VERSION ""

NS_ :

BS_:

BU_: ATCM_FFSM GENERIC_GWMWakeup IPMB Generic_BCM GWM _delete ABS_ESC HUD IPMA CCM PSCM SCCM TBM OCS TCCM TSTR RCM

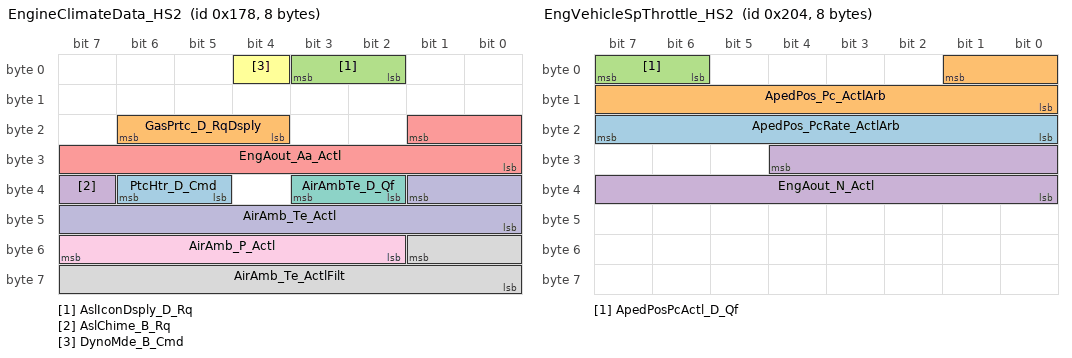
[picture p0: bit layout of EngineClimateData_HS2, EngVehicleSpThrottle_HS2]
BO_ 376 EngineClimateData_HS2: 8 GWM
 SG_ PtcHtr_D_Cmd : 38|2@0+ (1,0) [0|3] "SED" Vector__XXX
 SG_ GasPrtc_D_RqDsply : 22|3@0+ (1,0) [0|7] "SED" Vector__XXX
 SG_ AslIconDsply_D_Rq : 3|2@0+ (1,0) [0|3] "SED" Vector__XXX
 SG_ AslChime_B_Rq : 39|1@0+ (1,0) [0|1] "SED" Vector__XXX
 SG_ EngAout_Aa_Actl : 17|10@0+ (0.05,-25.6) [-25.6|25.55] "rpm/ms" Vector__XXX
 SG_ DynoMde_B_Cmd : 4|1@0+ (1,0) [0|1] "SED"  ABS_ESC
 SG_ AirAmbTe_D_Qf : 35|2@0+ (1,0) [0|3] "SED"  ABS_ESC,IPMA,TCCM,SCCM
 SG_ AirAmb_Te_ActlFilt : 49|10@0+ (0.25,-128) [-128|127.75] "deg C"  IPMA
 SG_ AirAmb_P_Actl : 55|6@0+ (10,500) [500|1110] "mbar" Vector__XXX
 SG_ AirAmb_Te_Actl : 33|10@0+ (0.25,-128) [-128|127.75] "degC"  ABS_ESC,TCCM,SCCM

BO_ 516 EngVehicleSpThrottle_HS2: 8 GWM
 SG_ ApedPos_PcRate_ActlArb : 23|8@0+ (0.04,-5) [-5|5.12] "%/ms" Vector__XXX
 SG_ ApedPos_Pc_ActlArb : 1|10@0+ (0.1,0) [0|102.3] "%"  IPMA,PSCM,TCCM,ABS_ESC,CCM,OCS,RCM
 SG_ ApedPosPcActl_D_Qf : 7|2@0+ (1,0) [0|3] "SED"  IPMA,PSCM,ABS_ESC,OCS,CCM,RCM
 SG_ EngAout_N_Actl : 28|13@0+ (2,0) [0|16382] "rpm"  PSCM,TCCM,ABS_ESC,RCM

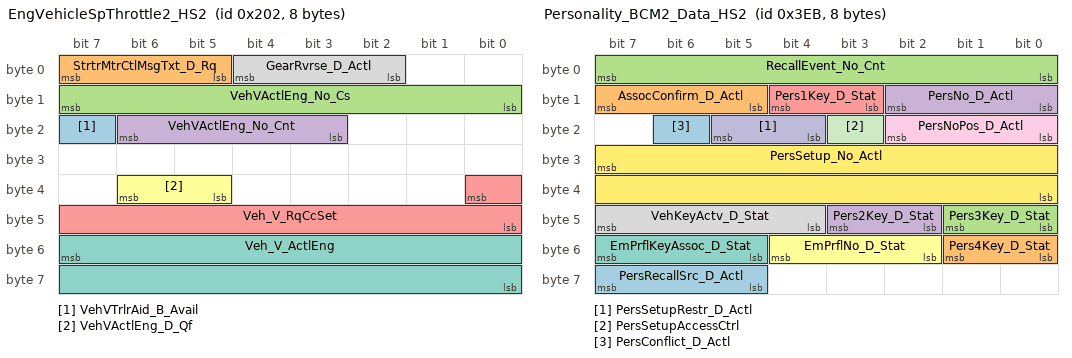
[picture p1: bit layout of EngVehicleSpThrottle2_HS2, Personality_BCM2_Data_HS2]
BO_ 514 EngVehicleSpThrottle2_HS2: 8 GWM
 SG_ VehVTrlrAid_B_Avail : 23|1@0+ (1,0) [0|1] "SED"  PSCM
 SG_ StrtrMtrCtlMsgTxt_D_Rq : 7|3@0+ (1,0) [0|7] "SED" Vector__XXX
 SG_ VehVActlEng_No_Cs : 15|8@0+ (1,0) [0|255] "Unitless"  PSCM
 SG_ VehVActlEng_No_Cnt : 22|4@0+ (1,0) [0|15] "Unitless"  PSCM
 SG_ Veh_V_RqCcSet : 32|9@0+ (0.5,0) [0|255.5] "kph"  IPMA,CCM
 SG_ VehVActlEng_D_Qf : 38|2@0+ (1,0) [0|3] "SED"  IPMB,ABS_ESC,SCCM,RCM,OCS,CCM,IPMA,PSCM,HUD
 SG_ Veh_V_ActlEng : 55|16@0+ (0.01,0) [0|655.35] "kph"  ABS_ESC,IPMB,TBM,RCM,OCS,CCM,SCCM,PSCM,IPMA,HUD
 SG_ GearRvrse_D_Actl : 4|3@0+ (1,0) [0|7] "SED"  ABS_ESC,IPMB,RCM,CCM,IPMA,OCS,SCCM,PSCM

BO_ 1003 Personality_BCM2_Data_HS2: 8 GWM
 SG_ PersRecallSrc_D_Actl : 63|3@0+ (1,0) [0|7] "SED" Vector__XXX
 SG_ Pers4Key_D_Stat : 49|2@0+ (1,0) [0|3] "SED" Vector__XXX
 SG_ Pers3Key_D_Stat : 41|2@0+ (1,0) [0|3] "SED" Vector__XXX
 SG_ Pers2Key_D_Stat : 43|2@0+ (1,0) [0|3] "SED" Vector__XXX
 SG_ Pers1Key_D_Stat : 12|2@0+ (1,0) [0|3] "SED" Vector__XXX
 SG_ EmPrflNo_D_Stat : 52|3@0+ (1,0) [0|7] "SED" Vector__XXX
 SG_ EmPrflKeyAssoc_D_Stat : 55|3@0+ (1,0) [0|7] "SED" Vector__XXX
 SG_ VehKeyActv_D_Stat : 47|4@0+ (1,0) [0|15] "SED" Vector__XXX
 SG_ PersNoPos_D_Actl : 18|3@0+ (1,0) [0|7] "SED" Vector__XXX
 SG_ PersSetupRestr_D_Actl : 21|2@0+ (1,0) [0|3] "SED"  CCM
 SG_ PersSetupAccessCtrl : 19|1@0+ (1,0) [0|1] "SED"  CCM
 SG_ PersSetup_No_Actl : 31|16@0+ (1,0) [0|65535] "Number"  CCM
 SG_ PersConflict_D_Actl : 22|1@0+ (1,0) [0|1] "SED" Vector__XXX
 SG_ AssocConfirm_D_Actl : 15|3@0+ (1,0) [0|7] "SED" Vector__XXX
 SG_ RecallEvent_No_Cnt : 7|8@0+ (1,0) [0|255] "Counts"  IPMA,CCM
 SG_ PersNo_D_Actl : 10|3@0+ (1,0) [0|7] "SED"  IPMA,CCM

BO_ 963 BCM_Lamp_Stat_HS2: 8 GWM
 SG_ WrlssAcsyChrgInhbt_B_Rq : 40|1@0+ (1,0) [0|1] "SED" Vector__XXX
 SG_ PudLampPsngr_D_Rq : 57|2@0+ (1,0) [0|3] "SED" Vector__XXX
 SG_ PudLampDrv_D_Rq : 59|2@0+ (1,0) [0|3] "SED" Vector__XXX
 SG_ Illuminated_Entry_Stat : 63|2@0+ (1,0) [0|3] "SED" Vector__XXX
 SG_ Dr_Courtesy_Light_Stat : 49|2@0+ (1,0) [0|3] "SED" Vector__XXX
 SG_ DrTgateLck_D_Stat : 61|2@0+ (1,0) [0|3] "SED" Vector__XXX
 SG_ Courtesy_Delay_Status : 51|2@0+ (1,0) [0|3] "SED" Vector__XXX
 SG_ ImpactEvntFdbck_D_Stat : 53|2@0+ (1,0) [0|3] "SED"  RCM
 SG_ HeadLampLoOut_B_Stat : 32|1@0+ (1,0) [0|1] "SED" Vector__XXX
 SG_ CrnrLghtRight_Pc_Rq : 47|7@0+ (1,0) [0|100] "percent" Vector__XXX
 SG_ CrnrLghtLeft_Pc_Rq : 39|7@0+ (1,0) [0|100] "percent" Vector__XXX
 SG_ HeadLghtHiFdbck_D_Stat : 55|2@0+ (1,0) [0|3] "SED"  SCCM
 SG_ PrkLightChime_B_Rq : 25|1@0+ (1,0) [0|1] "SED" Vector__XXX
 SG_ TrnNotInPrkChime_B_Rq : 24|1@0+ (1,0) [0|1] "SED" Vector__XXX
 SG_ KeyInIgnWarn_B_Cmd : 27|1@0+ (1,0) [0|1] "SED" Vector__XXX
 SG_ HomeSafeLtChime_B_Rq : 28|1@0+ (1,0) [0|1] "SED" Vector__XXX
 SG_ StopLghtOn_B_Stat : 8|1@0+ (1,0) [0|1] "SED" Vector__XXX
 SG_ RvrseLghtOn_B_Stat : 9|1@0+ (1,0) [0|1] "SED" Vector__XXX
 SG_ PrkLght_D_Stat : 13|2@0+ (1,0) [0|3] "SED" Vector__XXX
 SG_ HeadLghtSwtch_D_Stat : 15|2@0+ (1,0) [0|3] "SED"  IPMA
 SG_ HeadLampLoFrOn_B_Stat : 2|1@0+ (1,0) [0|1] "SED"  SCCM
 SG_ HeadLampLoFlOn_B_Stat : 3|1@0+ (1,0) [0|1] "SED"  SCCM
 SG_ HeadLampLoActv_B_Stat : 4|1@0+ (1,0) [0|1] "SED"  IPMA
 SG_ Headlamp_On_Wrning_Cmd : 29|1@0+ (1,0) [0|1] "SED" Vector__XXX
 SG_ HeadLghtHiOn_B_Stat : 1|1@0+ (1,0) [0|1] "SED"  IPMA
 SG_ Park_Brake_Chime_Rqst : 26|1@0+ (1,0) [0|1] "SED" Vector__XXX
 SG_ BrkWarnInd_B_Rq : 20|1@0+ (1,0) [0|1] "SED" Vector__XXX
 SG_ Brk_Fluid_Lvl_Low : 31|2@0+ (1,0) [0|3] "SED" Vector__XXX
 SG_ ReducedGuard_D_Stat : 19|2@0+ (1,0) [0|3] "SED" Vector__XXX
 SG_ Perimeter_Alarm_Status : 17|2@0+ (1,0) [0|3] "SED" Vector__XXX
 SG_ Courtesy_BSave_Stat : 7|2@0+ (1,0) [0|3] "SED" Vector__XXX
 SG_ DayRnngLampOn_B_Stat : 5|1@0+ (1,0) [0|1] "SED" Vector__XXX
 SG_ WndwGlbl_D_Cmd : 23|3@0+ (1,0) [0|7] "SED" Vector__XXX
 SG_ PudLamp_D_Rq : 11|2@0+ (1,0) [0|3] "SED" Vector__XXX
 SG_ PerimeterAlarmChimeRq : 0|1@0+ (1,0) [0|1] "SED" Vector__XXX

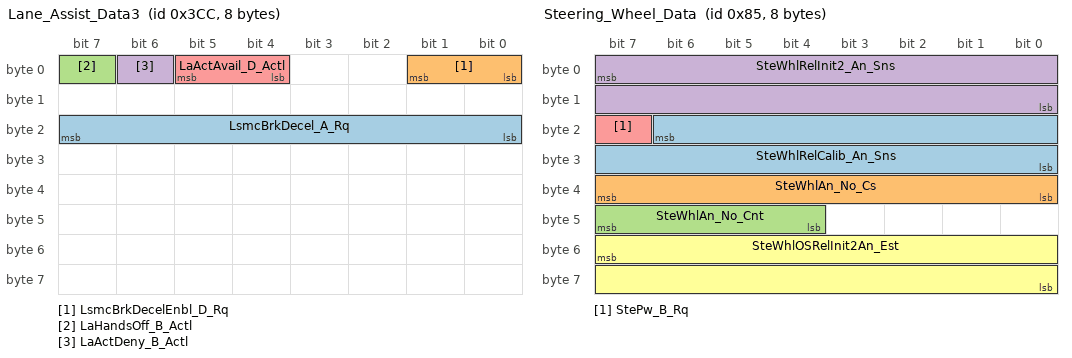
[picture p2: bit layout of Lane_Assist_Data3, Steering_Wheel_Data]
BO_ 972 Lane_Assist_Data3: 8 PSCM
 SG_ LsmcBrkDecel_A_Rq : 23|8@0+ (0.1,0) [0|25.5] "m/s^2"  ABS_ESC
 SG_ LsmcBrkDecelEnbl_D_Rq : 1|2@0+ (1,0) [0|3] "SED"  ABS_ESC
 SG_ LaHandsOff_B_Actl : 7|1@0+ (1,0) [0|1] "SED"  GWM,IPMA
 SG_ LaActDeny_B_Actl : 6|1@0+ (1,0) [0|1] "SED"  IPMA,GWM
 SG_ LaActAvail_D_Actl : 5|2@0+ (1,0) [0|3] "SED"  IPMA,GWM

BO_ 133 Steering_Wheel_Data: 8 PSCM
 SG_ SteWhlRelCalib_An_Sns : 22|15@0+ (0.1,-1600) [-1600|1676.5] "deg"  GWM
 SG_ SteWhlAn_No_Cs : 39|8@0+ (1,0) [0|255] "Unitless"  ABS_ESC,GWM
 SG_ SteWhlAn_No_Cnt : 47|4@0+ (1,0) [0|15] "Counts"  ABS_ESC,GWM
 SG_ SteWhlRelInit2_An_Sns : 7|16@0+ (0.1,-3200) [-3200|3353.3] "deg"  IPMA,SCCM,ABS_ESC,CCM,GWM
 SG_ StePw_B_Rq : 23|1@0+ (1,0) [0|1] "SED"  GWM
 SG_ SteWhlOSRelInit2An_Est : 55|16@0+ (0.1,-3200) [-3200|3353.3] "deg"  ABS_ESC,GWM

BO_ 1459 SCCM_AutoSar_Network_Mgmt: 8 SCCM
 SG_ SCCM_AutoSar_Network_Mgmt : 7|64@0+ (1,0) [0|1.84467E+019] "Unitless"  TCCM,TBM,ABS_ESC,GWM

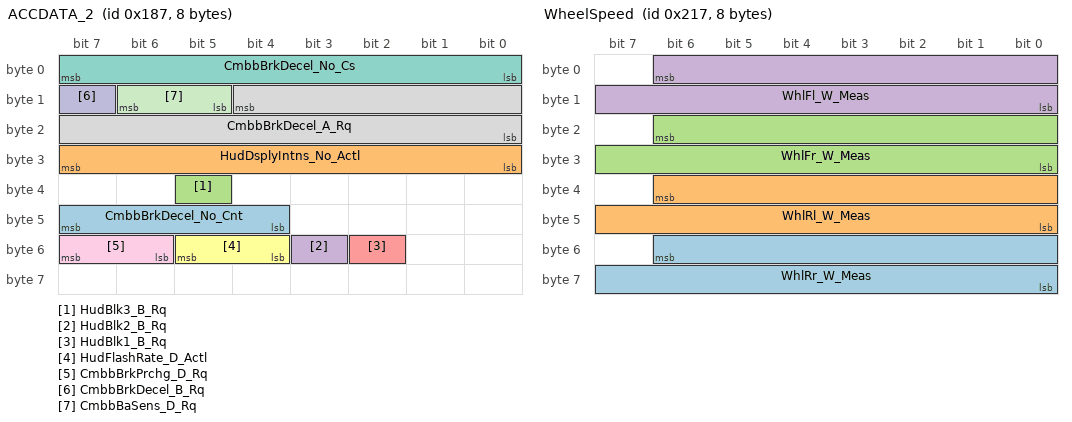
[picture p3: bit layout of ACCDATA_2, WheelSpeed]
BO_ 391 ACCDATA_2: 8 CCM
 SG_ CmbbBrkDecel_No_Cnt : 47|4@0+ (1,0) [0|15] "Unitless"  ABS_ESC
 SG_ HudDsplyIntns_No_Actl : 31|8@0+ (0.5,0) [0|100] "%"  HUD
 SG_ HudBlk3_B_Rq : 37|1@0+ (1,0) [0|1] "SED"  HUD
 SG_ HudBlk2_B_Rq : 51|1@0+ (1,0) [0|1] "SED"  HUD
 SG_ HudBlk1_B_Rq : 50|1@0+ (1,0) [0|1] "SED"  HUD
 SG_ HudFlashRate_D_Actl : 53|2@0+ (1,0) [0|3] "SED"  HUD
 SG_ CmbbBrkDecel_No_Cs : 7|8@0+ (1,0) [0|255] "Unitless"  ABS_ESC
 SG_ CmbbBrkDecel_A_Rq : 12|13@0+ (0.0039,-20) [-20|11.9449] "m/s^2"  GWM,ABS_ESC,RCM
 SG_ CmbbBrkPrchg_D_Rq : 55|2@0+ (1,0) [0|3] "SED"  GWM,ABS_ESC,RCM
 SG_ CmbbBrkDecel_B_Rq : 15|1@0+ (1,0) [0|1] "SED"  GWM,ABS_ESC,RCM
 SG_ CmbbBaSens_D_Rq : 14|2@0+ (1,0) [0|3] "SED"  ABS_ESC,RCM

BO_ 535 WheelSpeed: 8 ABS_ESC
 SG_ WhlRr_W_Meas : 54|15@0+ (0.01,0) [0|327.65] "rad/s"  IPMB,IPMA,TCCM,PSCM,GWM,CCM
 SG_ WhlRl_W_Meas : 38|15@0+ (0.01,0) [0|327.65] "rad/s"  IPMB,IPMA,TCCM,PSCM,GWM,CCM
 SG_ WhlFr_W_Meas : 22|15@0+ (0.01,0) [0|327.65] "rad/s"  IPMB,IPMA,TCCM,PSCM,GWM,CCM
 SG_ WhlFl_W_Meas : 6|15@0+ (0.01,0) [0|327.65] "rad/s"  IPMB,IPMA,TCCM,PSCM,GWM,CCM

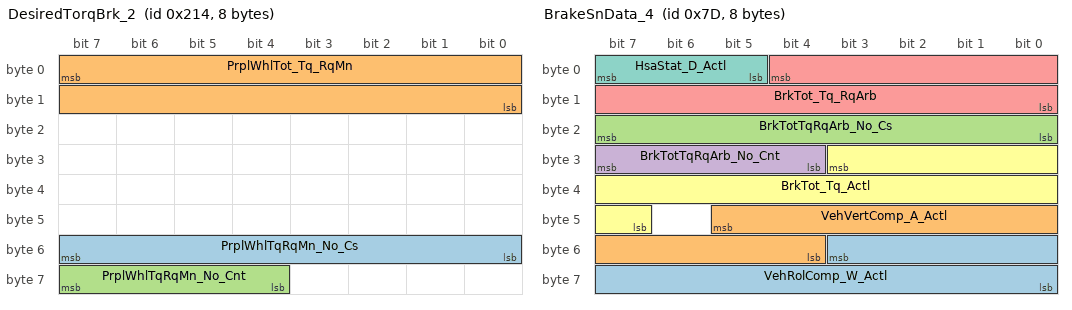
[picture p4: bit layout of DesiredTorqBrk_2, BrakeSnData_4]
BO_ 532 DesiredTorqBrk_2: 8 ABS_ESC
 SG_ PrplWhlTqRqMn_No_Cs : 55|8@0+ (1,0) [0|255] "Unitless"  GWM
 SG_ PrplWhlTot_Tq_RqMn : 7|16@0+ (4,-131072) [-131072|131068] "Nm"  GWM
 SG_ PrplWhlTqRqMn_No_Cnt : 63|4@0+ (1,0) [0|15] "Unitless"  GWM

BO_ 531 DesiredTorqBrk: 8 ABS_ESC
 SG_ VehicleStationary : 39|1@0+ (1,0) [0|1] "SED"  GWM,IPMA
 SG_ VehStop_D_Stat : 28|2@0+ (1,0) [0|3] "SED"  GWM,IPMA
 SG_ AccStopActv_B_ActlBrk : 22|1@0+ (1,0) [0|1] "SED"  GWM,IPMA
 SG_ AccDis_B_ActlEpb : 32|1@0+ (1,0) [0|1] "SED"  GWM,IPMA
 SG_ PrkBrkYwLamp_D_Rq : 38|2@0+ (1,0) [0|3] "SED"  GWM
 SG_ PrkBrkRedLamp_D_Rq : 30|2@0+ (1,0) [0|3] "SED"  GWM
 SG_ PrkBrkMsgTxt_D_Rq : 36|4@0+ (1,0) [0|15] "SED"  GWM
 SG_ TracCtlPtActv_B_Actl : 31|1@0+ (1,0) [0|1] "SED"  IPMA,GWM,TCCM,RCM,CCM
 SG_ AbsActv_B_Actl : 45|1@0+ (1,0) [0|1] "SED"  IPMA,TBM,RCM,CCM,GWM,PSCM
 SG_ StabCtlBrkActv_B_Actl : 23|1@0+ (1,0) [0|1] "SED"  IPMA,TCCM,PSCM,GWM,RCM,CCM
 SG_ CmbbBrkPrchg_B_Actl : 59|1@0+ (1,0) [0|1] "SED"  IPMA,TBM,GWM,CCM
 SG_ CmbbBrkDecel_B_Actl : 58|1@0+ (1,0) [0|1] "SED"  IPMA,TBM,GWM,CCM
 SG_ CmbbBaSensInc_B_Actl : 57|1@0+ (1,0) [0|1] "SED"  IPMA,GWM,CCM
 SG_ AccBrkWarm_B_Actl : 63|1@0+ (1,0) [0|1] "SED"  IPMA,GWM,CCM
 SG_ AccBrkTotTqMn_B_Actl : 62|1@0+ (1,0) [0|1] "SED"  IPMA,TBM,GWM,CCM
 SG_ AccBrkPrchgActv_B_Actl : 61|1@0+ (1,0) [0|1] "SED"  IPMA,GWM,CCM
 SG_ AccBrkDis_B_Actl : 44|1@0+ (1,0) [0|1] "SED"  IPMA,GWM,CCM
 SG_ AccBrkDeny_B_Actl : 42|1@0+ (1,0) [0|1] "SED"  IPMA,GWM,CCM
 SG_ AccBrkActv_B_Actl : 43|1@0+ (1,0) [0|1] "SED"  IPMA,GWM,CCM
 SG_ PrplDrgCtlActv_B_Actl : 46|1@0+ (1,0) [0|1] "SED"  GWM
 SG_ PrplWhlTot_Tq_RqMx : 7|16@0+ (4,-131072) [-131072|131068] "Nm"  TCCM,GWM
 SG_ CmbbBrkDis_B_Actl : 56|1@0+ (1,0) [0|1] "SED"  IPMA,GWM,CCM
 SG_ CmbbDeny_B_ActlBrk : 60|1@0+ (1,0) [0|1] "SED"  IPMA,GWM,CCM
 SG_ CcDis_B_Cmd : 47|1@0+ (1,0) [0|1] "SED"  GWM
 SG_ VehLongOvrGnd_A_Est : 41|10@0+ (0.035,-17.9) [-17.9|17.835] "m/s^2"  IPMA,TCCM,TBM,GWM,CCM
 SG_ PrkBrkStatus : 26|3@0+ (1,0) [0|7] "SED"  IPMB,IPMA,GWM

BO_ 2015 TesterFunctionalReq_H2: 8 TSTR
 SG_ TesterFunctionalReq : 7|64@0+ (1,0) [0|1.84467E+019] ""  ATCM_FFSM,IPMB,RCM,OCS,TCCM,CCM,ABS_ESC,HUD,IPMA,PSCM,SCCM,TBM,GWM

BO_ 125 BrakeSnData_4: 8 ABS_ESC
 SG_ VehRolComp_W_Actl : 51|12@0+ (0.03663,-75) [-75|74.92659] "degrees/sec"  PSCM,GWM
 SG_ VehVertComp_A_Actl : 45|10@0+ (0.035,-17.9) [-17.9|17.835] "m/s^2"  PSCM,GWM
 SG_ BrkTotTqRqArb_No_Cs : 23|8@0+ (1,0) [0|255] "Unitless"  TBM,GWM
 SG_ BrkTotTqRqArb_No_Cnt : 31|4@0+ (1,0) [0|15] "Unitless"  TBM,GWM
 SG_ BrkTot_Tq_RqArb : 4|13@0+ (4,0) [0|32756] "Nm"  IPMA,TBM,GWM,CCM
 SG_ BrkTot_Tq_Actl : 27|13@0+ (4,0) [0|32756] "Nm"  RCM,GWM
 SG_ HsaStat_D_Actl : 7|3@0+ (1,0) [0|7] "SED"  GWM

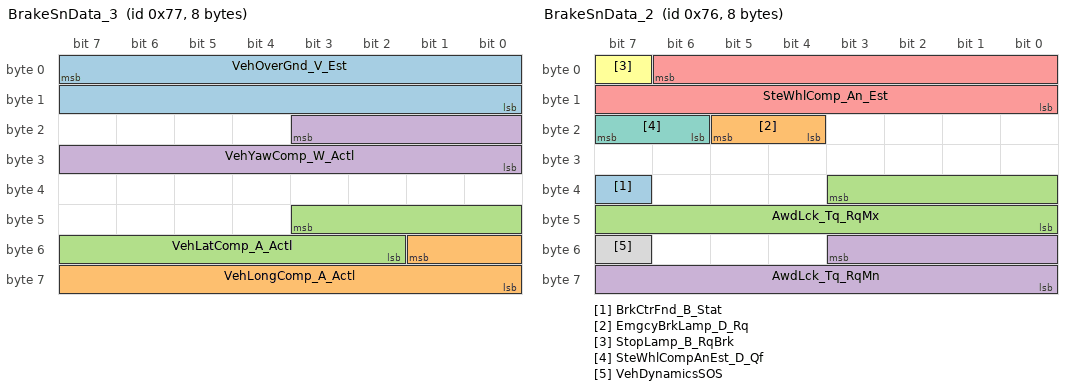
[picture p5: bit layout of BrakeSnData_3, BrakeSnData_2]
BO_ 119 BrakeSnData_3: 8 ABS_ESC
 SG_ VehOverGnd_V_Est : 7|16@0+ (0.01,0) [0|655.33] "kph"  IPMA,TCCM,GWM,CCM
 SG_ VehLongComp_A_Actl : 49|10@0+ (0.035,-17.9) [-17.9|17.835] "m/s^2"  PSCM,GWM
 SG_ VehLatComp_A_Actl : 43|10@0+ (0.035,-17.9) [-17.9|17.835] "m/s^2"  TCCM,PSCM,GWM
 SG_ VehYawComp_W_Actl : 19|12@0+ (0.03663,-75) [-75|74.92659] "deg/s"  IPMA,PSCM,GWM,CCM

BO_ 118 BrakeSnData_2: 8 ABS_ESC
 SG_ BrkCtrFnd_B_Stat : 39|1@0+ (1,0) [0|1] "SED"  PSCM,GWM
 SG_ EmgcyBrkLamp_D_Rq : 21|2@0+ (1,0) [0|3] "SED"  GWM
 SG_ AwdLck_Tq_RqMx : 35|12@0+ (1,0) [0|4095] "Nm"  TCCM,GWM
 SG_ AwdLck_Tq_RqMn : 51|12@0+ (1,0) [0|4095] "Nm"  TCCM,GWM
 SG_ SteWhlComp_An_Est : 6|15@0+ (0.1,-1600) [-1600|1676.7] "deg"  SCCM,IPMB,TCCM,RCM,IPMA,PSCM,GWM,CCM
 SG_ StopLamp_B_RqBrk : 7|1@0+ (1,0) [0|1] "SED"  GWM
 SG_ SteWhlCompAnEst_D_Qf : 23|2@0+ (1,0) [0|3] "SED"  SCCM,IPMB,TCCM,PSCM,GWM,IPMA,CCM
 SG_ VehDynamicsSOS : 55|1@0+ (1,0) [0|1] "SED"  GWM

BO_ 1713 ABS_Rapid_Data_Response_2: 8 ABS_ESC
 SG_ UUDTABSResponse2 : 7|64@0+ (1,0) [0|1.844674407371E+019] "unitless"  TSTR

BO_ 1712 ABS_Rapid_Data_Response_1: 8 ABS_ESC
 SG_ UUDTABSResponse1 : 7|64@0+ (1,0) [0|1.844674407371E+019] "unitless"  TSTR

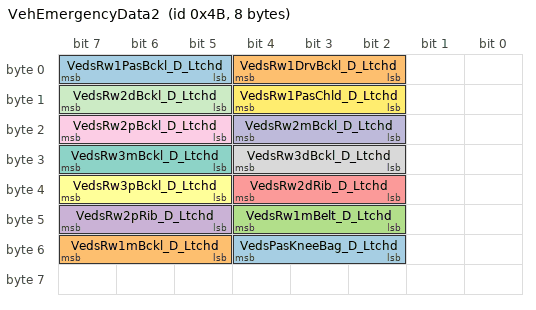
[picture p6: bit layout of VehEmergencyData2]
BO_ 75 VehEmergencyData2: 8 RCM
 SG_ VedsPasKneeBag_D_Ltchd : 52|3@0+ (1,0) [0|7] "SED"  GWM
 SG_ VedsRw1mBckl_D_Ltchd : 55|3@0+ (1,0) [0|7] "SED"  GWM
 SG_ VedsRw1mBelt_D_Ltchd : 44|3@0+ (1,0) [0|7] "SED"  GWM
 SG_ VedsRw2pRib_D_Ltchd : 47|3@0+ (1,0) [0|7] "SED"  GWM
 SG_ VedsRw2dRib_D_Ltchd : 36|3@0+ (1,0) [0|7] "SED"  GWM
 SG_ VedsRw3pBckl_D_Ltchd : 39|3@0+ (1,0) [0|7] "SED"  GWM
 SG_ VedsRw3mBckl_D_Ltchd : 31|3@0+ (1,0) [0|7] "SED"  GWM
 SG_ VedsRw3dBckl_D_Ltchd : 28|3@0+ (1,0) [0|7] "SED"  GWM
 SG_ VedsRw2pBckl_D_Ltchd : 23|3@0+ (1,0) [0|7] "SED"  GWM
 SG_ VedsRw2mBckl_D_Ltchd : 20|3@0+ (1,0) [0|7] "SED"  GWM
 SG_ VedsRw2dBckl_D_Ltchd : 15|3@0+ (1,0) [0|7] "SED"  GWM
 SG_ VedsRw1PasChld_D_Ltchd : 12|3@0+ (1,0) [0|7] "SED"  GWM
 SG_ VedsRw1PasBckl_D_Ltchd : 7|3@0+ (1,0) [0|7] "SED"  GWM
 SG_ VedsRw1DrvBckl_D_Ltchd : 4|3@0+ (1,0) [0|7] "SED"  GWM

BO_TX_BU_ 133 : SCCM,PSCM;
BO_TX_BU_ 391 : IPMA,CCM;
CM_ SG_ 376 EngAout_Aa_Actl "Signal not transmitted on HEV variants.";
CM_ SG_ 516 ApedPos_Pc_ActlArb "ABSGenSigTimeoutTime=1000";
CM_ SG_ 514 GearRvrse_D_Actl "Do not implement GearRvrse_D_Actl  until eTracker 8804151 is approved, 11/24/09";
CM_ SG_ 133 SteWhlRelCalib_An_Sns "Signal is not transmitted on vehicles where PSCM is transmitting the message that contains this signal.
Signal data set to 0x0 for ABS only vehicle option content";
CM_ SG_ 133 SteWhlAn_No_Cs "Signal data set to 0x0 for ABS only vehicle option content";
CM_ SG_ 133 SteWhlAn_No_Cnt "Signal data set to 0x0 for ABS only vehicle option content";
CM_ SG_ 391 CmbbBrkDecel_A_Rq "ABSGenSigTimeoutTime=1000";
CM_ SG_ 391 CmbbBrkPrchg_D_Rq "ABSGenSigTimeoutTime=1000";
CM_ SG_ 391 CmbbBrkDecel_B_Rq "ABSGenSigTimeoutTime=1000";
CM_ SG_ 391 CmbbBaSens_D_Rq "ABSGenSigTimeoutTime=1000";
CM_ BO_ 532 "IC is NOT to use data in this message for displays, Used data from 415 instead.";
CM_ BO_ 531 "IC is NOT to use data in this message for displays, Used data from 415 instead.";
CM_ SG_ 531 VehLongOvrGnd_A_Est "CCMGenSigTimeoutTime=1000";
CM_ BO_ 2015 "OBDII Request ($7DF) messages are for FNOS 1.0.1 only.
Diagnostic Functional Addressing ($7DF) and Dual Rate Periodic messages are for FNOS I3 only.";
BA_DEF_ SG_  "U_UP375_MY19_Gas_Rx" ENUM  "No","Yes";
BA_DEF_ SG_  "U_UP375_MY19_Diesel_Rx" ENUM  "No","Yes";
BA_DEF_ SG_  "U_V36X_MY19_Rx" ENUM  "No","Yes";
BA_DEF_ SG_  "U_UP375_MY19_Gas_Tx" ENUM  "No","Yes";
BA_DEF_ SG_  "U_UP375_MY19_Diesel_Tx" ENUM  "No","Yes";
BA_DEF_ SG_  "U_V36X_MY19_Tx" ENUM  "No","Yes";
BA_DEF_ SG_  "U_UP375_MY18_Gas_Rx" ENUM  "No","Yes";
BA_DEF_ SG_  "U_UP375_MY18_Diesel_Rx" ENUM  "No","Yes";
BA_DEF_ SG_  "U_V36X_MY18_5_Gas_Rx" ENUM  "No","Yes";
BA_DEF_ SG_  "U_V36X_MY18_5_Hev_Rx" ENUM  "No","Yes";
BA_DEF_ SG_  "U_UP375_MY18_Gas_Tx" ENUM  "No","Yes";
BA_DEF_ SG_  "U_UP375_MY18_Diesel_Tx" ENUM  "No","Yes";
BA_DEF_ SG_  "U_V36X_MY18_5_Gas_Tx" ENUM  "No","Yes";
BA_DEF_ SG_  "U_V36X_MY18_5_Hev_Tx" ENUM  "No","Yes";
BA_DEF_ SG_  "GenSigTimeoutTime_HCM_HS2" INT 0 100000;
BA_DEF_ SG_  "U_V36X_MY19_5_Diesel_Rx" ENUM  "No","Yes";
BA_DEF_ SG_  "U_V363E_N_MY19_5_20_Gas_Rx" ENUM  "No","Yes";
BA_DEF_ SG_  "U_V363E_N_MY19_5_20_Diesel_Rx" ENUM  "No","Yes";
BA_DEF_ SG_  "U_CD42_MY19_Diesel_Rx" ENUM  "No","Yes";
BA_DEF_ SG_  "U_CD42_MY19_Gas_Rx" ENUM  "No","Yes";
BA_DEF_ SG_  "U_V36X_MY19_5_Diesel_Tx" ENUM  "No","Yes";
BA_DEF_ SG_  "U_V363E_N_MY19_5_20_Gas_Tx" ENUM  "No","Yes";
BA_DEF_ SG_  "U_V363E_N_MY19_5_20_Diesel_Tx" ENUM  "No","Yes";
BA_DEF_ SG_  "U_CD42_MY19_Diesel_Tx" ENUM  "No","Yes";
BA_DEF_ SG_  "U_CD42_MY19_Gas_Tx" ENUM  "No","Yes";
BA_DEF_ BO_  "FrameGatewayNetworkold" ENUM  "None","HS1_CAN","HS2_CAN","HS3_CAN","MS1_CAN";
BA_DEF_ SG_  "U_B562_MY18_Gas_Rx" ENUM  "No","Yes";
BA_DEF_ SG_  "U_C490_MY18_Diesel_Rx" ENUM  "No","Yes";
BA_DEF_ SG_  "U_C490_MY18_Gas_Rx" ENUM  "No","Yes";
BA_DEF_ SG_  "U_V408_MY18_Gas_Rx" ENUM  "No","Yes";
BA_DEF_ SG_  "U_V408_MY18_Diesel_Rx" ENUM  "No","Yes";
BA_DEF_ SG_  "U_V36X_MY18_5_Diesel_Rx" ENUM  "No","Yes";
BA_DEF_ SG_  "U_V408_MY18_Gas_Tx" ENUM  "No","Yes";
BA_DEF_ SG_  "U_V408_MY18_Diesel_Tx" ENUM  "No","Yes";
BA_DEF_ SG_  "U_V36X_MY18_5_Diesel_Tx" ENUM  "No","Yes";
BA_DEF_ SG_  "U_P552_MY18_5_Gas_Tx" ENUM  "No","Yes";
BA_DEF_ SG_  "U_P552_MY18_5_Diesel_Tx" ENUM  "No","Yes";
BA_DEF_ SG_  "U_U502_MY17_Gas_Rx" ENUM  "No","Yes";
BA_DEF_ SG_  "U_S550_MY18_Gas_Rx" ENUM  "No","Yes";
BA_DEF_ SG_  "U_U502_MY17_Gas_Tx" ENUM  "No","Yes";
BA_DEF_ SG_  "U_S550_MY18_Gas_Tx" ENUM  "No","Yes";
BA_DEF_ SG_  "GenSigTimeoutTime_ATCM_FFSM" INT 0 100000;
BA_DEF_ SG_  "GenSigTimeoutTime_ATCM_DMSM" INT 0 100000;
BA_DEF_ SG_  "U_C489_MY17_Gas_Rx" ENUM  "No","Yes";
BA_DEF_ SG_  "U_P552_MY18_Gas_Rx" ENUM  "No","Yes";
BA_DEF_ SG_  "U_U55x_MY18_Gas_Rx" ENUM  "No","Yes";
BA_DEF_ SG_  "U_C489_MY17_Gas_Tx" ENUM  "No","Yes";
BA_DEF_ SG_  "U_P552_MY18_Gas_Tx" ENUM  "No","Yes";
BA_DEF_ SG_  "U_U55x_MY18_Gas_Tx" ENUM  "No","Yes";
BA_DEF_ BO_  "FrameGatewayNetwork" STRING ;
BA_DEF_ SG_  "U_CD43_MY17_Gas_Rx" ENUM  "No","Yes";
BA_DEF_ SG_  "U_P552_MY17_Gas_Rx" ENUM  "No","Yes";
BA_DEF_ SG_  "U_P552_MY17_Diesel_Rx" ENUM  "No","Yes";
BA_DEF_ SG_  "U_B515_MCA_MY17_Diesel_Rx" ENUM  "No","Yes";
BA_DEF_ SG_  "U_B515_MCA_MY17_Gas_Rx" ENUM  "No","Yes";
BA_DEF_ SG_  "U_CD43_MY17_Gas_Tx" ENUM  "No","Yes";
BA_DEF_ SG_  "U_P552_MY17_Gas_Tx" ENUM  "No","Yes";
BA_DEF_ SG_  "U_P552_MY17_Diesel_Tx" ENUM  "No","Yes";
BA_DEF_ SG_  "U_B515_MCA_MY17_Diesel_Tx" ENUM  "No","Yes";
BA_DEF_ SG_  "U_B515_MCA_MY17_Gas_Tx" ENUM  "No","Yes";
BA_DEF_ SG_  "U_B562LC_MY15_Diesel_Rx" ENUM  "No","Yes";
BA_DEF_ SG_  "U_B562LC_MY15_Gas_Rx" ENUM  "No","Yes";
BA_DEF_ SG_  "U_B479_MY17_Gas_Rx" ENUM  "No","Yes";
BA_DEF_ SG_  "U_B479_MY17_Diesel_Rx" ENUM  "No","Yes";
BA_DEF_ SG_  "U_CD4_MY17_Diesel_Rx" ENUM  "No","Yes";
BA_DEF_ SG_  "U_CD4_MY17_Gas_Rx" ENUM  "No","Yes";
BA_DEF_ SG_  "U_CD4_MY17_Hev_Rx" ENUM  "No","Yes";
BA_DEF_ SG_  "U_CD4_MY17_Phev_Rx" ENUM  "No","Yes";
BA_DEF_ SG_  "U_CD42_MY16_Diesel_Rx" ENUM  "No","Yes";
BA_DEF_ SG_  "U_CD42_MY16_Gas_Rx" ENUM  "No","Yes";
BA_DEF_ SG_  "U_B562LC_MY15_Diesel_Tx" ENUM  "No","Yes";
BA_DEF_ SG_  "U_B562LC_MY15_Gas_Tx" ENUM  "No","Yes";
BA_DEF_ SG_  "U_CD4_MY17_Diesel_Tx" ENUM  "No","Yes";
BA_DEF_ SG_  "U_CD4_MY17_Gas_Tx" ENUM  "No","Yes";
BA_DEF_ SG_  "U_CD4_MY17_Hev_Tx" ENUM  "No","Yes";
BA_DEF_ SG_  "U_CD4_MY17_Phev_Tx" ENUM  "No","Yes";
BA_DEF_ SG_  "U_CD42_MY16_Diesel_Tx" ENUM  "No","Yes";
BA_DEF_ SG_  "U_CD42_MY16_Gas_Tx" ENUM  "No","Yes";
BA_DEF_ SG_  "GenSigTimeoutTime_SECM" INT 0 100000;
BA_DEF_ BO_  "MessageGateway" ENUM  "No","Yes";
BA_DEF_ SG_  "U_CD42_MY15_Diesel_Rx" ENUM  "No","Yes";
BA_DEF_ SG_  "U_CD42_MY15_Gas_Rx" ENUM  "No","Yes";
BA_DEF_ SG_  "U_U502_MY16_Gas_Rx" ENUM  "No","Yes";
BA_DEF_ SG_  "U_P558_MY17_Gas_Rx" ENUM  "No","Yes";
BA_DEF_ SG_  "U_P558_MY17_Diesel_Rx" ENUM  "No","Yes";
BA_DEF_ SG_  "U_V36X_MY16_5_Diesel_Rx" ENUM  "No","Yes";
BA_DEF_ SG_  "U_CD42_MY15_Diesel_Tx" ENUM  "No","Yes";
BA_DEF_ SG_  "U_CD42_MY15_Gas_Tx" ENUM  "No","Yes";
BA_DEF_ SG_  "U_U502_MY16_Gas_Tx" ENUM  "No","Yes";
BA_DEF_ SG_  "U_P558_MY17_Gas_Tx" ENUM  "No","Yes";
BA_DEF_ SG_  "U_P558_MY17_Diesel_Tx" ENUM  "No","Yes";
BA_DEF_ SG_  "U_V36X_MY16_5_Diesel_Tx" ENUM  "No","Yes";
BA_DEF_ SG_  "GenSigTimeoutTime_VDM" INT 0 100000;
BA_DEF_ SG_  "GenSigTimeoutTime_ATCM" INT 0 100000;
BA_DEF_ SG_  "GenSigTimeoutTime_GENERIC" INT 0 100000;
BA_DEF_ SG_  "GenSigTimeoutTime_TRCM" INT 0 100000;
BA_DEF_ SG_  "GenSigTimeoutTime_GSM" INT 0 100000;
BA_DEF_ SG_  "GenSigTimeoutTime_FDSM" INT 0 100000;
BA_DEF_ SG_  "GenSigTimeoutTime_PCU" INT 0 100000;
BA_DEF_ SG_  "GenSigTimeoutTime_SASM" INT 0 100000;
BA_DEF_ SG_  "GenSigTimeoutTime_TCU_TBS" INT 0 100000;
BA_DEF_ SG_  "Gateway_ID" INT 0 0;
BA_DEF_ SG_  "GenSigTimeoutTime_IPMB" INT 0 100000;
BA_DEF_ SG_  "GenSigTimeoutTime__delete" INT 0 100000;
BA_DEF_ SG_  "GenSigTimeoutTime_PBM" INT 0 100000;
BA_DEF_ SG_  "GenSigTimeoutTime_TCCM" INT 0 100000;
BA_DEF_ SG_  "GenSigTimeoutTime_HUD" INT 0 100000;
BA_DEF_ SG_  "GenSigTimeoutTime_PSCM" INT 0 100000;
BA_DEF_ SG_  "GenSigTimeoutTime_SCCM" INT 0 100000;
BA_DEF_ SG_  "GenSigTimeoutTime_TBM" INT 0 100000;
BA_DEF_ SG_  "GenSigTimeoutTime_TSTR" INT 0 100000;
BA_DEF_ SG_  "GenSigTimeoutTime_IPMA" INT 0 100000;
BA_DEF_ SG_  "GenSigTimeoutTime_CCM" INT 0 100000;
BA_DEF_ SG_  "GenSigTimeoutTime_ABS_ESC" INT 0 100000;
BA_DEF_ SG_  "GenSigTimeoutTime_OCS" INT 0 100000;
BA_DEF_ SG_  "GenSigTimeoutTime_GWM" INT 0 100000;
BA_DEF_ SG_  "GenSigTimeoutTime_RCM" INT 0 100000;
BA_DEF_ BO_  "FrameGatewayMS1" HEX 0 1407;
BA_DEF_ BO_  "FrameGatewayHS3" HEX 0 1407;
BA_DEF_ BO_  "FrameGatewayHS1" HEX 0 1407;
BA_DEF_ BO_  "NetworkInitialization" ENUM  "No","Yes";
BA_DEF_ BO_  "FrameGatewayId" HEX 0 1407;
BA_DEF_ BO_  "EventRateOfChange" INT 10 10000;
BA_DEF_ BO_  "GenMsgStartDelayTime" INT 0 10000;
BA_DEF_ BO_  "GenMsgNrOfRepetition" INT 0 100;
BA_DEF_ BO_  "GenMsgDelayTime" INT 0 1000;
BA_DEF_ BO_  "GenMsgCycleTime" INT 0 100000;
BA_DEF_ BO_  "GenMsgSendType" ENUM  "FixedPeriodic","Event","EnabledPeriodic","NotUsed","NotUsed","EventPeriodic","NotUsed","NotUsed","NoMsgSendType";
BA_DEF_ SG_  "U_CD4_MY14_Phev_Tx" ENUM  "No","Yes";
BA_DEF_ SG_  "U_CD4_MY14_Hev_Tx" ENUM  "No","Yes";
BA_DEF_ SG_  "U_CD4_MY14_Gas_Tx" ENUM  "No","Yes";
BA_DEF_ SG_  "U_CD4_MY14_Diesel_Tx" ENUM  "No","Yes";
BA_DEF_ SG_  "U_CD43_MY16_Gas_Tx" ENUM  "No","Yes";
BA_DEF_ SG_  "U_C490LC_MY15_Gas_Tx" ENUM  "No","Yes";
BA_DEF_ SG_  "U_UP375_MY15_Diesel_Tx" ENUM  "No","Yes";
BA_DEF_ SG_  "U_UP375_MY15_Gas_Tx" ENUM  "No","Yes";
BA_DEF_ SG_  "U_U502_MY15_Gas_Tx" ENUM  "No","Yes";
BA_DEF_ SG_  "U_B562LC_MY14_Gas_Tx" ENUM  "No","Yes";
BA_DEF_ SG_  "U_B562LC_MY14_Diesel_Tx" ENUM  "No","Yes";
BA_DEF_ SG_  "U_C489_MY14_Gas_Tx" ENUM  "No","Yes";
BA_DEF_ SG_  "U_S550_MY15_Gas_Tx" ENUM  "No","Yes";
BA_DEF_ SG_  "U_P552_MY15_Gas_Tx" ENUM  "No","Yes";
BA_DEF_ SG_  "U_CD42_MY14_Gas_Tx" ENUM  "No","Yes";
BA_DEF_ SG_  "U_CD42_MY14_Diesel_Tx" ENUM  "No","Yes";
BA_DEF_ SG_  "U_CD4_MY13_Phev_Tx" ENUM  "No","Yes";
BA_DEF_ SG_  "U_CD4_MY13_Hev_Tx" ENUM  "No","Yes";
BA_DEF_ SG_  "U_CD4_MY13_Gas_Tx" ENUM  "No","Yes";
BA_DEF_ SG_  "U_CD4_MY13_Diesel_Tx" ENUM  "No","Yes";
BA_DEF_ SG_  "U_CD4_MY14_Phev_Rx" ENUM  "No","Yes";
BA_DEF_ SG_  "U_CD4_MY14_Hev_Rx" ENUM  "No","Yes";
BA_DEF_ SG_  "U_CD4_MY14_Gas_Rx" ENUM  "No","Yes";
BA_DEF_ SG_  "U_CD4_MY14_Diesel_Rx" ENUM  "No","Yes";
BA_DEF_ SG_  "U_CD43_MY16_Gas_Rx" ENUM  "No","Yes";
BA_DEF_ SG_  "U_UP375_MY15_Diesel_Rx" ENUM  "No","Yes";
BA_DEF_ SG_  "U_UP375_MY15_Gas_Rx" ENUM  "No","Yes";
BA_DEF_ SG_  "U_B479_MY15_Gas_Rx" ENUM  "No","Yes";
BA_DEF_ SG_  "U_U502_MY15_Gas_Rx" ENUM  "No","Yes";
BA_DEF_ SG_  "U_B562LC_MY14_Gas_Rx" ENUM  "No","Yes";
BA_DEF_ SG_  "U_B562LC_MY14_Diesel_Rx" ENUM  "No","Yes";
BA_DEF_ SG_  "U_C489_MY14_Gas_Rx" ENUM  "No","Yes";
BA_DEF_ SG_  "U_S550_MY15_Gas_Rx" ENUM  "No","Yes";
BA_DEF_ SG_  "U_P552_MY15_Gas_Rx" ENUM  "No","Yes";
BA_DEF_ SG_  "U_CD42_MY14_Gas_Rx" ENUM  "No","Yes";
BA_DEF_ SG_  "U_CD42_MY14_Diesel_Rx" ENUM  "No","Yes";
BA_DEF_ SG_  "U_CD4_MY13_Phev_Rx" ENUM  "No","Yes";
BA_DEF_ SG_  "U_CD4_MY13_Hev_Rx" ENUM  "No","Yes";
BA_DEF_ SG_  "U_CD4_MY13_Gas_Rx" ENUM  "No","Yes";
BA_DEF_ SG_  "U_CD4_MY13_Diesel_Rx" ENUM  "No","Yes";
BA_DEF_ SG_  "ContentDependant" ENUM  "No","Yes";
BA_DEF_ SG_  "GenSigStartValue" INT 0 1000000000;
BA_DEF_ SG_  "UsedOnPgmDBC" ENUM  "No","Yes";
BA_DEF_ SG_  "CrossOver_LIN" ENUM  "No","Yes";
BA_DEF_ SG_  "CrossOver_InfoCAN" ENUM  "No","Yes";
BA_DEF_ SG_  "WakeupSignal" ENUM  "No","Yes";
BA_DEF_ SG_  "FMC_SIG_SSPEC" STRING ;
BA_DEF_ SG_  "GenSigMissingSourceValue" INT 0 1000000000;
BA_DEF_ SG_  "GenSigSendType" ENUM  "Cyclic","OnWrite","vector_leerstring","OnChange","vector_leerstring","IfActive","vector_leerstring","NoSigSendType";
BA_DEF_ BO_  "NmAsrMessage" ENUM  "No","Yes";
BA_DEF_ BO_  "TpApplType" STRING ;
BA_DEF_ BO_  "DiagState" ENUM  "No","Yes";
BA_DEF_ BO_  "DiagRequest" ENUM  "No","Yes";
BA_DEF_ BO_  "DiagResponse" ENUM  "No","Yes";
BA_DEF_ BO_  "GenMsgILSupport" ENUM  "No","Yes";
BA_DEF_DEF_  "U_UP375_MY19_Gas_Rx" "No";
BA_DEF_DEF_  "U_UP375_MY19_Diesel_Rx" "No";
BA_DEF_DEF_  "U_V36X_MY19_Rx" "No";
BA_DEF_DEF_  "U_UP375_MY19_Gas_Tx" "No";
BA_DEF_DEF_  "U_UP375_MY19_Diesel_Tx" "No";
BA_DEF_DEF_  "U_V36X_MY19_Tx" "No";
BA_DEF_DEF_  "U_UP375_MY18_Gas_Rx" "No";
BA_DEF_DEF_  "U_UP375_MY18_Diesel_Rx" "No";
BA_DEF_DEF_  "U_V36X_MY18_5_Gas_Rx" "No";
BA_DEF_DEF_  "U_V36X_MY18_5_Hev_Rx" "No";
BA_DEF_DEF_  "U_UP375_MY18_Gas_Tx" "No";
BA_DEF_DEF_  "U_UP375_MY18_Diesel_Tx" "No";
BA_DEF_DEF_  "U_V36X_MY18_5_Gas_Tx" "No";
BA_DEF_DEF_  "U_V36X_MY18_5_Hev_Tx" "No";
BA_DEF_DEF_  "GenSigTimeoutTime_HCM_HS2" 5000;
BA_DEF_DEF_  "U_V36X_MY19_5_Diesel_Rx" "No";
BA_DEF_DEF_  "U_V363E_N_MY19_5_20_Gas_Rx" "No";
BA_DEF_DEF_  "U_V363E_N_MY19_5_20_Diesel_Rx" "No";
BA_DEF_DEF_  "U_CD42_MY19_Diesel_Rx" "No";
BA_DEF_DEF_  "U_CD42_MY19_Gas_Rx" "No";
BA_DEF_DEF_  "U_V36X_MY19_5_Diesel_Tx" "No";
BA_DEF_DEF_  "U_V363E_N_MY19_5_20_Gas_Tx" "No";
BA_DEF_DEF_  "U_V363E_N_MY19_5_20_Diesel_Tx" "No";
BA_DEF_DEF_  "U_CD42_MY19_Diesel_Tx" "No";
BA_DEF_DEF_  "U_CD42_MY19_Gas_Tx" "No";
BA_DEF_DEF_  "FrameGatewayNetworkold" "None";
BA_DEF_DEF_  "U_B562_MY18_Gas_Rx" "No";
BA_DEF_DEF_  "U_C490_MY18_Diesel_Rx" "No";
BA_DEF_DEF_  "U_C490_MY18_Gas_Rx" "No";
BA_DEF_DEF_  "U_V408_MY18_Gas_Rx" "No";
BA_DEF_DEF_  "U_V408_MY18_Diesel_Rx" "No";
BA_DEF_DEF_  "U_V36X_MY18_5_Diesel_Rx" "No";
BA_DEF_DEF_  "U_V408_MY18_Gas_Tx" "No";
BA_DEF_DEF_  "U_V408_MY18_Diesel_Tx" "No";
BA_DEF_DEF_  "U_V36X_MY18_5_Diesel_Tx" "No";
BA_DEF_DEF_  "U_P552_MY18_5_Gas_Tx" "No";
BA_DEF_DEF_  "U_P552_MY18_5_Diesel_Tx" "No";
BA_DEF_DEF_  "U_U502_MY17_Gas_Rx" "No";
BA_DEF_DEF_  "U_S550_MY18_Gas_Rx" "No";
BA_DEF_DEF_  "U_U502_MY17_Gas_Tx" "No";
BA_DEF_DEF_  "U_S550_MY18_Gas_Tx" "No";
BA_DEF_DEF_  "GenSigTimeoutTime_ATCM_FFSM" 5000;
BA_DEF_DEF_  "GenSigTimeoutTime_ATCM_DMSM" 5000;
BA_DEF_DEF_  "U_C489_MY17_Gas_Rx" "No";
BA_DEF_DEF_  "U_P552_MY18_Gas_Rx" "No";
BA_DEF_DEF_  "U_U55x_MY18_Gas_Rx" "No";
BA_DEF_DEF_  "U_C489_MY17_Gas_Tx" "No";
BA_DEF_DEF_  "U_P552_MY18_Gas_Tx" "No";
BA_DEF_DEF_  "U_U55x_MY18_Gas_Tx" "No";
BA_DEF_DEF_  "FrameGatewayNetwork" "NONE";
BA_DEF_DEF_  "U_CD43_MY17_Gas_Rx" "No";
BA_DEF_DEF_  "U_P552_MY17_Gas_Rx" "No";
BA_DEF_DEF_  "U_P552_MY17_Diesel_Rx" "No";
BA_DEF_DEF_  "U_B515_MCA_MY17_Diesel_Rx" "No";
BA_DEF_DEF_  "U_B515_MCA_MY17_Gas_Rx" "No";
BA_DEF_DEF_  "U_CD43_MY17_Gas_Tx" "No";
BA_DEF_DEF_  "U_P552_MY17_Gas_Tx" "No";
BA_DEF_DEF_  "U_P552_MY17_Diesel_Tx" "No";
BA_DEF_DEF_  "U_B515_MCA_MY17_Diesel_Tx" "No";
BA_DEF_DEF_  "U_B515_MCA_MY17_Gas_Tx" "No";
BA_DEF_DEF_  "U_B562LC_MY15_Diesel_Rx" "No";
BA_DEF_DEF_  "U_B562LC_MY15_Gas_Rx" "No";
BA_DEF_DEF_  "U_B479_MY17_Gas_Rx" "No";
BA_DEF_DEF_  "U_B479_MY17_Diesel_Rx" "No";
BA_DEF_DEF_  "U_CD4_MY17_Diesel_Rx" "No";
BA_DEF_DEF_  "U_CD4_MY17_Gas_Rx" "No";
BA_DEF_DEF_  "U_CD4_MY17_Hev_Rx" "No";
BA_DEF_DEF_  "U_CD4_MY17_Phev_Rx" "No";
BA_DEF_DEF_  "U_CD42_MY16_Diesel_Rx" "No";
BA_DEF_DEF_  "U_CD42_MY16_Gas_Rx" "No";
BA_DEF_DEF_  "U_B562LC_MY15_Diesel_Tx" "No";
BA_DEF_DEF_  "U_B562LC_MY15_Gas_Tx" "No";
BA_DEF_DEF_  "U_CD4_MY17_Diesel_Tx" "No";
BA_DEF_DEF_  "U_CD4_MY17_Gas_Tx" "No";
BA_DEF_DEF_  "U_CD4_MY17_Hev_Tx" "No";
BA_DEF_DEF_  "U_CD4_MY17_Phev_Tx" "No";
BA_DEF_DEF_  "U_CD42_MY16_Diesel_Tx" "No";
BA_DEF_DEF_  "U_CD42_MY16_Gas_Tx" "No";
BA_DEF_DEF_  "GenSigTimeoutTime_SECM" 5000;
BA_DEF_DEF_  "MessageGateway" "No";
BA_DEF_DEF_  "U_CD42_MY15_Diesel_Rx" "No";
BA_DEF_DEF_  "U_CD42_MY15_Gas_Rx" "No";
BA_DEF_DEF_  "U_U502_MY16_Gas_Rx" "No";
BA_DEF_DEF_  "U_P558_MY17_Gas_Rx" "No";
BA_DEF_DEF_  "U_P558_MY17_Diesel_Rx" "No";
BA_DEF_DEF_  "U_V36X_MY16_5_Diesel_Rx" "No";
BA_DEF_DEF_  "U_CD42_MY15_Diesel_Tx" "No";
BA_DEF_DEF_  "U_CD42_MY15_Gas_Tx" "No";
BA_DEF_DEF_  "U_U502_MY16_Gas_Tx" "No";
BA_DEF_DEF_  "U_P558_MY17_Gas_Tx" "No";
BA_DEF_DEF_  "U_P558_MY17_Diesel_Tx" "No";
BA_DEF_DEF_  "U_V36X_MY16_5_Diesel_Tx" "No";
BA_DEF_DEF_  "GenSigTimeoutTime_VDM" 5000;
BA_DEF_DEF_  "GenSigTimeoutTime_ATCM" 5000;
BA_DEF_DEF_  "GenSigTimeoutTime_GENERIC" 5000;
BA_DEF_DEF_  "GenSigTimeoutTime_TRCM" 5000;
BA_DEF_DEF_  "GenSigTimeoutTime_GSM" 5000;
BA_DEF_DEF_  "GenSigTimeoutTime_FDSM" 5000;
BA_DEF_DEF_  "GenSigTimeoutTime_PCU" 5000;
BA_DEF_DEF_  "GenSigTimeoutTime_SASM" 5000;
BA_DEF_DEF_  "GenSigTimeoutTime_TCU_TBS" 5000;
BA_DEF_DEF_  "Gateway_ID" 0;
BA_DEF_DEF_  "GenSigTimeoutTime_IPMB" 5000;
BA_DEF_DEF_  "GenSigTimeoutTime__delete" 5000;
BA_DEF_DEF_  "GenSigTimeoutTime_PBM" 5000;
BA_DEF_DEF_  "GenSigTimeoutTime_TCCM" 5000;
BA_DEF_DEF_  "GenSigTimeoutTime_HUD" 5000;
BA_DEF_DEF_  "GenSigTimeoutTime_PSCM" 5000;
BA_DEF_DEF_  "GenSigTimeoutTime_SCCM" 5000;
BA_DEF_DEF_  "GenSigTimeoutTime_TBM" 5000;
BA_DEF_DEF_  "GenSigTimeoutTime_TSTR" 5000;
BA_DEF_DEF_  "GenSigTimeoutTime_IPMA" 5000;
BA_DEF_DEF_  "GenSigTimeoutTime_CCM" 5000;
BA_DEF_DEF_  "GenSigTimeoutTime_ABS_ESC" 5000;
BA_DEF_DEF_  "GenSigTimeoutTime_OCS" 5000;
BA_DEF_DEF_  "GenSigTimeoutTime_GWM" 5000;
BA_DEF_DEF_  "GenSigTimeoutTime_RCM" 5000;
BA_DEF_DEF_  "FrameGatewayMS1" 0;
BA_DEF_DEF_  "FrameGatewayHS3" 0;
BA_DEF_DEF_  "FrameGatewayHS1" 0;
BA_DEF_DEF_  "NetworkInitialization" "No";
BA_DEF_DEF_  "FrameGatewayId" 0;
BA_DEF_DEF_  "EventRateOfChange" 10000;
BA_DEF_DEF_  "GenMsgStartDelayTime" 0;
BA_DEF_DEF_  "GenMsgNrOfRepetition" 1;
BA_DEF_DEF_  "GenMsgDelayTime" 20;
BA_DEF_DEF_  "GenMsgCycleTime" 0;
BA_DEF_DEF_  "GenMsgSendType" "NoMsgSendType";
BA_DEF_DEF_  "U_CD4_MY14_Phev_Tx" "No";
BA_DEF_DEF_  "U_CD4_MY14_Hev_Tx" "No";
BA_DEF_DEF_  "U_CD4_MY14_Gas_Tx" "No";
BA_DEF_DEF_  "U_CD4_MY14_Diesel_Tx" "No";
BA_DEF_DEF_  "U_CD43_MY16_Gas_Tx" "No";
BA_DEF_DEF_  "U_C490LC_MY15_Gas_Tx" "No";
BA_DEF_DEF_  "U_UP375_MY15_Diesel_Tx" "No";
BA_DEF_DEF_  "U_UP375_MY15_Gas_Tx" "No";
BA_DEF_DEF_  "U_U502_MY15_Gas_Tx" "No";
BA_DEF_DEF_  "U_B562LC_MY14_Gas_Tx" "No";
BA_DEF_DEF_  "U_B562LC_MY14_Diesel_Tx" "No";
BA_DEF_DEF_  "U_C489_MY14_Gas_Tx" "No";
BA_DEF_DEF_  "U_S550_MY15_Gas_Tx" "No";
BA_DEF_DEF_  "U_P552_MY15_Gas_Tx" "No";
BA_DEF_DEF_  "U_CD42_MY14_Gas_Tx" "No";
BA_DEF_DEF_  "U_CD42_MY14_Diesel_Tx" "No";
BA_DEF_DEF_  "U_CD4_MY13_Phev_Tx" "No";
BA_DEF_DEF_  "U_CD4_MY13_Hev_Tx" "No";
BA_DEF_DEF_  "U_CD4_MY13_Gas_Tx" "No";
BA_DEF_DEF_  "U_CD4_MY13_Diesel_Tx" "No";
BA_DEF_DEF_  "U_CD4_MY14_Phev_Rx" "No";
BA_DEF_DEF_  "U_CD4_MY14_Hev_Rx" "No";
BA_DEF_DEF_  "U_CD4_MY14_Gas_Rx" "No";
BA_DEF_DEF_  "U_CD4_MY14_Diesel_Rx" "No";
BA_DEF_DEF_  "U_CD43_MY16_Gas_Rx" "No";
BA_DEF_DEF_  "U_UP375_MY15_Diesel_Rx" "No";
BA_DEF_DEF_  "U_UP375_MY15_Gas_Rx" "No";
BA_DEF_DEF_  "U_B479_MY15_Gas_Rx" "No";
BA_DEF_DEF_  "U_U502_MY15_Gas_Rx" "No";
BA_DEF_DEF_  "U_B562LC_MY14_Gas_Rx" "No";
BA_DEF_DEF_  "U_B562LC_MY14_Diesel_Rx" "No";
BA_DEF_DEF_  "U_C489_MY14_Gas_Rx" "No";
BA_DEF_DEF_  "U_S550_MY15_Gas_Rx" "No";
BA_DEF_DEF_  "U_P552_MY15_Gas_Rx" "No";
BA_DEF_DEF_  "U_CD42_MY14_Gas_Rx" "No";
BA_DEF_DEF_  "U_CD42_MY14_Diesel_Rx" "No";
BA_DEF_DEF_  "U_CD4_MY13_Phev_Rx" "No";
BA_DEF_DEF_  "U_CD4_MY13_Hev_Rx" "No";
BA_DEF_DEF_  "U_CD4_MY13_Gas_Rx" "No";
BA_DEF_DEF_  "U_CD4_MY13_Diesel_Rx" "No";
BA_DEF_DEF_  "ContentDependant" "No";
BA_DEF_DEF_  "GenSigStartValue" 0;
BA_DEF_DEF_  "UsedOnPgmDBC" "Yes";
BA_DEF_DEF_  "CrossOver_LIN" "No";
BA_DEF_DEF_  "CrossOver_InfoCAN" "No";
BA_DEF_DEF_  "WakeupSignal" "No";
BA_DEF_DEF_  "FMC_SIG_SSPEC" "Unknown";
BA_DEF_DEF_  "GenSigMissingSourceValue" 0;
BA_DEF_DEF_  "GenSigSendType" "NoSigSendType";
BA_DEF_DEF_  "NmAsrMessage" "No";
BA_DEF_DEF_  "TpApplType" "";
BA_DEF_DEF_  "DiagState" "No";
BA_DEF_DEF_  "DiagRequest" "No";
BA_DEF_DEF_  "DiagResponse" "No";
BA_DEF_DEF_  "GenMsgILSupport" "Yes";
BA_ "NetworkInitialization" BO_ 376 1;
BA_ "GenMsgStartDelayTime" BO_ 376 300;
BA_ "FrameGatewayId" BO_ 376 376;
BA_ "FrameGatewayHS1" BO_ 376 376;
BA_ "FrameGatewayNetwork" BO_ 376 "HS1_CAN";
BA_ "GenMsgDelayTime" BO_ 516 5;
BA_ "FrameGatewayId" BO_ 516 516;
BA_ "FrameGatewayHS1" BO_ 516 516;
BA_ "FrameGatewayNetwork" BO_ 516 "HS1_CAN";
BA_ "GenMsgDelayTime" BO_ 514 5;
BA_ "FrameGatewayId" BO_ 514 514;
BA_ "FrameGatewayHS1" BO_ 514 514;
BA_ "FrameGatewayNetwork" BO_ 514 "HS1_CAN";
BA_ "FrameGatewayId" BO_ 1003 1003;
BA_ "FrameGatewayHS1" BO_ 1003 1003;
BA_ "FrameGatewayNetwork" BO_ 1003 "HS1_CAN";
BA_ "NetworkInitialization" BO_ 1003 1;
BA_ "GenMsgStartDelayTime" BO_ 963 300;
BA_ "FrameGatewayId" BO_ 963 963;
BA_ "FrameGatewayHS1" BO_ 963 963;
BA_ "FrameGatewayNetwork" BO_ 963 "HS1_CAN";
BA_ "NetworkInitialization" BO_ 963 1;
BA_ "GenMsgSendType" BO_ 972 0;
BA_ "GenMsgCycleTime" BO_ 972 30;
BA_ "GenMsgDelayTime" BO_ 972 10;
BA_ "GenMsgSendType" BO_ 133 0;
BA_ "GenMsgCycleTime" BO_ 133 10;
BA_ "GenMsgDelayTime" BO_ 133 0;
BA_ "MessageGateway" BO_ 133 1;
BA_ "NetworkInitialization" BO_ 133 1;
BA_ "GenMsgILSupport" BO_ 1459 0;
BA_ "NmAsrMessage" BO_ 1459 1;
BA_ "GenMsgSendType" BO_ 1459 1;
BA_ "GenMsgSendType" BO_ 391 0;
BA_ "GenMsgCycleTime" BO_ 391 20;
BA_ "GenMsgDelayTime" BO_ 391 10;
BA_ "NetworkInitialization" BO_ 391 1;
BA_ "GenMsgSendType" BO_ 535 0;
BA_ "GenMsgCycleTime" BO_ 535 10;
BA_ "GenMsgDelayTime" BO_ 535 0;
BA_ "GenMsgSendType" BO_ 532 0;
BA_ "GenMsgCycleTime" BO_ 532 20;
BA_ "GenMsgDelayTime" BO_ 532 10;
BA_ "NetworkInitialization" BO_ 531 1;
BA_ "GenMsgSendType" BO_ 531 0;
BA_ "GenMsgCycleTime" BO_ 531 20;
BA_ "GenMsgDelayTime" BO_ 531 10;
BA_ "GenMsgILSupport" BO_ 2015 0;
BA_ "DiagState" BO_ 2015 1;
BA_ "GenMsgSendType" BO_ 2015 1;
BA_ "GenMsgDelayTime" BO_ 2015 0;
BA_ "GenMsgSendType" BO_ 125 0;
BA_ "GenMsgCycleTime" BO_ 125 20;
BA_ "GenMsgDelayTime" BO_ 125 10;
BA_ "GenMsgSendType" BO_ 119 0;
BA_ "GenMsgCycleTime" BO_ 119 20;
BA_ "GenMsgDelayTime" BO_ 119 10;
BA_ "GenMsgSendType" BO_ 118 0;
BA_ "GenMsgCycleTime" BO_ 118 20;
BA_ "GenMsgDelayTime" BO_ 118 10;
BA_ "GenMsgILSupport" BO_ 1713 0;
BA_ "TpApplType" BO_ 1713 "DiagUUDTResponse";
BA_ "GenMsgSendType" BO_ 1713 1;
BA_ "GenMsgDelayTime" BO_ 1713 10;
BA_ "GenMsgILSupport" BO_ 1712 0;
BA_ "TpApplType" BO_ 1712 "DiagUUDTResponse";
BA_ "GenMsgSendType" BO_ 1712 1;
BA_ "GenMsgDelayTime" BO_ 1712 10;
BA_ "GenMsgSendType" BO_ 75 5;
BA_ "GenMsgCycleTime" BO_ 75 100;
BA_ "GenMsgDelayTime" BO_ 75 10;
BA_ "GenMsgStartDelayTime" BO_ 75 70;
BA_ "CrossOver_InfoCAN" SG_ 376 EngAout_Aa_Actl 1;
BA_ "ContentDependant" SG_ 376 EngAout_Aa_Actl 1;
BA_ "U_CD4_MY13_Diesel_Rx" SG_ 376 DynoMde_B_Cmd 1;
BA_ "U_CD4_MY13_Gas_Rx" SG_ 376 DynoMde_B_Cmd 1;
BA_ "U_CD4_MY13_Hev_Rx" SG_ 376 DynoMde_B_Cmd 1;
BA_ "U_CD4_MY13_Phev_Rx" SG_ 376 DynoMde_B_Cmd 1;
BA_ "U_CD42_MY14_Diesel_Rx" SG_ 376 DynoMde_B_Cmd 1;
BA_ "U_CD42_MY14_Gas_Rx" SG_ 376 DynoMde_B_Cmd 1;
BA_ "U_P552_MY15_Gas_Rx" SG_ 376 DynoMde_B_Cmd 1;
BA_ "U_S550_MY15_Gas_Rx" SG_ 376 DynoMde_B_Cmd 1;
BA_ "U_C489_MY14_Gas_Rx" SG_ 376 DynoMde_B_Cmd 1;
BA_ "U_U502_MY15_Gas_Rx" SG_ 376 DynoMde_B_Cmd 1;
BA_ "U_CD43_MY16_Gas_Rx" SG_ 376 DynoMde_B_Cmd 1;
BA_ "CrossOver_InfoCAN" SG_ 376 AirAmbTe_D_Qf 1;
BA_ "U_CD4_MY13_Diesel_Rx" SG_ 376 AirAmbTe_D_Qf 1;
BA_ "U_CD4_MY13_Gas_Rx" SG_ 376 AirAmbTe_D_Qf 1;
BA_ "U_CD4_MY13_Hev_Rx" SG_ 376 AirAmbTe_D_Qf 1;
BA_ "U_CD4_MY13_Phev_Rx" SG_ 376 AirAmbTe_D_Qf 1;
BA_ "U_CD42_MY14_Diesel_Rx" SG_ 376 AirAmbTe_D_Qf 1;
BA_ "U_CD42_MY14_Gas_Rx" SG_ 376 AirAmbTe_D_Qf 1;
BA_ "U_P552_MY15_Gas_Rx" SG_ 376 AirAmbTe_D_Qf 1;
BA_ "U_S550_MY15_Gas_Rx" SG_ 376 AirAmbTe_D_Qf 1;
BA_ "U_C489_MY14_Gas_Rx" SG_ 376 AirAmbTe_D_Qf 1;
BA_ "U_U502_MY15_Gas_Rx" SG_ 376 AirAmbTe_D_Qf 1;
BA_ "U_UP375_MY15_Gas_Rx" SG_ 376 AirAmbTe_D_Qf 1;
BA_ "U_UP375_MY15_Diesel_Rx" SG_ 376 AirAmbTe_D_Qf 1;
BA_ "U_CD43_MY16_Gas_Rx" SG_ 376 AirAmbTe_D_Qf 1;
BA_ "CrossOver_InfoCAN" SG_ 376 AirAmb_Te_ActlFilt 1;
BA_ "GenSigStartValue" SG_ 376 AirAmb_Te_ActlFilt 512;
BA_ "U_CD4_MY13_Diesel_Rx" SG_ 376 AirAmb_Te_ActlFilt 1;
BA_ "U_CD4_MY13_Gas_Rx" SG_ 376 AirAmb_Te_ActlFilt 1;
BA_ "U_CD4_MY13_Hev_Rx" SG_ 376 AirAmb_Te_ActlFilt 1;
BA_ "U_CD4_MY13_Phev_Rx" SG_ 376 AirAmb_Te_ActlFilt 1;
BA_ "U_CD42_MY14_Diesel_Rx" SG_ 376 AirAmb_Te_ActlFilt 1;
BA_ "U_CD42_MY14_Gas_Rx" SG_ 376 AirAmb_Te_ActlFilt 1;
BA_ "U_P552_MY15_Gas_Rx" SG_ 376 AirAmb_Te_ActlFilt 1;
BA_ "U_C489_MY14_Gas_Rx" SG_ 376 AirAmb_Te_ActlFilt 1;
BA_ "U_U502_MY15_Gas_Rx" SG_ 376 AirAmb_Te_ActlFilt 1;
BA_ "U_UP375_MY15_Gas_Rx" SG_ 376 AirAmb_Te_ActlFilt 1;
BA_ "U_UP375_MY15_Diesel_Rx" SG_ 376 AirAmb_Te_ActlFilt 1;
BA_ "U_CD43_MY16_Gas_Rx" SG_ 376 AirAmb_Te_ActlFilt 1;
BA_ "U_CD4_MY14_Diesel_Rx" SG_ 376 AirAmb_Te_ActlFilt 1;
BA_ "U_CD4_MY14_Gas_Rx" SG_ 376 AirAmb_Te_ActlFilt 1;
BA_ "U_CD4_MY14_Hev_Rx" SG_ 376 AirAmb_Te_ActlFilt 1;
BA_ "U_CD4_MY14_Phev_Rx" SG_ 376 AirAmb_Te_ActlFilt 1;
BA_ "CrossOver_InfoCAN" SG_ 376 AirAmb_P_Actl 1;
BA_ "CrossOver_InfoCAN" SG_ 376 AirAmb_Te_Actl 1;
BA_ "GenSigStartValue" SG_ 376 AirAmb_Te_Actl 512;
BA_ "U_CD4_MY13_Diesel_Rx" SG_ 376 AirAmb_Te_Actl 1;
BA_ "U_CD4_MY13_Gas_Rx" SG_ 376 AirAmb_Te_Actl 1;
BA_ "U_CD4_MY13_Hev_Rx" SG_ 376 AirAmb_Te_Actl 1;
BA_ "U_CD4_MY13_Phev_Rx" SG_ 376 AirAmb_Te_Actl 1;
BA_ "U_CD42_MY14_Diesel_Rx" SG_ 376 AirAmb_Te_Actl 1;
BA_ "U_CD42_MY14_Gas_Rx" SG_ 376 AirAmb_Te_Actl 1;
BA_ "U_P552_MY15_Gas_Rx" SG_ 376 AirAmb_Te_Actl 1;
BA_ "U_S550_MY15_Gas_Rx" SG_ 376 AirAmb_Te_Actl 1;
BA_ "U_C489_MY14_Gas_Rx" SG_ 376 AirAmb_Te_Actl 1;
BA_ "U_U502_MY15_Gas_Rx" SG_ 376 AirAmb_Te_Actl 1;
BA_ "U_UP375_MY15_Gas_Rx" SG_ 376 AirAmb_Te_Actl 1;
BA_ "U_UP375_MY15_Diesel_Rx" SG_ 376 AirAmb_Te_Actl 1;
BA_ "U_CD43_MY16_Gas_Rx" SG_ 376 AirAmb_Te_Actl 1;
BA_ "CrossOver_InfoCAN" SG_ 516 ApedPos_PcRate_ActlArb 1;
BA_ "CrossOver_InfoCAN" SG_ 516 ApedPos_Pc_ActlArb 1;
BA_ "U_CD4_MY13_Diesel_Rx" SG_ 516 ApedPos_Pc_ActlArb 1;
BA_ "U_CD4_MY13_Gas_Rx" SG_ 516 ApedPos_Pc_ActlArb 1;
BA_ "U_CD4_MY13_Hev_Rx" SG_ 516 ApedPos_Pc_ActlArb 1;
BA_ "U_CD4_MY13_Phev_Rx" SG_ 516 ApedPos_Pc_ActlArb 1;
BA_ "U_CD42_MY14_Diesel_Rx" SG_ 516 ApedPos_Pc_ActlArb 1;
BA_ "U_CD42_MY14_Gas_Rx" SG_ 516 ApedPos_Pc_ActlArb 1;
BA_ "U_P552_MY15_Gas_Rx" SG_ 516 ApedPos_Pc_ActlArb 1;
BA_ "U_U502_MY15_Gas_Rx" SG_ 516 ApedPos_Pc_ActlArb 1;
BA_ "U_UP375_MY15_Gas_Rx" SG_ 516 ApedPos_Pc_ActlArb 1;
BA_ "U_UP375_MY15_Diesel_Rx" SG_ 516 ApedPos_Pc_ActlArb 1;
BA_ "U_CD43_MY16_Gas_Rx" SG_ 516 ApedPos_Pc_ActlArb 1;
BA_ "U_CD4_MY14_Diesel_Rx" SG_ 516 ApedPos_Pc_ActlArb 1;
BA_ "U_CD4_MY14_Gas_Rx" SG_ 516 ApedPos_Pc_ActlArb 1;
BA_ "U_CD4_MY14_Hev_Rx" SG_ 516 ApedPos_Pc_ActlArb 1;
BA_ "U_CD4_MY14_Phev_Rx" SG_ 516 ApedPos_Pc_ActlArb 1;
BA_ "GenSigTimeoutTime_OCS" SG_ 516 ApedPos_Pc_ActlArb 6000;
BA_ "GenSigTimeoutTime_CCM" SG_ 516 ApedPos_Pc_ActlArb 1000;
BA_ "GenSigTimeoutTime_ABS_ESC" SG_ 516 ApedPos_Pc_ActlArb 1000;
BA_ "CrossOver_InfoCAN" SG_ 516 ApedPosPcActl_D_Qf 1;
BA_ "U_CD4_MY13_Diesel_Rx" SG_ 516 ApedPosPcActl_D_Qf 1;
BA_ "U_CD4_MY13_Gas_Rx" SG_ 516 ApedPosPcActl_D_Qf 1;
BA_ "U_CD4_MY13_Hev_Rx" SG_ 516 ApedPosPcActl_D_Qf 1;
BA_ "U_CD4_MY13_Phev_Rx" SG_ 516 ApedPosPcActl_D_Qf 1;
BA_ "U_CD42_MY14_Diesel_Rx" SG_ 516 ApedPosPcActl_D_Qf 1;
BA_ "U_CD42_MY14_Gas_Rx" SG_ 516 ApedPosPcActl_D_Qf 1;
BA_ "U_P552_MY15_Gas_Rx" SG_ 516 ApedPosPcActl_D_Qf 1;
BA_ "U_S550_MY15_Gas_Rx" SG_ 516 ApedPosPcActl_D_Qf 1;
BA_ "U_C489_MY14_Gas_Rx" SG_ 516 ApedPosPcActl_D_Qf 1;
BA_ "U_U502_MY15_Gas_Rx" SG_ 516 ApedPosPcActl_D_Qf 1;
BA_ "U_UP375_MY15_Gas_Rx" SG_ 516 ApedPosPcActl_D_Qf 1;
BA_ "U_UP375_MY15_Diesel_Rx" SG_ 516 ApedPosPcActl_D_Qf 1;
BA_ "U_CD43_MY16_Gas_Rx" SG_ 516 ApedPosPcActl_D_Qf 1;
BA_ "U_CD4_MY14_Diesel_Rx" SG_ 516 ApedPosPcActl_D_Qf 1;
BA_ "U_CD4_MY14_Gas_Rx" SG_ 516 ApedPosPcActl_D_Qf 1;
BA_ "U_CD4_MY14_Hev_Rx" SG_ 516 ApedPosPcActl_D_Qf 1;
BA_ "U_CD4_MY14_Phev_Rx" SG_ 516 ApedPosPcActl_D_Qf 1;
BA_ "GenSigTimeoutTime_OCS" SG_ 516 ApedPosPcActl_D_Qf 6000;
BA_ "CrossOver_InfoCAN" SG_ 516 EngAout_N_Actl 1;
BA_ "U_CD4_MY13_Diesel_Rx" SG_ 516 EngAout_N_Actl 1;
BA_ "U_CD4_MY13_Gas_Rx" SG_ 516 EngAout_N_Actl 1;
BA_ "U_CD4_MY13_Hev_Rx" SG_ 516 EngAout_N_Actl 1;
BA_ "U_CD4_MY13_Phev_Rx" SG_ 516 EngAout_N_Actl 1;
BA_ "U_CD42_MY14_Diesel_Rx" SG_ 516 EngAout_N_Actl 1;
BA_ "U_CD42_MY14_Gas_Rx" SG_ 516 EngAout_N_Actl 1;
BA_ "U_P552_MY15_Gas_Rx" SG_ 516 EngAout_N_Actl 1;
BA_ "U_S550_MY15_Gas_Rx" SG_ 516 EngAout_N_Actl 1;
BA_ "U_C489_MY14_Gas_Rx" SG_ 516 EngAout_N_Actl 1;
BA_ "U_U502_MY15_Gas_Rx" SG_ 516 EngAout_N_Actl 1;
BA_ "U_UP375_MY15_Gas_Rx" SG_ 516 EngAout_N_Actl 1;
BA_ "U_UP375_MY15_Diesel_Rx" SG_ 516 EngAout_N_Actl 1;
BA_ "U_CD43_MY16_Gas_Rx" SG_ 516 EngAout_N_Actl 1;
BA_ "U_P552_MY15_Gas_Rx" SG_ 514 VehVTrlrAid_B_Avail 1;
BA_ "CrossOver_InfoCAN" SG_ 514 StrtrMtrCtlMsgTxt_D_Rq 1;
BA_ "CrossOver_InfoCAN" SG_ 514 VehVActlEng_No_Cs 1;
BA_ "U_CD4_MY13_Diesel_Rx" SG_ 514 VehVActlEng_No_Cs 1;
BA_ "U_CD4_MY13_Gas_Rx" SG_ 514 VehVActlEng_No_Cs 1;
BA_ "U_CD4_MY13_Hev_Rx" SG_ 514 VehVActlEng_No_Cs 1;
BA_ "U_CD4_MY13_Phev_Rx" SG_ 514 VehVActlEng_No_Cs 1;
BA_ "U_CD42_MY14_Diesel_Rx" SG_ 514 VehVActlEng_No_Cs 1;
BA_ "U_CD42_MY14_Gas_Rx" SG_ 514 VehVActlEng_No_Cs 1;
BA_ "U_P552_MY15_Gas_Rx" SG_ 514 VehVActlEng_No_Cs 1;
BA_ "U_S550_MY15_Gas_Rx" SG_ 514 VehVActlEng_No_Cs 1;
BA_ "U_C489_MY14_Gas_Rx" SG_ 514 VehVActlEng_No_Cs 1;
BA_ "U_U502_MY15_Gas_Rx" SG_ 514 VehVActlEng_No_Cs 1;
BA_ "U_UP375_MY15_Gas_Rx" SG_ 514 VehVActlEng_No_Cs 1;
BA_ "U_UP375_MY15_Diesel_Rx" SG_ 514 VehVActlEng_No_Cs 1;
BA_ "U_CD43_MY16_Gas_Rx" SG_ 514 VehVActlEng_No_Cs 1;
BA_ "CrossOver_InfoCAN" SG_ 514 VehVActlEng_No_Cnt 1;
BA_ "U_CD4_MY13_Diesel_Rx" SG_ 514 VehVActlEng_No_Cnt 1;
BA_ "U_CD4_MY13_Gas_Rx" SG_ 514 VehVActlEng_No_Cnt 1;
BA_ "U_CD4_MY13_Hev_Rx" SG_ 514 VehVActlEng_No_Cnt 1;
BA_ "U_CD4_MY13_Phev_Rx" SG_ 514 VehVActlEng_No_Cnt 1;
BA_ "U_CD42_MY14_Diesel_Rx" SG_ 514 VehVActlEng_No_Cnt 1;
BA_ "U_CD42_MY14_Gas_Rx" SG_ 514 VehVActlEng_No_Cnt 1;
BA_ "U_P552_MY15_Gas_Rx" SG_ 514 VehVActlEng_No_Cnt 1;
BA_ "U_S550_MY15_Gas_Rx" SG_ 514 VehVActlEng_No_Cnt 1;
BA_ "U_C489_MY14_Gas_Rx" SG_ 514 VehVActlEng_No_Cnt 1;
BA_ "U_U502_MY15_Gas_Rx" SG_ 514 VehVActlEng_No_Cnt 1;
BA_ "U_UP375_MY15_Gas_Rx" SG_ 514 VehVActlEng_No_Cnt 1;
BA_ "U_UP375_MY15_Diesel_Rx" SG_ 514 VehVActlEng_No_Cnt 1;
BA_ "U_CD43_MY16_Gas_Rx" SG_ 514 VehVActlEng_No_Cnt 1;
BA_ "CrossOver_InfoCAN" SG_ 514 Veh_V_RqCcSet 1;
BA_ "U_CD4_MY13_Diesel_Rx" SG_ 514 Veh_V_RqCcSet 1;
BA_ "U_CD4_MY13_Gas_Rx" SG_ 514 Veh_V_RqCcSet 1;
BA_ "U_CD4_MY13_Hev_Rx" SG_ 514 Veh_V_RqCcSet 1;
BA_ "U_CD4_MY13_Phev_Rx" SG_ 514 Veh_V_RqCcSet 1;
BA_ "U_CD42_MY14_Diesel_Rx" SG_ 514 Veh_V_RqCcSet 1;
BA_ "U_CD42_MY14_Gas_Rx" SG_ 514 Veh_V_RqCcSet 1;
BA_ "U_P552_MY15_Gas_Rx" SG_ 514 Veh_V_RqCcSet 1;
BA_ "U_S550_MY15_Gas_Rx" SG_ 514 Veh_V_RqCcSet 1;
BA_ "U_C489_MY14_Gas_Rx" SG_ 514 Veh_V_RqCcSet 1;
BA_ "U_U502_MY15_Gas_Rx" SG_ 514 Veh_V_RqCcSet 1;
BA_ "U_UP375_MY15_Gas_Rx" SG_ 514 Veh_V_RqCcSet 1;
BA_ "U_UP375_MY15_Diesel_Rx" SG_ 514 Veh_V_RqCcSet 1;
BA_ "U_CD43_MY16_Gas_Rx" SG_ 514 Veh_V_RqCcSet 1;
BA_ "CrossOver_InfoCAN" SG_ 514 VehVActlEng_D_Qf 1;
BA_ "U_CD4_MY13_Diesel_Rx" SG_ 514 VehVActlEng_D_Qf 1;
BA_ "U_CD4_MY13_Gas_Rx" SG_ 514 VehVActlEng_D_Qf 1;
BA_ "U_CD4_MY13_Hev_Rx" SG_ 514 VehVActlEng_D_Qf 1;
BA_ "U_CD4_MY13_Phev_Rx" SG_ 514 VehVActlEng_D_Qf 1;
BA_ "U_CD42_MY14_Diesel_Rx" SG_ 514 VehVActlEng_D_Qf 1;
BA_ "U_CD42_MY14_Gas_Rx" SG_ 514 VehVActlEng_D_Qf 1;
BA_ "U_P552_MY15_Gas_Rx" SG_ 514 VehVActlEng_D_Qf 1;
BA_ "U_C489_MY14_Gas_Rx" SG_ 514 VehVActlEng_D_Qf 1;
BA_ "U_U502_MY15_Gas_Rx" SG_ 514 VehVActlEng_D_Qf 1;
BA_ "U_UP375_MY15_Gas_Rx" SG_ 514 VehVActlEng_D_Qf 1;
BA_ "U_UP375_MY15_Diesel_Rx" SG_ 514 VehVActlEng_D_Qf 1;
BA_ "U_CD43_MY16_Gas_Rx" SG_ 514 VehVActlEng_D_Qf 1;
BA_ "U_CD4_MY14_Diesel_Rx" SG_ 514 VehVActlEng_D_Qf 1;
BA_ "U_CD4_MY14_Gas_Rx" SG_ 514 VehVActlEng_D_Qf 1;
BA_ "U_CD4_MY14_Hev_Rx" SG_ 514 VehVActlEng_D_Qf 1;
BA_ "U_CD4_MY14_Phev_Rx" SG_ 514 VehVActlEng_D_Qf 1;
BA_ "U_S550_MY15_Gas_Rx" SG_ 514 VehVActlEng_D_Qf 1;
BA_ "GenSigTimeoutTime_OCS" SG_ 514 VehVActlEng_D_Qf 6000;
BA_ "CrossOver_InfoCAN" SG_ 514 Veh_V_ActlEng 1;
BA_ "CrossOver_LIN" SG_ 514 Veh_V_ActlEng 1;
BA_ "U_CD4_MY13_Diesel_Rx" SG_ 514 Veh_V_ActlEng 1;
BA_ "U_CD4_MY13_Gas_Rx" SG_ 514 Veh_V_ActlEng 1;
BA_ "U_CD4_MY13_Hev_Rx" SG_ 514 Veh_V_ActlEng 1;
BA_ "U_CD4_MY13_Phev_Rx" SG_ 514 Veh_V_ActlEng 1;
BA_ "U_CD42_MY14_Diesel_Rx" SG_ 514 Veh_V_ActlEng 1;
BA_ "U_CD42_MY14_Gas_Rx" SG_ 514 Veh_V_ActlEng 1;
BA_ "U_P552_MY15_Gas_Rx" SG_ 514 Veh_V_ActlEng 1;
BA_ "U_C489_MY14_Gas_Rx" SG_ 514 Veh_V_ActlEng 1;
BA_ "U_U502_MY15_Gas_Rx" SG_ 514 Veh_V_ActlEng 1;
BA_ "U_UP375_MY15_Gas_Rx" SG_ 514 Veh_V_ActlEng 1;
BA_ "U_UP375_MY15_Diesel_Rx" SG_ 514 Veh_V_ActlEng 1;
BA_ "U_CD43_MY16_Gas_Rx" SG_ 514 Veh_V_ActlEng 1;
BA_ "U_CD4_MY14_Diesel_Rx" SG_ 514 Veh_V_ActlEng 1;
BA_ "U_CD4_MY14_Gas_Rx" SG_ 514 Veh_V_ActlEng 1;
BA_ "U_CD4_MY14_Hev_Rx" SG_ 514 Veh_V_ActlEng 1;
BA_ "U_CD4_MY14_Phev_Rx" SG_ 514 Veh_V_ActlEng 1;
BA_ "U_S550_MY15_Gas_Rx" SG_ 514 Veh_V_ActlEng 1;
BA_ "GenSigTimeoutTime_OCS" SG_ 514 Veh_V_ActlEng 6000;
BA_ "GenSigTimeoutTime_RCM" SG_ 514 Veh_V_ActlEng 400;
BA_ "GenSigMissingSourceValue" SG_ 514 GearRvrse_D_Actl 3;
BA_ "CrossOver_InfoCAN" SG_ 514 GearRvrse_D_Actl 1;
BA_ "GenSigStartValue" SG_ 514 GearRvrse_D_Actl 7;
BA_ "U_CD4_MY13_Diesel_Rx" SG_ 514 GearRvrse_D_Actl 1;
BA_ "U_CD4_MY13_Gas_Rx" SG_ 514 GearRvrse_D_Actl 1;
BA_ "U_CD4_MY13_Hev_Rx" SG_ 514 GearRvrse_D_Actl 1;
BA_ "U_CD4_MY13_Phev_Rx" SG_ 514 GearRvrse_D_Actl 1;
BA_ "U_CD42_MY14_Diesel_Rx" SG_ 514 GearRvrse_D_Actl 1;
BA_ "U_CD42_MY14_Gas_Rx" SG_ 514 GearRvrse_D_Actl 1;
BA_ "U_P552_MY15_Gas_Rx" SG_ 514 GearRvrse_D_Actl 1;
BA_ "U_S550_MY15_Gas_Rx" SG_ 514 GearRvrse_D_Actl 1;
BA_ "U_C489_MY14_Gas_Rx" SG_ 514 GearRvrse_D_Actl 1;
BA_ "U_U502_MY15_Gas_Rx" SG_ 514 GearRvrse_D_Actl 1;
BA_ "U_UP375_MY15_Gas_Rx" SG_ 514 GearRvrse_D_Actl 1;
BA_ "U_UP375_MY15_Diesel_Rx" SG_ 514 GearRvrse_D_Actl 1;
BA_ "U_CD43_MY16_Gas_Rx" SG_ 514 GearRvrse_D_Actl 1;
BA_ "U_CD4_MY14_Diesel_Rx" SG_ 514 GearRvrse_D_Actl 1;
BA_ "U_CD4_MY14_Gas_Rx" SG_ 514 GearRvrse_D_Actl 1;
BA_ "U_CD4_MY14_Hev_Rx" SG_ 514 GearRvrse_D_Actl 1;
BA_ "U_CD4_MY14_Phev_Rx" SG_ 514 GearRvrse_D_Actl 1;
BA_ "GenSigTimeoutTime_OCS" SG_ 514 GearRvrse_D_Actl 6000;
BA_ "CrossOver_InfoCAN" SG_ 1003 PersNoPos_D_Actl 1;
BA_ "GenSigStartValue" SG_ 1003 PersNoPos_D_Actl 4;
BA_ "CrossOver_InfoCAN" SG_ 1003 PersSetupRestr_D_Actl 1;
BA_ "U_CD4_MY13_Diesel_Rx" SG_ 1003 PersSetupRestr_D_Actl 1;
BA_ "U_CD4_MY13_Gas_Rx" SG_ 1003 PersSetupRestr_D_Actl 1;
BA_ "U_CD4_MY13_Hev_Rx" SG_ 1003 PersSetupRestr_D_Actl 1;
BA_ "U_CD4_MY13_Phev_Rx" SG_ 1003 PersSetupRestr_D_Actl 1;
BA_ "U_CD42_MY14_Diesel_Rx" SG_ 1003 PersSetupRestr_D_Actl 1;
BA_ "U_CD42_MY14_Gas_Rx" SG_ 1003 PersSetupRestr_D_Actl 1;
BA_ "U_P552_MY15_Gas_Rx" SG_ 1003 PersSetupRestr_D_Actl 1;
BA_ "U_S550_MY15_Gas_Rx" SG_ 1003 PersSetupRestr_D_Actl 1;
BA_ "U_C489_MY14_Gas_Rx" SG_ 1003 PersSetupRestr_D_Actl 1;
BA_ "U_U502_MY15_Gas_Rx" SG_ 1003 PersSetupRestr_D_Actl 1;
BA_ "U_UP375_MY15_Gas_Rx" SG_ 1003 PersSetupRestr_D_Actl 1;
BA_ "U_UP375_MY15_Diesel_Rx" SG_ 1003 PersSetupRestr_D_Actl 1;
BA_ "U_CD43_MY16_Gas_Rx" SG_ 1003 PersSetupRestr_D_Actl 1;
BA_ "CrossOver_InfoCAN" SG_ 1003 PersSetupAccessCtrl 1;
BA_ "U_CD4_MY13_Diesel_Rx" SG_ 1003 PersSetupAccessCtrl 1;
BA_ "U_CD4_MY13_Gas_Rx" SG_ 1003 PersSetupAccessCtrl 1;
BA_ "U_CD4_MY13_Hev_Rx" SG_ 1003 PersSetupAccessCtrl 1;
BA_ "U_CD4_MY13_Phev_Rx" SG_ 1003 PersSetupAccessCtrl 1;
BA_ "U_CD42_MY14_Diesel_Rx" SG_ 1003 PersSetupAccessCtrl 1;
BA_ "U_CD42_MY14_Gas_Rx" SG_ 1003 PersSetupAccessCtrl 1;
BA_ "U_P552_MY15_Gas_Rx" SG_ 1003 PersSetupAccessCtrl 1;
BA_ "U_S550_MY15_Gas_Rx" SG_ 1003 PersSetupAccessCtrl 1;
BA_ "U_C489_MY14_Gas_Rx" SG_ 1003 PersSetupAccessCtrl 1;
BA_ "U_U502_MY15_Gas_Rx" SG_ 1003 PersSetupAccessCtrl 1;
BA_ "U_UP375_MY15_Gas_Rx" SG_ 1003 PersSetupAccessCtrl 1;
BA_ "U_UP375_MY15_Diesel_Rx" SG_ 1003 PersSetupAccessCtrl 1;
BA_ "U_CD43_MY16_Gas_Rx" SG_ 1003 PersSetupAccessCtrl 1;
BA_ "CrossOver_InfoCAN" SG_ 1003 PersSetup_No_Actl 1;
BA_ "U_CD4_MY13_Diesel_Rx" SG_ 1003 PersSetup_No_Actl 1;
BA_ "U_CD4_MY13_Gas_Rx" SG_ 1003 PersSetup_No_Actl 1;
BA_ "U_CD4_MY13_Hev_Rx" SG_ 1003 PersSetup_No_Actl 1;
BA_ "U_CD4_MY13_Phev_Rx" SG_ 1003 PersSetup_No_Actl 1;
BA_ "U_CD42_MY14_Diesel_Rx" SG_ 1003 PersSetup_No_Actl 1;
BA_ "U_CD42_MY14_Gas_Rx" SG_ 1003 PersSetup_No_Actl 1;
BA_ "U_P552_MY15_Gas_Rx" SG_ 1003 PersSetup_No_Actl 1;
BA_ "U_S550_MY15_Gas_Rx" SG_ 1003 PersSetup_No_Actl 1;
BA_ "U_C489_MY14_Gas_Rx" SG_ 1003 PersSetup_No_Actl 1;
BA_ "U_U502_MY15_Gas_Rx" SG_ 1003 PersSetup_No_Actl 1;
BA_ "U_UP375_MY15_Gas_Rx" SG_ 1003 PersSetup_No_Actl 1;
BA_ "U_UP375_MY15_Diesel_Rx" SG_ 1003 PersSetup_No_Actl 1;
BA_ "U_CD43_MY16_Gas_Rx" SG_ 1003 PersSetup_No_Actl 1;
BA_ "CrossOver_InfoCAN" SG_ 1003 PersConflict_D_Actl 1;
BA_ "GenSigStartValue" SG_ 1003 PersConflict_D_Actl 1;
BA_ "CrossOver_InfoCAN" SG_ 1003 AssocConfirm_D_Actl 1;
BA_ "CrossOver_InfoCAN" SG_ 1003 RecallEvent_No_Cnt 1;
BA_ "U_CD4_MY13_Diesel_Rx" SG_ 1003 RecallEvent_No_Cnt 1;
BA_ "U_CD4_MY13_Gas_Rx" SG_ 1003 RecallEvent_No_Cnt 1;
BA_ "U_CD4_MY13_Hev_Rx" SG_ 1003 RecallEvent_No_Cnt 1;
BA_ "U_CD4_MY13_Phev_Rx" SG_ 1003 RecallEvent_No_Cnt 1;
BA_ "U_CD42_MY14_Diesel_Rx" SG_ 1003 RecallEvent_No_Cnt 1;
BA_ "U_CD42_MY14_Gas_Rx" SG_ 1003 RecallEvent_No_Cnt 1;
BA_ "U_P552_MY15_Gas_Rx" SG_ 1003 RecallEvent_No_Cnt 1;
BA_ "U_S550_MY15_Gas_Rx" SG_ 1003 RecallEvent_No_Cnt 1;
BA_ "U_C489_MY14_Gas_Rx" SG_ 1003 RecallEvent_No_Cnt 1;
BA_ "U_U502_MY15_Gas_Rx" SG_ 1003 RecallEvent_No_Cnt 1;
BA_ "U_UP375_MY15_Gas_Rx" SG_ 1003 RecallEvent_No_Cnt 1;
BA_ "U_UP375_MY15_Diesel_Rx" SG_ 1003 RecallEvent_No_Cnt 1;
BA_ "U_CD43_MY16_Gas_Rx" SG_ 1003 RecallEvent_No_Cnt 1;
BA_ "CrossOver_InfoCAN" SG_ 1003 PersNo_D_Actl 1;
BA_ "GenSigStartValue" SG_ 1003 PersNo_D_Actl 4;
BA_ "U_CD4_MY13_Diesel_Rx" SG_ 1003 PersNo_D_Actl 1;
BA_ "U_CD4_MY13_Gas_Rx" SG_ 1003 PersNo_D_Actl 1;
BA_ "U_CD4_MY13_Hev_Rx" SG_ 1003 PersNo_D_Actl 1;
BA_ "U_CD4_MY13_Phev_Rx" SG_ 1003 PersNo_D_Actl 1;
BA_ "U_CD42_MY14_Diesel_Rx" SG_ 1003 PersNo_D_Actl 1;
BA_ "U_CD42_MY14_Gas_Rx" SG_ 1003 PersNo_D_Actl 1;
BA_ "U_P552_MY15_Gas_Rx" SG_ 1003 PersNo_D_Actl 1;
BA_ "U_S550_MY15_Gas_Rx" SG_ 1003 PersNo_D_Actl 1;
BA_ "U_C489_MY14_Gas_Rx" SG_ 1003 PersNo_D_Actl 1;
BA_ "U_U502_MY15_Gas_Rx" SG_ 1003 PersNo_D_Actl 1;
BA_ "U_UP375_MY15_Gas_Rx" SG_ 1003 PersNo_D_Actl 1;
BA_ "U_UP375_MY15_Diesel_Rx" SG_ 1003 PersNo_D_Actl 1;
BA_ "U_CD43_MY16_Gas_Rx" SG_ 1003 PersNo_D_Actl 1;
BA_ "WakeupSignal" SG_ 963 ImpactEvntFdbck_D_Stat 1;
BA_ "CrossOver_InfoCAN" SG_ 963 ImpactEvntFdbck_D_Stat 1;
BA_ "U_CD42_MY14_Diesel_Rx" SG_ 963 ImpactEvntFdbck_D_Stat 1;
BA_ "U_CD42_MY14_Gas_Rx" SG_ 963 ImpactEvntFdbck_D_Stat 1;
BA_ "U_P552_MY15_Gas_Rx" SG_ 963 ImpactEvntFdbck_D_Stat 1;
BA_ "U_S550_MY15_Gas_Rx" SG_ 963 ImpactEvntFdbck_D_Stat 1;
BA_ "U_U502_MY15_Gas_Rx" SG_ 963 ImpactEvntFdbck_D_Stat 1;
BA_ "U_UP375_MY15_Gas_Rx" SG_ 963 ImpactEvntFdbck_D_Stat 1;
BA_ "U_UP375_MY15_Diesel_Rx" SG_ 963 ImpactEvntFdbck_D_Stat 1;
BA_ "U_CD43_MY16_Gas_Rx" SG_ 963 ImpactEvntFdbck_D_Stat 1;
BA_ "CrossOver_InfoCAN" SG_ 963 HeadLampLoOut_B_Stat 1;
BA_ "CrossOver_InfoCAN" SG_ 963 CrnrLghtRight_Pc_Rq 1;
BA_ "CrossOver_InfoCAN" SG_ 963 CrnrLghtLeft_Pc_Rq 1;
BA_ "CrossOver_InfoCAN" SG_ 963 HeadLghtHiFdbck_D_Stat 1;
BA_ "U_CD4_MY13_Diesel_Rx" SG_ 963 HeadLghtHiFdbck_D_Stat 1;
BA_ "U_CD4_MY13_Gas_Rx" SG_ 963 HeadLghtHiFdbck_D_Stat 1;
BA_ "U_CD4_MY13_Hev_Rx" SG_ 963 HeadLghtHiFdbck_D_Stat 1;
BA_ "U_CD4_MY13_Phev_Rx" SG_ 963 HeadLghtHiFdbck_D_Stat 1;
BA_ "U_CD42_MY14_Diesel_Rx" SG_ 963 HeadLghtHiFdbck_D_Stat 1;
BA_ "U_CD42_MY14_Gas_Rx" SG_ 963 HeadLghtHiFdbck_D_Stat 1;
BA_ "U_P552_MY15_Gas_Rx" SG_ 963 HeadLghtHiFdbck_D_Stat 1;
BA_ "U_S550_MY15_Gas_Rx" SG_ 963 HeadLghtHiFdbck_D_Stat 1;
BA_ "U_C489_MY14_Gas_Rx" SG_ 963 HeadLghtHiFdbck_D_Stat 1;
BA_ "U_U502_MY15_Gas_Rx" SG_ 963 HeadLghtHiFdbck_D_Stat 1;
BA_ "U_UP375_MY15_Gas_Rx" SG_ 963 HeadLghtHiFdbck_D_Stat 1;
BA_ "U_UP375_MY15_Diesel_Rx" SG_ 963 HeadLghtHiFdbck_D_Stat 1;
BA_ "U_CD43_MY16_Gas_Rx" SG_ 963 HeadLghtHiFdbck_D_Stat 1;
BA_ "CrossOver_InfoCAN" SG_ 963 PrkLightChime_B_Rq 1;
BA_ "CrossOver_InfoCAN" SG_ 963 TrnNotInPrkChime_B_Rq 1;
BA_ "WakeupSignal" SG_ 963 KeyInIgnWarn_B_Cmd 1;
BA_ "CrossOver_InfoCAN" SG_ 963 KeyInIgnWarn_B_Cmd 1;
BA_ "WakeupSignal" SG_ 963 HomeSafeLtChime_B_Rq 1;
BA_ "CrossOver_InfoCAN" SG_ 963 HomeSafeLtChime_B_Rq 1;
BA_ "WakeupSignal" SG_ 963 StopLghtOn_B_Stat 1;
BA_ "CrossOver_InfoCAN" SG_ 963 StopLghtOn_B_Stat 1;
BA_ "CrossOver_LIN" SG_ 963 StopLghtOn_B_Stat 1;
BA_ "CrossOver_InfoCAN" SG_ 963 RvrseLghtOn_B_Stat 1;
BA_ "CrossOver_LIN" SG_ 963 RvrseLghtOn_B_Stat 1;
BA_ "WakeupSignal" SG_ 963 PrkLght_D_Stat 1;
BA_ "CrossOver_InfoCAN" SG_ 963 PrkLght_D_Stat 1;
BA_ "WakeupSignal" SG_ 963 HeadLghtSwtch_D_Stat 1;
BA_ "CrossOver_InfoCAN" SG_ 963 HeadLghtSwtch_D_Stat 1;
BA_ "GenSigStartValue" SG_ 963 HeadLghtSwtch_D_Stat 2;
BA_ "U_CD4_MY13_Diesel_Rx" SG_ 963 HeadLghtSwtch_D_Stat 1;
BA_ "U_CD4_MY13_Gas_Rx" SG_ 963 HeadLghtSwtch_D_Stat 1;
BA_ "U_CD4_MY13_Hev_Rx" SG_ 963 HeadLghtSwtch_D_Stat 1;
BA_ "U_CD4_MY13_Phev_Rx" SG_ 963 HeadLghtSwtch_D_Stat 1;
BA_ "U_CD42_MY14_Diesel_Rx" SG_ 963 HeadLghtSwtch_D_Stat 1;
BA_ "U_CD42_MY14_Gas_Rx" SG_ 963 HeadLghtSwtch_D_Stat 1;
BA_ "U_P552_MY15_Gas_Rx" SG_ 963 HeadLghtSwtch_D_Stat 1;
BA_ "U_C489_MY14_Gas_Rx" SG_ 963 HeadLghtSwtch_D_Stat 1;
BA_ "U_U502_MY15_Gas_Rx" SG_ 963 HeadLghtSwtch_D_Stat 1;
BA_ "U_UP375_MY15_Gas_Rx" SG_ 963 HeadLghtSwtch_D_Stat 1;
BA_ "U_UP375_MY15_Diesel_Rx" SG_ 963 HeadLghtSwtch_D_Stat 1;
BA_ "U_CD43_MY16_Gas_Rx" SG_ 963 HeadLghtSwtch_D_Stat 1;
BA_ "U_CD4_MY14_Diesel_Rx" SG_ 963 HeadLghtSwtch_D_Stat 1;
BA_ "U_CD4_MY14_Gas_Rx" SG_ 963 HeadLghtSwtch_D_Stat 1;
BA_ "U_CD4_MY14_Hev_Rx" SG_ 963 HeadLghtSwtch_D_Stat 1;
BA_ "U_CD4_MY14_Phev_Rx" SG_ 963 HeadLghtSwtch_D_Stat 1;
BA_ "CrossOver_InfoCAN" SG_ 963 HeadLampLoFrOn_B_Stat 1;
BA_ "GenSigStartValue" SG_ 963 HeadLampLoFrOn_B_Stat 1;
BA_ "U_CD4_MY13_Diesel_Rx" SG_ 963 HeadLampLoFrOn_B_Stat 1;
BA_ "U_CD4_MY13_Gas_Rx" SG_ 963 HeadLampLoFrOn_B_Stat 1;
BA_ "U_CD4_MY13_Hev_Rx" SG_ 963 HeadLampLoFrOn_B_Stat 1;
BA_ "U_CD4_MY13_Phev_Rx" SG_ 963 HeadLampLoFrOn_B_Stat 1;
BA_ "U_CD42_MY14_Diesel_Rx" SG_ 963 HeadLampLoFrOn_B_Stat 1;
BA_ "U_CD42_MY14_Gas_Rx" SG_ 963 HeadLampLoFrOn_B_Stat 1;
BA_ "U_P552_MY15_Gas_Rx" SG_ 963 HeadLampLoFrOn_B_Stat 1;
BA_ "U_S550_MY15_Gas_Rx" SG_ 963 HeadLampLoFrOn_B_Stat 1;
BA_ "U_C489_MY14_Gas_Rx" SG_ 963 HeadLampLoFrOn_B_Stat 1;
BA_ "U_U502_MY15_Gas_Rx" SG_ 963 HeadLampLoFrOn_B_Stat 1;
BA_ "U_UP375_MY15_Gas_Rx" SG_ 963 HeadLampLoFrOn_B_Stat 1;
BA_ "U_UP375_MY15_Diesel_Rx" SG_ 963 HeadLampLoFrOn_B_Stat 1;
BA_ "U_CD43_MY16_Gas_Rx" SG_ 963 HeadLampLoFrOn_B_Stat 1;
BA_ "CrossOver_InfoCAN" SG_ 963 HeadLampLoFlOn_B_Stat 1;
BA_ "GenSigStartValue" SG_ 963 HeadLampLoFlOn_B_Stat 1;
BA_ "U_CD4_MY13_Diesel_Rx" SG_ 963 HeadLampLoFlOn_B_Stat 1;
BA_ "U_CD4_MY13_Gas_Rx" SG_ 963 HeadLampLoFlOn_B_Stat 1;
BA_ "U_CD4_MY13_Hev_Rx" SG_ 963 HeadLampLoFlOn_B_Stat 1;
BA_ "U_CD4_MY13_Phev_Rx" SG_ 963 HeadLampLoFlOn_B_Stat 1;
BA_ "U_CD42_MY14_Diesel_Rx" SG_ 963 HeadLampLoFlOn_B_Stat 1;
BA_ "U_CD42_MY14_Gas_Rx" SG_ 963 HeadLampLoFlOn_B_Stat 1;
BA_ "U_P552_MY15_Gas_Rx" SG_ 963 HeadLampLoFlOn_B_Stat 1;
BA_ "U_S550_MY15_Gas_Rx" SG_ 963 HeadLampLoFlOn_B_Stat 1;
BA_ "U_C489_MY14_Gas_Rx" SG_ 963 HeadLampLoFlOn_B_Stat 1;
BA_ "U_U502_MY15_Gas_Rx" SG_ 963 HeadLampLoFlOn_B_Stat 1;
BA_ "U_UP375_MY15_Gas_Rx" SG_ 963 HeadLampLoFlOn_B_Stat 1;
BA_ "U_UP375_MY15_Diesel_Rx" SG_ 963 HeadLampLoFlOn_B_Stat 1;
BA_ "U_CD43_MY16_Gas_Rx" SG_ 963 HeadLampLoFlOn_B_Stat 1;
BA_ "CrossOver_InfoCAN" SG_ 963 HeadLampLoActv_B_Stat 1;
BA_ "GenSigStartValue" SG_ 963 HeadLampLoActv_B_Stat 1;
BA_ "U_CD4_MY13_Diesel_Rx" SG_ 963 HeadLampLoActv_B_Stat 1;
BA_ "U_CD4_MY13_Gas_Rx" SG_ 963 HeadLampLoActv_B_Stat 1;
BA_ "U_CD4_MY13_Hev_Rx" SG_ 963 HeadLampLoActv_B_Stat 1;
BA_ "U_CD4_MY13_Phev_Rx" SG_ 963 HeadLampLoActv_B_Stat 1;
BA_ "U_CD42_MY14_Diesel_Rx" SG_ 963 HeadLampLoActv_B_Stat 1;
BA_ "U_CD42_MY14_Gas_Rx" SG_ 963 HeadLampLoActv_B_Stat 1;
BA_ "U_P552_MY15_Gas_Rx" SG_ 963 HeadLampLoActv_B_Stat 1;
BA_ "U_C489_MY14_Gas_Rx" SG_ 963 HeadLampLoActv_B_Stat 1;
BA_ "U_U502_MY15_Gas_Rx" SG_ 963 HeadLampLoActv_B_Stat 1;
BA_ "U_UP375_MY15_Gas_Rx" SG_ 963 HeadLampLoActv_B_Stat 1;
BA_ "U_UP375_MY15_Diesel_Rx" SG_ 963 HeadLampLoActv_B_Stat 1;
BA_ "U_CD43_MY16_Gas_Rx" SG_ 963 HeadLampLoActv_B_Stat 1;
BA_ "U_CD4_MY14_Diesel_Rx" SG_ 963 HeadLampLoActv_B_Stat 1;
BA_ "U_CD4_MY14_Gas_Rx" SG_ 963 HeadLampLoActv_B_Stat 1;
BA_ "U_CD4_MY14_Hev_Rx" SG_ 963 HeadLampLoActv_B_Stat 1;
BA_ "U_CD4_MY14_Phev_Rx" SG_ 963 HeadLampLoActv_B_Stat 1;
BA_ "WakeupSignal" SG_ 963 Headlamp_On_Wrning_Cmd 1;
BA_ "CrossOver_InfoCAN" SG_ 963 Headlamp_On_Wrning_Cmd 1;
BA_ "WakeupSignal" SG_ 963 HeadLghtHiOn_B_Stat 1;
BA_ "CrossOver_InfoCAN" SG_ 963 HeadLghtHiOn_B_Stat 1;
BA_ "U_CD4_MY13_Diesel_Rx" SG_ 963 HeadLghtHiOn_B_Stat 1;
BA_ "U_CD4_MY13_Gas_Rx" SG_ 963 HeadLghtHiOn_B_Stat 1;
BA_ "U_CD4_MY13_Hev_Rx" SG_ 963 HeadLghtHiOn_B_Stat 1;
BA_ "U_CD4_MY13_Phev_Rx" SG_ 963 HeadLghtHiOn_B_Stat 1;
BA_ "U_CD42_MY14_Diesel_Rx" SG_ 963 HeadLghtHiOn_B_Stat 1;
BA_ "U_CD42_MY14_Gas_Rx" SG_ 963 HeadLghtHiOn_B_Stat 1;
BA_ "U_P552_MY15_Gas_Rx" SG_ 963 HeadLghtHiOn_B_Stat 1;
BA_ "U_C489_MY14_Gas_Rx" SG_ 963 HeadLghtHiOn_B_Stat 1;
BA_ "U_U502_MY15_Gas_Rx" SG_ 963 HeadLghtHiOn_B_Stat 1;
BA_ "U_UP375_MY15_Gas_Rx" SG_ 963 HeadLghtHiOn_B_Stat 1;
BA_ "U_UP375_MY15_Diesel_Rx" SG_ 963 HeadLghtHiOn_B_Stat 1;
BA_ "U_CD43_MY16_Gas_Rx" SG_ 963 HeadLghtHiOn_B_Stat 1;
BA_ "U_CD4_MY14_Diesel_Rx" SG_ 963 HeadLghtHiOn_B_Stat 1;
BA_ "U_CD4_MY14_Gas_Rx" SG_ 963 HeadLghtHiOn_B_Stat 1;
BA_ "U_CD4_MY14_Hev_Rx" SG_ 963 HeadLghtHiOn_B_Stat 1;
BA_ "U_CD4_MY14_Phev_Rx" SG_ 963 HeadLghtHiOn_B_Stat 1;
BA_ "CrossOver_InfoCAN" SG_ 963 Park_Brake_Chime_Rqst 1;
BA_ "WakeupSignal" SG_ 963 BrkWarnInd_B_Rq 1;
BA_ "CrossOver_InfoCAN" SG_ 963 BrkWarnInd_B_Rq 1;
BA_ "CrossOver_InfoCAN" SG_ 963 Brk_Fluid_Lvl_Low 1;
BA_ "CrossOver_InfoCAN" SG_ 963 ReducedGuard_D_Stat 1;
BA_ "WakeupSignal" SG_ 963 Perimeter_Alarm_Status 1;
BA_ "CrossOver_InfoCAN" SG_ 963 Perimeter_Alarm_Status 1;
BA_ "WakeupSignal" SG_ 963 Courtesy_BSave_Stat 1;
BA_ "CrossOver_InfoCAN" SG_ 963 Courtesy_BSave_Stat 1;
BA_ "GenSigStartValue" SG_ 963 Courtesy_BSave_Stat 1;
BA_ "CrossOver_InfoCAN" SG_ 963 DayRnngLampOn_B_Stat 1;
BA_ "WakeupSignal" SG_ 963 WndwGlbl_D_Cmd 1;
BA_ "CrossOver_InfoCAN" SG_ 963 WndwGlbl_D_Cmd 1;
BA_ "WakeupSignal" SG_ 963 PudLamp_D_Rq 1;
BA_ "CrossOver_InfoCAN" SG_ 963 PudLamp_D_Rq 1;
BA_ "WakeupSignal" SG_ 963 PerimeterAlarmChimeRq 1;
BA_ "CrossOver_InfoCAN" SG_ 963 PerimeterAlarmChimeRq 1;
BA_ "U_P552_MY17_Diesel_Rx" SG_ 972 LsmcBrkDecel_A_Rq 1;
BA_ "U_P552_MY17_Gas_Rx" SG_ 972 LsmcBrkDecel_A_Rq 1;
BA_ "U_P552_MY17_Diesel_Rx" SG_ 972 LsmcBrkDecelEnbl_D_Rq 1;
BA_ "U_P552_MY17_Gas_Rx" SG_ 972 LsmcBrkDecelEnbl_D_Rq 1;
BA_ "CrossOver_InfoCAN" SG_ 972 LaHandsOff_B_Actl 1;
BA_ "GenSigStartValue" SG_ 972 LaHandsOff_B_Actl 1;
BA_ "U_CD4_MY13_Diesel_Rx" SG_ 972 LaHandsOff_B_Actl 1;
BA_ "U_CD4_MY13_Gas_Rx" SG_ 972 LaHandsOff_B_Actl 1;
BA_ "U_CD4_MY13_Hev_Rx" SG_ 972 LaHandsOff_B_Actl 1;
BA_ "U_CD4_MY13_Phev_Rx" SG_ 972 LaHandsOff_B_Actl 1;
BA_ "U_CD42_MY14_Diesel_Rx" SG_ 972 LaHandsOff_B_Actl 1;
BA_ "U_CD42_MY14_Gas_Rx" SG_ 972 LaHandsOff_B_Actl 1;
BA_ "U_P552_MY15_Gas_Rx" SG_ 972 LaHandsOff_B_Actl 1;
BA_ "U_C489_MY14_Gas_Rx" SG_ 972 LaHandsOff_B_Actl 1;
BA_ "U_U502_MY15_Gas_Rx" SG_ 972 LaHandsOff_B_Actl 1;
BA_ "U_UP375_MY15_Gas_Rx" SG_ 972 LaHandsOff_B_Actl 1;
BA_ "U_UP375_MY15_Diesel_Rx" SG_ 972 LaHandsOff_B_Actl 1;
BA_ "U_CD43_MY16_Gas_Rx" SG_ 972 LaHandsOff_B_Actl 1;
BA_ "U_CD4_MY14_Diesel_Rx" SG_ 972 LaHandsOff_B_Actl 1;
BA_ "U_CD4_MY14_Gas_Rx" SG_ 972 LaHandsOff_B_Actl 1;
BA_ "U_CD4_MY14_Hev_Rx" SG_ 972 LaHandsOff_B_Actl 1;
BA_ "U_CD4_MY14_Phev_Rx" SG_ 972 LaHandsOff_B_Actl 1;
BA_ "U_CD4_MY13_Diesel_Tx" SG_ 972 LaHandsOff_B_Actl 1;
BA_ "U_CD4_MY13_Gas_Tx" SG_ 972 LaHandsOff_B_Actl 1;
BA_ "U_CD4_MY13_Hev_Tx" SG_ 972 LaHandsOff_B_Actl 1;
BA_ "U_CD4_MY13_Phev_Tx" SG_ 972 LaHandsOff_B_Actl 1;
BA_ "U_CD42_MY14_Diesel_Tx" SG_ 972 LaHandsOff_B_Actl 1;
BA_ "U_CD42_MY14_Gas_Tx" SG_ 972 LaHandsOff_B_Actl 1;
BA_ "U_P552_MY15_Gas_Tx" SG_ 972 LaHandsOff_B_Actl 1;
BA_ "U_C489_MY14_Gas_Tx" SG_ 972 LaHandsOff_B_Actl 1;
BA_ "U_U502_MY15_Gas_Tx" SG_ 972 LaHandsOff_B_Actl 1;
BA_ "U_UP375_MY15_Gas_Tx" SG_ 972 LaHandsOff_B_Actl 1;
BA_ "U_UP375_MY15_Diesel_Tx" SG_ 972 LaHandsOff_B_Actl 1;
BA_ "U_CD43_MY16_Gas_Tx" SG_ 972 LaHandsOff_B_Actl 1;
BA_ "CrossOver_InfoCAN" SG_ 972 LaActDeny_B_Actl 1;
BA_ "U_U502_MY15_Gas_Rx" SG_ 972 LaActDeny_B_Actl 1;
BA_ "U_UP375_MY15_Gas_Rx" SG_ 972 LaActDeny_B_Actl 1;
BA_ "U_UP375_MY15_Diesel_Rx" SG_ 972 LaActDeny_B_Actl 1;
BA_ "U_CD43_MY16_Gas_Rx" SG_ 972 LaActDeny_B_Actl 1;
BA_ "U_CD4_MY14_Diesel_Rx" SG_ 972 LaActDeny_B_Actl 1;
BA_ "U_CD4_MY14_Gas_Rx" SG_ 972 LaActDeny_B_Actl 1;
BA_ "U_CD4_MY14_Hev_Rx" SG_ 972 LaActDeny_B_Actl 1;
BA_ "U_CD4_MY14_Phev_Rx" SG_ 972 LaActDeny_B_Actl 1;
BA_ "U_CD4_MY13_Diesel_Tx" SG_ 972 LaActDeny_B_Actl 1;
BA_ "U_CD4_MY13_Gas_Tx" SG_ 972 LaActDeny_B_Actl 1;
BA_ "U_CD4_MY13_Hev_Tx" SG_ 972 LaActDeny_B_Actl 1;
BA_ "U_CD4_MY13_Phev_Tx" SG_ 972 LaActDeny_B_Actl 1;
BA_ "U_CD42_MY14_Diesel_Tx" SG_ 972 LaActDeny_B_Actl 1;
BA_ "U_CD42_MY14_Gas_Tx" SG_ 972 LaActDeny_B_Actl 1;
BA_ "U_P552_MY15_Gas_Tx" SG_ 972 LaActDeny_B_Actl 1;
BA_ "U_C489_MY14_Gas_Tx" SG_ 972 LaActDeny_B_Actl 1;
BA_ "U_U502_MY15_Gas_Tx" SG_ 972 LaActDeny_B_Actl 1;
BA_ "U_UP375_MY15_Gas_Tx" SG_ 972 LaActDeny_B_Actl 1;
BA_ "U_UP375_MY15_Diesel_Tx" SG_ 972 LaActDeny_B_Actl 1;
BA_ "U_CD43_MY16_Gas_Tx" SG_ 972 LaActDeny_B_Actl 1;
BA_ "CrossOver_InfoCAN" SG_ 972 LaActAvail_D_Actl 1;
BA_ "U_U502_MY15_Gas_Rx" SG_ 972 LaActAvail_D_Actl 1;
BA_ "U_UP375_MY15_Gas_Rx" SG_ 972 LaActAvail_D_Actl 1;
BA_ "U_UP375_MY15_Diesel_Rx" SG_ 972 LaActAvail_D_Actl 1;
BA_ "U_CD43_MY16_Gas_Rx" SG_ 972 LaActAvail_D_Actl 1;
BA_ "U_CD4_MY14_Diesel_Rx" SG_ 972 LaActAvail_D_Actl 1;
BA_ "U_CD4_MY14_Gas_Rx" SG_ 972 LaActAvail_D_Actl 1;
BA_ "U_CD4_MY14_Hev_Rx" SG_ 972 LaActAvail_D_Actl 1;
BA_ "U_CD4_MY14_Phev_Rx" SG_ 972 LaActAvail_D_Actl 1;
BA_ "U_CD4_MY13_Diesel_Tx" SG_ 972 LaActAvail_D_Actl 1;
BA_ "U_CD4_MY13_Gas_Tx" SG_ 972 LaActAvail_D_Actl 1;
BA_ "U_CD4_MY13_Hev_Tx" SG_ 972 LaActAvail_D_Actl 1;
BA_ "U_CD4_MY13_Phev_Tx" SG_ 972 LaActAvail_D_Actl 1;
BA_ "U_CD42_MY14_Diesel_Tx" SG_ 972 LaActAvail_D_Actl 1;
BA_ "U_CD42_MY14_Gas_Tx" SG_ 972 LaActAvail_D_Actl 1;
BA_ "U_P552_MY15_Gas_Tx" SG_ 972 LaActAvail_D_Actl 1;
BA_ "U_C489_MY14_Gas_Tx" SG_ 972 LaActAvail_D_Actl 1;
BA_ "U_U502_MY15_Gas_Tx" SG_ 972 LaActAvail_D_Actl 1;
BA_ "U_UP375_MY15_Gas_Tx" SG_ 972 LaActAvail_D_Actl 1;
BA_ "U_UP375_MY15_Diesel_Tx" SG_ 972 LaActAvail_D_Actl 1;
BA_ "U_CD43_MY16_Gas_Tx" SG_ 972 LaActAvail_D_Actl 1;
BA_ "GenSigTimeoutTime_GWM" SG_ 133 SteWhlRelCalib_An_Sns 30;
BA_ "U_V36X_MY18_5_Hev_Tx" SG_ 133 SteWhlRelCalib_An_Sns 1;
BA_ "U_V36X_MY18_5_Gas_Tx" SG_ 133 SteWhlRelCalib_An_Sns 1;
BA_ "U_CD42_MY19_Gas_Tx" SG_ 133 SteWhlRelCalib_An_Sns 1;
BA_ "U_CD42_MY19_Diesel_Tx" SG_ 133 SteWhlRelCalib_An_Sns 1;
BA_ "U_V363E_N_MY19_5_20_Diesel_Tx" SG_ 133 SteWhlRelCalib_An_Sns 1;
BA_ "U_V363E_N_MY19_5_20_Gas_Tx" SG_ 133 SteWhlRelCalib_An_Sns 1;
BA_ "U_V36X_MY19_5_Diesel_Tx" SG_ 133 SteWhlRelCalib_An_Sns 1;
BA_ "U_V36X_MY18_5_Diesel_Tx" SG_ 133 SteWhlRelCalib_An_Sns 1;
BA_ "U_V408_MY18_Diesel_Tx" SG_ 133 SteWhlRelCalib_An_Sns 1;
BA_ "U_V408_MY18_Gas_Tx" SG_ 133 SteWhlRelCalib_An_Sns 1;
BA_ "U_U55x_MY18_Gas_Tx" SG_ 133 SteWhlRelCalib_An_Sns 1;
BA_ "U_CD42_MY16_Gas_Tx" SG_ 133 SteWhlRelCalib_An_Sns 1;
BA_ "U_CD42_MY16_Diesel_Tx" SG_ 133 SteWhlRelCalib_An_Sns 1;
BA_ "U_V36X_MY16_5_Diesel_Tx" SG_ 133 SteWhlRelCalib_An_Sns 1;
BA_ "U_P558_MY17_Diesel_Tx" SG_ 133 SteWhlRelCalib_An_Sns 1;
BA_ "U_P558_MY17_Gas_Tx" SG_ 133 SteWhlRelCalib_An_Sns 1;
BA_ "U_CD43_MY16_Gas_Tx" SG_ 133 SteWhlRelCalib_An_Sns 1;
BA_ "U_UP375_MY18_Diesel_Tx" SG_ 133 SteWhlRelCalib_An_Sns 1;
BA_ "U_UP375_MY18_Gas_Tx" SG_ 133 SteWhlRelCalib_An_Sns 1;
BA_ "U_U502_MY16_Gas_Tx" SG_ 133 SteWhlRelCalib_An_Sns 1;
BA_ "U_S550_MY15_Gas_Tx" SG_ 133 SteWhlRelCalib_An_Sns 1;
BA_ "U_P552_MY15_Gas_Tx" SG_ 133 SteWhlRelCalib_An_Sns 1;
BA_ "U_CD42_MY15_Gas_Tx" SG_ 133 SteWhlRelCalib_An_Sns 1;
BA_ "U_CD42_MY15_Diesel_Tx" SG_ 133 SteWhlRelCalib_An_Sns 1;
BA_ "U_V36X_MY18_5_Hev_Rx" SG_ 133 SteWhlRelCalib_An_Sns 1;
BA_ "U_V36X_MY18_5_Gas_Rx" SG_ 133 SteWhlRelCalib_An_Sns 1;
BA_ "U_CD42_MY19_Gas_Rx" SG_ 133 SteWhlRelCalib_An_Sns 1;
BA_ "U_CD42_MY19_Diesel_Rx" SG_ 133 SteWhlRelCalib_An_Sns 1;
BA_ "U_V363E_N_MY19_5_20_Gas_Rx" SG_ 133 SteWhlRelCalib_An_Sns 1;
BA_ "U_V36X_MY19_5_Diesel_Rx" SG_ 133 SteWhlRelCalib_An_Sns 1;
BA_ "U_V36X_MY18_5_Diesel_Rx" SG_ 133 SteWhlRelCalib_An_Sns 1;
BA_ "U_V408_MY18_Diesel_Rx" SG_ 133 SteWhlRelCalib_An_Sns 1;
BA_ "U_V408_MY18_Gas_Rx" SG_ 133 SteWhlRelCalib_An_Sns 1;
BA_ "U_CD43_MY17_Gas_Rx" SG_ 133 SteWhlRelCalib_An_Sns 1;
BA_ "U_CD42_MY16_Gas_Rx" SG_ 133 SteWhlRelCalib_An_Sns 1;
BA_ "U_CD42_MY16_Diesel_Rx" SG_ 133 SteWhlRelCalib_An_Sns 1;
BA_ "U_V36X_MY16_5_Diesel_Rx" SG_ 133 SteWhlRelCalib_An_Sns 1;
BA_ "U_P558_MY17_Diesel_Rx" SG_ 133 SteWhlRelCalib_An_Sns 1;
BA_ "U_P558_MY17_Gas_Rx" SG_ 133 SteWhlRelCalib_An_Sns 1;
BA_ "U_CD43_MY16_Gas_Rx" SG_ 133 SteWhlRelCalib_An_Sns 1;
BA_ "U_S550_MY15_Gas_Rx" SG_ 133 SteWhlRelCalib_An_Sns 1;
BA_ "U_CD42_MY15_Gas_Rx" SG_ 133 SteWhlRelCalib_An_Sns 1;
BA_ "U_CD42_MY15_Diesel_Rx" SG_ 133 SteWhlRelCalib_An_Sns 1;
BA_ "ContentDependant" SG_ 133 SteWhlRelCalib_An_Sns 1;
BA_ "ContentDependant" SG_ 133 SteWhlAn_No_Cs 1;
BA_ "U_CD4_MY13_Diesel_Rx" SG_ 133 SteWhlAn_No_Cs 1;
BA_ "U_CD4_MY13_Gas_Rx" SG_ 133 SteWhlAn_No_Cs 1;
BA_ "U_CD4_MY13_Hev_Rx" SG_ 133 SteWhlAn_No_Cs 1;
BA_ "U_CD4_MY13_Phev_Rx" SG_ 133 SteWhlAn_No_Cs 1;
BA_ "U_CD42_MY14_Diesel_Rx" SG_ 133 SteWhlAn_No_Cs 1;
BA_ "U_CD42_MY14_Gas_Rx" SG_ 133 SteWhlAn_No_Cs 1;
BA_ "U_P552_MY15_Gas_Rx" SG_ 133 SteWhlAn_No_Cs 1;
BA_ "U_S550_MY15_Gas_Rx" SG_ 133 SteWhlAn_No_Cs 1;
BA_ "U_C489_MY14_Gas_Rx" SG_ 133 SteWhlAn_No_Cs 1;
BA_ "U_U502_MY15_Gas_Rx" SG_ 133 SteWhlAn_No_Cs 1;
BA_ "U_UP375_MY15_Gas_Rx" SG_ 133 SteWhlAn_No_Cs 1;
BA_ "U_UP375_MY15_Diesel_Rx" SG_ 133 SteWhlAn_No_Cs 1;
BA_ "U_CD43_MY16_Gas_Rx" SG_ 133 SteWhlAn_No_Cs 1;
BA_ "U_CD4_MY13_Diesel_Tx" SG_ 133 SteWhlAn_No_Cs 1;
BA_ "U_CD4_MY13_Gas_Tx" SG_ 133 SteWhlAn_No_Cs 1;
BA_ "U_CD4_MY13_Hev_Tx" SG_ 133 SteWhlAn_No_Cs 1;
BA_ "U_CD4_MY13_Phev_Tx" SG_ 133 SteWhlAn_No_Cs 1;
BA_ "U_C489_MY14_Gas_Tx" SG_ 133 SteWhlAn_No_Cs 1;
BA_ "U_UP375_MY15_Gas_Tx" SG_ 133 SteWhlAn_No_Cs 1;
BA_ "U_UP375_MY15_Diesel_Tx" SG_ 133 SteWhlAn_No_Cs 1;
BA_ "U_CD42_MY14_Diesel_Tx" SG_ 133 SteWhlAn_No_Cs 1;
BA_ "U_CD42_MY14_Gas_Tx" SG_ 133 SteWhlAn_No_Cs 1;
BA_ "U_P552_MY15_Gas_Tx" SG_ 133 SteWhlAn_No_Cs 1;
BA_ "U_S550_MY15_Gas_Tx" SG_ 133 SteWhlAn_No_Cs 1;
BA_ "U_U502_MY15_Gas_Tx" SG_ 133 SteWhlAn_No_Cs 1;
BA_ "U_CD43_MY16_Gas_Tx" SG_ 133 SteWhlAn_No_Cs 1;
BA_ "ContentDependant" SG_ 133 SteWhlAn_No_Cnt 1;
BA_ "U_CD4_MY13_Diesel_Rx" SG_ 133 SteWhlAn_No_Cnt 1;
BA_ "U_CD4_MY13_Gas_Rx" SG_ 133 SteWhlAn_No_Cnt 1;
BA_ "U_CD4_MY13_Hev_Rx" SG_ 133 SteWhlAn_No_Cnt 1;
BA_ "U_CD4_MY13_Phev_Rx" SG_ 133 SteWhlAn_No_Cnt 1;
BA_ "U_CD42_MY14_Diesel_Rx" SG_ 133 SteWhlAn_No_Cnt 1;
BA_ "U_CD42_MY14_Gas_Rx" SG_ 133 SteWhlAn_No_Cnt 1;
BA_ "U_P552_MY15_Gas_Rx" SG_ 133 SteWhlAn_No_Cnt 1;
BA_ "U_S550_MY15_Gas_Rx" SG_ 133 SteWhlAn_No_Cnt 1;
BA_ "U_C489_MY14_Gas_Rx" SG_ 133 SteWhlAn_No_Cnt 1;
BA_ "U_U502_MY15_Gas_Rx" SG_ 133 SteWhlAn_No_Cnt 1;
BA_ "U_UP375_MY15_Gas_Rx" SG_ 133 SteWhlAn_No_Cnt 1;
BA_ "U_UP375_MY15_Diesel_Rx" SG_ 133 SteWhlAn_No_Cnt 1;
BA_ "U_CD43_MY16_Gas_Rx" SG_ 133 SteWhlAn_No_Cnt 1;
BA_ "U_CD4_MY13_Diesel_Tx" SG_ 133 SteWhlAn_No_Cnt 1;
BA_ "U_CD4_MY13_Gas_Tx" SG_ 133 SteWhlAn_No_Cnt 1;
BA_ "U_CD4_MY13_Hev_Tx" SG_ 133 SteWhlAn_No_Cnt 1;
BA_ "U_CD4_MY13_Phev_Tx" SG_ 133 SteWhlAn_No_Cnt 1;
BA_ "U_C489_MY14_Gas_Tx" SG_ 133 SteWhlAn_No_Cnt 1;
BA_ "U_UP375_MY15_Gas_Tx" SG_ 133 SteWhlAn_No_Cnt 1;
BA_ "U_UP375_MY15_Diesel_Tx" SG_ 133 SteWhlAn_No_Cnt 1;
BA_ "U_CD42_MY14_Diesel_Tx" SG_ 133 SteWhlAn_No_Cnt 1;
BA_ "U_CD42_MY14_Gas_Tx" SG_ 133 SteWhlAn_No_Cnt 1;
BA_ "U_P552_MY15_Gas_Tx" SG_ 133 SteWhlAn_No_Cnt 1;
BA_ "U_S550_MY15_Gas_Tx" SG_ 133 SteWhlAn_No_Cnt 1;
BA_ "U_U502_MY15_Gas_Tx" SG_ 133 SteWhlAn_No_Cnt 1;
BA_ "U_CD43_MY16_Gas_Tx" SG_ 133 SteWhlAn_No_Cnt 1;
BA_ "CrossOver_LIN" SG_ 133 SteWhlRelInit2_An_Sns 1;
BA_ "GenSigStartValue" SG_ 133 SteWhlRelInit2_An_Sns 65535;
BA_ "U_CD4_MY13_Diesel_Rx" SG_ 133 SteWhlRelInit2_An_Sns 1;
BA_ "U_CD4_MY13_Gas_Rx" SG_ 133 SteWhlRelInit2_An_Sns 1;
BA_ "U_CD4_MY13_Hev_Rx" SG_ 133 SteWhlRelInit2_An_Sns 1;
BA_ "U_CD4_MY13_Phev_Rx" SG_ 133 SteWhlRelInit2_An_Sns 1;
BA_ "U_CD42_MY14_Diesel_Rx" SG_ 133 SteWhlRelInit2_An_Sns 1;
BA_ "U_CD42_MY14_Gas_Rx" SG_ 133 SteWhlRelInit2_An_Sns 1;
BA_ "U_P552_MY15_Gas_Rx" SG_ 133 SteWhlRelInit2_An_Sns 1;
BA_ "U_S550_MY15_Gas_Rx" SG_ 133 SteWhlRelInit2_An_Sns 1;
BA_ "U_C489_MY14_Gas_Rx" SG_ 133 SteWhlRelInit2_An_Sns 1;
BA_ "U_U502_MY15_Gas_Rx" SG_ 133 SteWhlRelInit2_An_Sns 1;
BA_ "U_UP375_MY15_Gas_Rx" SG_ 133 SteWhlRelInit2_An_Sns 1;
BA_ "U_UP375_MY15_Diesel_Rx" SG_ 133 SteWhlRelInit2_An_Sns 1;
BA_ "U_CD43_MY16_Gas_Rx" SG_ 133 SteWhlRelInit2_An_Sns 1;
BA_ "U_CD4_MY13_Diesel_Tx" SG_ 133 SteWhlRelInit2_An_Sns 1;
BA_ "U_CD4_MY13_Gas_Tx" SG_ 133 SteWhlRelInit2_An_Sns 1;
BA_ "U_CD4_MY13_Hev_Tx" SG_ 133 SteWhlRelInit2_An_Sns 1;
BA_ "U_CD4_MY13_Phev_Tx" SG_ 133 SteWhlRelInit2_An_Sns 1;
BA_ "U_C489_MY14_Gas_Tx" SG_ 133 SteWhlRelInit2_An_Sns 1;
BA_ "U_UP375_MY15_Gas_Tx" SG_ 133 SteWhlRelInit2_An_Sns 1;
BA_ "U_UP375_MY15_Diesel_Tx" SG_ 133 SteWhlRelInit2_An_Sns 1;
BA_ "U_CD42_MY14_Diesel_Tx" SG_ 133 SteWhlRelInit2_An_Sns 1;
BA_ "U_CD42_MY14_Gas_Tx" SG_ 133 SteWhlRelInit2_An_Sns 1;
BA_ "U_P552_MY15_Gas_Tx" SG_ 133 SteWhlRelInit2_An_Sns 1;
BA_ "U_S550_MY15_Gas_Tx" SG_ 133 SteWhlRelInit2_An_Sns 1;
BA_ "U_U502_MY15_Gas_Tx" SG_ 133 SteWhlRelInit2_An_Sns 1;
BA_ "U_CD43_MY16_Gas_Tx" SG_ 133 SteWhlRelInit2_An_Sns 1;
BA_ "U_CD42_MY14_Diesel_Tx" SG_ 133 StePw_B_Rq 1;
BA_ "U_CD42_MY14_Gas_Tx" SG_ 133 StePw_B_Rq 1;
BA_ "U_P552_MY15_Gas_Tx" SG_ 133 StePw_B_Rq 1;
BA_ "U_C489_MY14_Gas_Tx" SG_ 133 StePw_B_Rq 1;
BA_ "U_U502_MY15_Gas_Tx" SG_ 133 StePw_B_Rq 1;
BA_ "U_UP375_MY15_Gas_Tx" SG_ 133 StePw_B_Rq 1;
BA_ "U_UP375_MY15_Diesel_Tx" SG_ 133 StePw_B_Rq 1;
BA_ "U_CD43_MY16_Gas_Tx" SG_ 133 StePw_B_Rq 1;
BA_ "CrossOver_LIN" SG_ 133 SteWhlOSRelInit2An_Est 1;
BA_ "GenSigStartValue" SG_ 133 SteWhlOSRelInit2An_Est 65534;
BA_ "U_CD4_MY13_Diesel_Rx" SG_ 133 SteWhlOSRelInit2An_Est 1;
BA_ "U_CD4_MY13_Gas_Rx" SG_ 133 SteWhlOSRelInit2An_Est 1;
BA_ "U_CD4_MY13_Hev_Rx" SG_ 133 SteWhlOSRelInit2An_Est 1;
BA_ "U_CD4_MY13_Phev_Rx" SG_ 133 SteWhlOSRelInit2An_Est 1;
BA_ "U_CD42_MY14_Diesel_Rx" SG_ 133 SteWhlOSRelInit2An_Est 1;
BA_ "U_CD42_MY14_Gas_Rx" SG_ 133 SteWhlOSRelInit2An_Est 1;
BA_ "U_P552_MY15_Gas_Rx" SG_ 133 SteWhlOSRelInit2An_Est 1;
BA_ "U_S550_MY15_Gas_Rx" SG_ 133 SteWhlOSRelInit2An_Est 1;
BA_ "U_C489_MY14_Gas_Rx" SG_ 133 SteWhlOSRelInit2An_Est 1;
BA_ "U_U502_MY15_Gas_Rx" SG_ 133 SteWhlOSRelInit2An_Est 1;
BA_ "U_CD43_MY16_Gas_Rx" SG_ 133 SteWhlOSRelInit2An_Est 1;
BA_ "U_CD42_MY14_Diesel_Tx" SG_ 133 SteWhlOSRelInit2An_Est 1;
BA_ "U_CD42_MY14_Gas_Tx" SG_ 133 SteWhlOSRelInit2An_Est 1;
BA_ "U_P552_MY15_Gas_Tx" SG_ 133 SteWhlOSRelInit2An_Est 1;
BA_ "U_S550_MY15_Gas_Tx" SG_ 133 SteWhlOSRelInit2An_Est 1;
BA_ "U_C489_MY14_Gas_Tx" SG_ 133 SteWhlOSRelInit2An_Est 1;
BA_ "U_U502_MY15_Gas_Tx" SG_ 133 SteWhlOSRelInit2An_Est 1;
BA_ "U_UP375_MY15_Gas_Tx" SG_ 133 SteWhlOSRelInit2An_Est 1;
BA_ "U_UP375_MY15_Diesel_Tx" SG_ 133 SteWhlOSRelInit2An_Est 1;
BA_ "U_CD43_MY16_Gas_Tx" SG_ 133 SteWhlOSRelInit2An_Est 1;
BA_ "GenSigSendType" SG_ 1459 SCCM_AutoSar_Network_Mgmt 3;
BA_ "U_CD4_MY13_Diesel_Rx" SG_ 1459 SCCM_AutoSar_Network_Mgmt 1;
BA_ "U_CD4_MY13_Gas_Rx" SG_ 1459 SCCM_AutoSar_Network_Mgmt 1;
BA_ "U_CD4_MY13_Hev_Rx" SG_ 1459 SCCM_AutoSar_Network_Mgmt 1;
BA_ "U_CD4_MY13_Phev_Rx" SG_ 1459 SCCM_AutoSar_Network_Mgmt 1;
BA_ "U_CD42_MY14_Diesel_Rx" SG_ 1459 SCCM_AutoSar_Network_Mgmt 1;
BA_ "U_CD42_MY14_Gas_Rx" SG_ 1459 SCCM_AutoSar_Network_Mgmt 1;
BA_ "U_P552_MY15_Gas_Rx" SG_ 1459 SCCM_AutoSar_Network_Mgmt 1;
BA_ "U_S550_MY15_Gas_Rx" SG_ 1459 SCCM_AutoSar_Network_Mgmt 1;
BA_ "U_C489_MY14_Gas_Rx" SG_ 1459 SCCM_AutoSar_Network_Mgmt 1;
BA_ "U_U502_MY15_Gas_Rx" SG_ 1459 SCCM_AutoSar_Network_Mgmt 1;
BA_ "U_UP375_MY15_Gas_Rx" SG_ 1459 SCCM_AutoSar_Network_Mgmt 1;
BA_ "U_UP375_MY15_Diesel_Rx" SG_ 1459 SCCM_AutoSar_Network_Mgmt 1;
BA_ "U_CD43_MY16_Gas_Rx" SG_ 1459 SCCM_AutoSar_Network_Mgmt 1;
BA_ "U_CD4_MY13_Diesel_Tx" SG_ 1459 SCCM_AutoSar_Network_Mgmt 1;
BA_ "U_CD4_MY13_Gas_Tx" SG_ 1459 SCCM_AutoSar_Network_Mgmt 1;
BA_ "U_CD4_MY13_Hev_Tx" SG_ 1459 SCCM_AutoSar_Network_Mgmt 1;
BA_ "U_CD4_MY13_Phev_Tx" SG_ 1459 SCCM_AutoSar_Network_Mgmt 1;
BA_ "U_CD42_MY14_Diesel_Tx" SG_ 1459 SCCM_AutoSar_Network_Mgmt 1;
BA_ "U_CD42_MY14_Gas_Tx" SG_ 1459 SCCM_AutoSar_Network_Mgmt 1;
BA_ "U_P552_MY15_Gas_Tx" SG_ 1459 SCCM_AutoSar_Network_Mgmt 1;
BA_ "U_S550_MY15_Gas_Tx" SG_ 1459 SCCM_AutoSar_Network_Mgmt 1;
BA_ "U_C489_MY14_Gas_Tx" SG_ 1459 SCCM_AutoSar_Network_Mgmt 1;
BA_ "U_U502_MY15_Gas_Tx" SG_ 1459 SCCM_AutoSar_Network_Mgmt 1;
BA_ "U_UP375_MY15_Gas_Tx" SG_ 1459 SCCM_AutoSar_Network_Mgmt 1;
BA_ "U_UP375_MY15_Diesel_Tx" SG_ 1459 SCCM_AutoSar_Network_Mgmt 1;
BA_ "U_CD43_MY16_Gas_Tx" SG_ 1459 SCCM_AutoSar_Network_Mgmt 1;
BA_ "U_CD4_MY13_Diesel_Rx" SG_ 391 CmbbBrkDecel_No_Cnt 1;
BA_ "U_CD4_MY13_Gas_Rx" SG_ 391 CmbbBrkDecel_No_Cnt 1;
BA_ "U_CD4_MY13_Hev_Rx" SG_ 391 CmbbBrkDecel_No_Cnt 1;
BA_ "U_CD4_MY13_Phev_Rx" SG_ 391 CmbbBrkDecel_No_Cnt 1;
BA_ "U_CD42_MY14_Diesel_Rx" SG_ 391 CmbbBrkDecel_No_Cnt 1;
BA_ "U_CD42_MY14_Gas_Rx" SG_ 391 CmbbBrkDecel_No_Cnt 1;
BA_ "U_P552_MY15_Gas_Rx" SG_ 391 CmbbBrkDecel_No_Cnt 1;
BA_ "U_S550_MY15_Gas_Rx" SG_ 391 CmbbBrkDecel_No_Cnt 1;
BA_ "U_C489_MY14_Gas_Rx" SG_ 391 CmbbBrkDecel_No_Cnt 1;
BA_ "U_U502_MY15_Gas_Rx" SG_ 391 CmbbBrkDecel_No_Cnt 1;
BA_ "U_UP375_MY15_Gas_Rx" SG_ 391 CmbbBrkDecel_No_Cnt 1;
BA_ "U_UP375_MY15_Diesel_Rx" SG_ 391 CmbbBrkDecel_No_Cnt 1;
BA_ "U_CD43_MY16_Gas_Rx" SG_ 391 CmbbBrkDecel_No_Cnt 1;
BA_ "U_CD4_MY13_Diesel_Tx" SG_ 391 CmbbBrkDecel_No_Cnt 1;
BA_ "U_CD4_MY13_Gas_Tx" SG_ 391 CmbbBrkDecel_No_Cnt 1;
BA_ "U_CD4_MY13_Hev_Tx" SG_ 391 CmbbBrkDecel_No_Cnt 1;
BA_ "U_CD4_MY13_Phev_Tx" SG_ 391 CmbbBrkDecel_No_Cnt 1;
BA_ "U_CD42_MY14_Diesel_Tx" SG_ 391 CmbbBrkDecel_No_Cnt 1;
BA_ "U_CD42_MY14_Gas_Tx" SG_ 391 CmbbBrkDecel_No_Cnt 1;
BA_ "U_P552_MY15_Gas_Tx" SG_ 391 CmbbBrkDecel_No_Cnt 1;
BA_ "U_S550_MY15_Gas_Tx" SG_ 391 CmbbBrkDecel_No_Cnt 1;
BA_ "U_C489_MY14_Gas_Tx" SG_ 391 CmbbBrkDecel_No_Cnt 1;
BA_ "U_U502_MY15_Gas_Tx" SG_ 391 CmbbBrkDecel_No_Cnt 1;
BA_ "U_UP375_MY15_Gas_Tx" SG_ 391 CmbbBrkDecel_No_Cnt 1;
BA_ "U_UP375_MY15_Diesel_Tx" SG_ 391 CmbbBrkDecel_No_Cnt 1;
BA_ "U_CD43_MY16_Gas_Tx" SG_ 391 CmbbBrkDecel_No_Cnt 1;
BA_ "U_CD4_MY13_Diesel_Rx" SG_ 391 HudDsplyIntns_No_Actl 1;
BA_ "U_CD4_MY13_Gas_Rx" SG_ 391 HudDsplyIntns_No_Actl 1;
BA_ "U_CD4_MY13_Hev_Rx" SG_ 391 HudDsplyIntns_No_Actl 1;
BA_ "U_CD4_MY13_Phev_Rx" SG_ 391 HudDsplyIntns_No_Actl 1;
BA_ "U_CD42_MY14_Diesel_Rx" SG_ 391 HudDsplyIntns_No_Actl 1;
BA_ "U_CD42_MY14_Gas_Rx" SG_ 391 HudDsplyIntns_No_Actl 1;
BA_ "U_P552_MY15_Gas_Rx" SG_ 391 HudDsplyIntns_No_Actl 1;
BA_ "U_S550_MY15_Gas_Rx" SG_ 391 HudDsplyIntns_No_Actl 1;
BA_ "U_C489_MY14_Gas_Rx" SG_ 391 HudDsplyIntns_No_Actl 1;
BA_ "U_U502_MY15_Gas_Rx" SG_ 391 HudDsplyIntns_No_Actl 1;
BA_ "U_UP375_MY15_Gas_Rx" SG_ 391 HudDsplyIntns_No_Actl 1;
BA_ "U_UP375_MY15_Diesel_Rx" SG_ 391 HudDsplyIntns_No_Actl 1;
BA_ "U_CD43_MY16_Gas_Rx" SG_ 391 HudDsplyIntns_No_Actl 1;
BA_ "U_CD4_MY13_Diesel_Tx" SG_ 391 HudDsplyIntns_No_Actl 1;
BA_ "U_CD4_MY13_Gas_Tx" SG_ 391 HudDsplyIntns_No_Actl 1;
BA_ "U_CD4_MY13_Hev_Tx" SG_ 391 HudDsplyIntns_No_Actl 1;
BA_ "U_CD4_MY13_Phev_Tx" SG_ 391 HudDsplyIntns_No_Actl 1;
BA_ "U_CD42_MY14_Diesel_Tx" SG_ 391 HudDsplyIntns_No_Actl 1;
BA_ "U_CD42_MY14_Gas_Tx" SG_ 391 HudDsplyIntns_No_Actl 1;
BA_ "U_P552_MY15_Gas_Tx" SG_ 391 HudDsplyIntns_No_Actl 1;
BA_ "U_S550_MY15_Gas_Tx" SG_ 391 HudDsplyIntns_No_Actl 1;
BA_ "U_C489_MY14_Gas_Tx" SG_ 391 HudDsplyIntns_No_Actl 1;
BA_ "U_U502_MY15_Gas_Tx" SG_ 391 HudDsplyIntns_No_Actl 1;
BA_ "U_UP375_MY15_Gas_Tx" SG_ 391 HudDsplyIntns_No_Actl 1;
BA_ "U_UP375_MY15_Diesel_Tx" SG_ 391 HudDsplyIntns_No_Actl 1;
BA_ "U_CD43_MY16_Gas_Tx" SG_ 391 HudDsplyIntns_No_Actl 1;
BA_ "U_CD4_MY13_Diesel_Rx" SG_ 391 HudBlk3_B_Rq 1;
BA_ "U_CD4_MY13_Gas_Rx" SG_ 391 HudBlk3_B_Rq 1;
BA_ "U_CD4_MY13_Hev_Rx" SG_ 391 HudBlk3_B_Rq 1;
BA_ "U_CD4_MY13_Phev_Rx" SG_ 391 HudBlk3_B_Rq 1;
BA_ "U_CD42_MY14_Diesel_Rx" SG_ 391 HudBlk3_B_Rq 1;
BA_ "U_CD42_MY14_Gas_Rx" SG_ 391 HudBlk3_B_Rq 1;
BA_ "U_P552_MY15_Gas_Rx" SG_ 391 HudBlk3_B_Rq 1;
BA_ "U_S550_MY15_Gas_Rx" SG_ 391 HudBlk3_B_Rq 1;
BA_ "U_C489_MY14_Gas_Rx" SG_ 391 HudBlk3_B_Rq 1;
BA_ "U_U502_MY15_Gas_Rx" SG_ 391 HudBlk3_B_Rq 1;
BA_ "U_UP375_MY15_Gas_Rx" SG_ 391 HudBlk3_B_Rq 1;
BA_ "U_UP375_MY15_Diesel_Rx" SG_ 391 HudBlk3_B_Rq 1;
BA_ "U_CD43_MY16_Gas_Rx" SG_ 391 HudBlk3_B_Rq 1;
BA_ "U_CD4_MY13_Diesel_Tx" SG_ 391 HudBlk3_B_Rq 1;
BA_ "U_CD4_MY13_Gas_Tx" SG_ 391 HudBlk3_B_Rq 1;
BA_ "U_CD4_MY13_Hev_Tx" SG_ 391 HudBlk3_B_Rq 1;
BA_ "U_CD4_MY13_Phev_Tx" SG_ 391 HudBlk3_B_Rq 1;
BA_ "U_CD42_MY14_Diesel_Tx" SG_ 391 HudBlk3_B_Rq 1;
BA_ "U_CD42_MY14_Gas_Tx" SG_ 391 HudBlk3_B_Rq 1;
BA_ "U_P552_MY15_Gas_Tx" SG_ 391 HudBlk3_B_Rq 1;
BA_ "U_S550_MY15_Gas_Tx" SG_ 391 HudBlk3_B_Rq 1;
BA_ "U_C489_MY14_Gas_Tx" SG_ 391 HudBlk3_B_Rq 1;
BA_ "U_U502_MY15_Gas_Tx" SG_ 391 HudBlk3_B_Rq 1;
BA_ "U_UP375_MY15_Gas_Tx" SG_ 391 HudBlk3_B_Rq 1;
BA_ "U_UP375_MY15_Diesel_Tx" SG_ 391 HudBlk3_B_Rq 1;
BA_ "U_CD43_MY16_Gas_Tx" SG_ 391 HudBlk3_B_Rq 1;
BA_ "U_CD4_MY13_Diesel_Rx" SG_ 391 HudBlk2_B_Rq 1;
BA_ "U_CD4_MY13_Gas_Rx" SG_ 391 HudBlk2_B_Rq 1;
BA_ "U_CD4_MY13_Hev_Rx" SG_ 391 HudBlk2_B_Rq 1;
BA_ "U_CD4_MY13_Phev_Rx" SG_ 391 HudBlk2_B_Rq 1;
BA_ "U_CD42_MY14_Diesel_Rx" SG_ 391 HudBlk2_B_Rq 1;
BA_ "U_CD42_MY14_Gas_Rx" SG_ 391 HudBlk2_B_Rq 1;
BA_ "U_P552_MY15_Gas_Rx" SG_ 391 HudBlk2_B_Rq 1;
BA_ "U_S550_MY15_Gas_Rx" SG_ 391 HudBlk2_B_Rq 1;
BA_ "U_C489_MY14_Gas_Rx" SG_ 391 HudBlk2_B_Rq 1;
BA_ "U_U502_MY15_Gas_Rx" SG_ 391 HudBlk2_B_Rq 1;
BA_ "U_UP375_MY15_Gas_Rx" SG_ 391 HudBlk2_B_Rq 1;
BA_ "U_UP375_MY15_Diesel_Rx" SG_ 391 HudBlk2_B_Rq 1;
BA_ "U_CD43_MY16_Gas_Rx" SG_ 391 HudBlk2_B_Rq 1;
BA_ "U_CD4_MY13_Diesel_Tx" SG_ 391 HudBlk2_B_Rq 1;
BA_ "U_CD4_MY13_Gas_Tx" SG_ 391 HudBlk2_B_Rq 1;
BA_ "U_CD4_MY13_Hev_Tx" SG_ 391 HudBlk2_B_Rq 1;
BA_ "U_CD4_MY13_Phev_Tx" SG_ 391 HudBlk2_B_Rq 1;
BA_ "U_CD42_MY14_Diesel_Tx" SG_ 391 HudBlk2_B_Rq 1;
BA_ "U_CD42_MY14_Gas_Tx" SG_ 391 HudBlk2_B_Rq 1;
BA_ "U_P552_MY15_Gas_Tx" SG_ 391 HudBlk2_B_Rq 1;
BA_ "U_S550_MY15_Gas_Tx" SG_ 391 HudBlk2_B_Rq 1;
BA_ "U_C489_MY14_Gas_Tx" SG_ 391 HudBlk2_B_Rq 1;
BA_ "U_U502_MY15_Gas_Tx" SG_ 391 HudBlk2_B_Rq 1;
BA_ "U_UP375_MY15_Gas_Tx" SG_ 391 HudBlk2_B_Rq 1;
BA_ "U_UP375_MY15_Diesel_Tx" SG_ 391 HudBlk2_B_Rq 1;
BA_ "U_CD43_MY16_Gas_Tx" SG_ 391 HudBlk2_B_Rq 1;
BA_ "U_CD4_MY13_Diesel_Rx" SG_ 391 HudBlk1_B_Rq 1;
BA_ "U_CD4_MY13_Gas_Rx" SG_ 391 HudBlk1_B_Rq 1;
BA_ "U_CD4_MY13_Hev_Rx" SG_ 391 HudBlk1_B_Rq 1;
BA_ "U_CD4_MY13_Phev_Rx" SG_ 391 HudBlk1_B_Rq 1;
BA_ "U_CD42_MY14_Diesel_Rx" SG_ 391 HudBlk1_B_Rq 1;
BA_ "U_CD42_MY14_Gas_Rx" SG_ 391 HudBlk1_B_Rq 1;
BA_ "U_P552_MY15_Gas_Rx" SG_ 391 HudBlk1_B_Rq 1;
BA_ "U_S550_MY15_Gas_Rx" SG_ 391 HudBlk1_B_Rq 1;
BA_ "U_C489_MY14_Gas_Rx" SG_ 391 HudBlk1_B_Rq 1;
BA_ "U_U502_MY15_Gas_Rx" SG_ 391 HudBlk1_B_Rq 1;
BA_ "U_UP375_MY15_Gas_Rx" SG_ 391 HudBlk1_B_Rq 1;
BA_ "U_UP375_MY15_Diesel_Rx" SG_ 391 HudBlk1_B_Rq 1;
BA_ "U_CD43_MY16_Gas_Rx" SG_ 391 HudBlk1_B_Rq 1;
BA_ "U_CD4_MY13_Diesel_Tx" SG_ 391 HudBlk1_B_Rq 1;
BA_ "U_CD4_MY13_Gas_Tx" SG_ 391 HudBlk1_B_Rq 1;
BA_ "U_CD4_MY13_Hev_Tx" SG_ 391 HudBlk1_B_Rq 1;
BA_ "U_CD4_MY13_Phev_Tx" SG_ 391 HudBlk1_B_Rq 1;
BA_ "U_CD42_MY14_Diesel_Tx" SG_ 391 HudBlk1_B_Rq 1;
BA_ "U_CD42_MY14_Gas_Tx" SG_ 391 HudBlk1_B_Rq 1;
BA_ "U_P552_MY15_Gas_Tx" SG_ 391 HudBlk1_B_Rq 1;
BA_ "U_S550_MY15_Gas_Tx" SG_ 391 HudBlk1_B_Rq 1;
BA_ "U_C489_MY14_Gas_Tx" SG_ 391 HudBlk1_B_Rq 1;
BA_ "U_U502_MY15_Gas_Tx" SG_ 391 HudBlk1_B_Rq 1;
BA_ "U_UP375_MY15_Gas_Tx" SG_ 391 HudBlk1_B_Rq 1;
BA_ "U_UP375_MY15_Diesel_Tx" SG_ 391 HudBlk1_B_Rq 1;
BA_ "U_CD43_MY16_Gas_Tx" SG_ 391 HudBlk1_B_Rq 1;
BA_ "U_CD4_MY13_Diesel_Rx" SG_ 391 HudFlashRate_D_Actl 1;
BA_ "U_CD4_MY13_Gas_Rx" SG_ 391 HudFlashRate_D_Actl 1;
BA_ "U_CD4_MY13_Hev_Rx" SG_ 391 HudFlashRate_D_Actl 1;
BA_ "U_CD4_MY13_Phev_Rx" SG_ 391 HudFlashRate_D_Actl 1;
BA_ "U_CD42_MY14_Diesel_Rx" SG_ 391 HudFlashRate_D_Actl 1;
BA_ "U_CD42_MY14_Gas_Rx" SG_ 391 HudFlashRate_D_Actl 1;
BA_ "U_P552_MY15_Gas_Rx" SG_ 391 HudFlashRate_D_Actl 1;
BA_ "U_C489_MY14_Gas_Rx" SG_ 391 HudFlashRate_D_Actl 1;
BA_ "U_U502_MY15_Gas_Rx" SG_ 391 HudFlashRate_D_Actl 1;
BA_ "U_UP375_MY15_Gas_Rx" SG_ 391 HudFlashRate_D_Actl 1;
BA_ "U_UP375_MY15_Diesel_Rx" SG_ 391 HudFlashRate_D_Actl 1;
BA_ "U_CD43_MY16_Gas_Rx" SG_ 391 HudFlashRate_D_Actl 1;
BA_ "U_CD4_MY14_Diesel_Rx" SG_ 391 HudFlashRate_D_Actl 1;
BA_ "U_CD4_MY14_Gas_Rx" SG_ 391 HudFlashRate_D_Actl 1;
BA_ "U_CD4_MY14_Hev_Rx" SG_ 391 HudFlashRate_D_Actl 1;
BA_ "U_CD4_MY14_Phev_Rx" SG_ 391 HudFlashRate_D_Actl 1;
BA_ "U_S550_MY15_Gas_Rx" SG_ 391 HudFlashRate_D_Actl 1;
BA_ "U_CD4_MY13_Diesel_Tx" SG_ 391 HudFlashRate_D_Actl 1;
BA_ "U_CD4_MY13_Gas_Tx" SG_ 391 HudFlashRate_D_Actl 1;
BA_ "U_CD4_MY13_Hev_Tx" SG_ 391 HudFlashRate_D_Actl 1;
BA_ "U_CD4_MY13_Phev_Tx" SG_ 391 HudFlashRate_D_Actl 1;
BA_ "U_CD42_MY14_Diesel_Tx" SG_ 391 HudFlashRate_D_Actl 1;
BA_ "U_CD42_MY14_Gas_Tx" SG_ 391 HudFlashRate_D_Actl 1;
BA_ "U_P552_MY15_Gas_Tx" SG_ 391 HudFlashRate_D_Actl 1;
BA_ "U_S550_MY15_Gas_Tx" SG_ 391 HudFlashRate_D_Actl 1;
BA_ "U_C489_MY14_Gas_Tx" SG_ 391 HudFlashRate_D_Actl 1;
BA_ "U_U502_MY15_Gas_Tx" SG_ 391 HudFlashRate_D_Actl 1;
BA_ "U_UP375_MY15_Gas_Tx" SG_ 391 HudFlashRate_D_Actl 1;
BA_ "U_UP375_MY15_Diesel_Tx" SG_ 391 HudFlashRate_D_Actl 1;
BA_ "U_CD43_MY16_Gas_Tx" SG_ 391 HudFlashRate_D_Actl 1;
BA_ "U_CD4_MY13_Diesel_Rx" SG_ 391 CmbbBrkDecel_No_Cs 1;
BA_ "U_CD4_MY13_Gas_Rx" SG_ 391 CmbbBrkDecel_No_Cs 1;
BA_ "U_CD4_MY13_Hev_Rx" SG_ 391 CmbbBrkDecel_No_Cs 1;
BA_ "U_CD4_MY13_Phev_Rx" SG_ 391 CmbbBrkDecel_No_Cs 1;
BA_ "U_CD42_MY14_Diesel_Rx" SG_ 391 CmbbBrkDecel_No_Cs 1;
BA_ "U_CD42_MY14_Gas_Rx" SG_ 391 CmbbBrkDecel_No_Cs 1;
BA_ "U_P552_MY15_Gas_Rx" SG_ 391 CmbbBrkDecel_No_Cs 1;
BA_ "U_S550_MY15_Gas_Rx" SG_ 391 CmbbBrkDecel_No_Cs 1;
BA_ "U_C489_MY14_Gas_Rx" SG_ 391 CmbbBrkDecel_No_Cs 1;
BA_ "U_U502_MY15_Gas_Rx" SG_ 391 CmbbBrkDecel_No_Cs 1;
BA_ "U_UP375_MY15_Gas_Rx" SG_ 391 CmbbBrkDecel_No_Cs 1;
BA_ "U_UP375_MY15_Diesel_Rx" SG_ 391 CmbbBrkDecel_No_Cs 1;
BA_ "U_CD43_MY16_Gas_Rx" SG_ 391 CmbbBrkDecel_No_Cs 1;
BA_ "U_CD4_MY13_Diesel_Tx" SG_ 391 CmbbBrkDecel_No_Cs 1;
BA_ "U_CD4_MY13_Gas_Tx" SG_ 391 CmbbBrkDecel_No_Cs 1;
BA_ "U_CD4_MY13_Hev_Tx" SG_ 391 CmbbBrkDecel_No_Cs 1;
BA_ "U_CD4_MY13_Phev_Tx" SG_ 391 CmbbBrkDecel_No_Cs 1;
BA_ "U_CD42_MY14_Diesel_Tx" SG_ 391 CmbbBrkDecel_No_Cs 1;
BA_ "U_CD42_MY14_Gas_Tx" SG_ 391 CmbbBrkDecel_No_Cs 1;
BA_ "U_P552_MY15_Gas_Tx" SG_ 391 CmbbBrkDecel_No_Cs 1;
BA_ "U_S550_MY15_Gas_Tx" SG_ 391 CmbbBrkDecel_No_Cs 1;
BA_ "U_C489_MY14_Gas_Tx" SG_ 391 CmbbBrkDecel_No_Cs 1;
BA_ "U_U502_MY15_Gas_Tx" SG_ 391 CmbbBrkDecel_No_Cs 1;
BA_ "U_UP375_MY15_Gas_Tx" SG_ 391 CmbbBrkDecel_No_Cs 1;
BA_ "U_UP375_MY15_Diesel_Tx" SG_ 391 CmbbBrkDecel_No_Cs 1;
BA_ "U_CD43_MY16_Gas_Tx" SG_ 391 CmbbBrkDecel_No_Cs 1;
BA_ "GenSigStartValue" SG_ 391 CmbbBrkDecel_A_Rq 5129;
BA_ "U_CD4_MY13_Diesel_Rx" SG_ 391 CmbbBrkDecel_A_Rq 1;
BA_ "U_CD4_MY13_Gas_Rx" SG_ 391 CmbbBrkDecel_A_Rq 1;
BA_ "U_CD4_MY13_Hev_Rx" SG_ 391 CmbbBrkDecel_A_Rq 1;
BA_ "U_CD4_MY13_Phev_Rx" SG_ 391 CmbbBrkDecel_A_Rq 1;
BA_ "U_CD42_MY14_Diesel_Rx" SG_ 391 CmbbBrkDecel_A_Rq 1;
BA_ "U_CD42_MY14_Gas_Rx" SG_ 391 CmbbBrkDecel_A_Rq 1;
BA_ "U_P552_MY15_Gas_Rx" SG_ 391 CmbbBrkDecel_A_Rq 1;
BA_ "U_S550_MY15_Gas_Rx" SG_ 391 CmbbBrkDecel_A_Rq 1;
BA_ "U_C489_MY14_Gas_Rx" SG_ 391 CmbbBrkDecel_A_Rq 1;
BA_ "U_U502_MY15_Gas_Rx" SG_ 391 CmbbBrkDecel_A_Rq 1;
BA_ "U_UP375_MY15_Gas_Rx" SG_ 391 CmbbBrkDecel_A_Rq 1;
BA_ "U_UP375_MY15_Diesel_Rx" SG_ 391 CmbbBrkDecel_A_Rq 1;
BA_ "U_CD43_MY16_Gas_Rx" SG_ 391 CmbbBrkDecel_A_Rq 1;
BA_ "U_CD4_MY13_Diesel_Tx" SG_ 391 CmbbBrkDecel_A_Rq 1;
BA_ "U_CD4_MY13_Gas_Tx" SG_ 391 CmbbBrkDecel_A_Rq 1;
BA_ "U_CD4_MY13_Hev_Tx" SG_ 391 CmbbBrkDecel_A_Rq 1;
BA_ "U_CD4_MY13_Phev_Tx" SG_ 391 CmbbBrkDecel_A_Rq 1;
BA_ "U_CD42_MY14_Diesel_Tx" SG_ 391 CmbbBrkDecel_A_Rq 1;
BA_ "U_CD42_MY14_Gas_Tx" SG_ 391 CmbbBrkDecel_A_Rq 1;
BA_ "U_P552_MY15_Gas_Tx" SG_ 391 CmbbBrkDecel_A_Rq 1;
BA_ "U_S550_MY15_Gas_Tx" SG_ 391 CmbbBrkDecel_A_Rq 1;
BA_ "U_C489_MY14_Gas_Tx" SG_ 391 CmbbBrkDecel_A_Rq 1;
BA_ "U_U502_MY15_Gas_Tx" SG_ 391 CmbbBrkDecel_A_Rq 1;
BA_ "U_UP375_MY15_Gas_Tx" SG_ 391 CmbbBrkDecel_A_Rq 1;
BA_ "U_UP375_MY15_Diesel_Tx" SG_ 391 CmbbBrkDecel_A_Rq 1;
BA_ "U_CD43_MY16_Gas_Tx" SG_ 391 CmbbBrkDecel_A_Rq 1;
BA_ "GenSigTimeoutTime_ABS_ESC" SG_ 391 CmbbBrkDecel_A_Rq 1000;
BA_ "U_CD4_MY13_Diesel_Rx" SG_ 391 CmbbBrkPrchg_D_Rq 1;
BA_ "U_CD4_MY13_Gas_Rx" SG_ 391 CmbbBrkPrchg_D_Rq 1;
BA_ "U_CD4_MY13_Hev_Rx" SG_ 391 CmbbBrkPrchg_D_Rq 1;
BA_ "U_CD4_MY13_Phev_Rx" SG_ 391 CmbbBrkPrchg_D_Rq 1;
BA_ "U_CD42_MY14_Diesel_Rx" SG_ 391 CmbbBrkPrchg_D_Rq 1;
BA_ "U_CD42_MY14_Gas_Rx" SG_ 391 CmbbBrkPrchg_D_Rq 1;
BA_ "U_P552_MY15_Gas_Rx" SG_ 391 CmbbBrkPrchg_D_Rq 1;
BA_ "U_S550_MY15_Gas_Rx" SG_ 391 CmbbBrkPrchg_D_Rq 1;
BA_ "U_C489_MY14_Gas_Rx" SG_ 391 CmbbBrkPrchg_D_Rq 1;
BA_ "U_U502_MY15_Gas_Rx" SG_ 391 CmbbBrkPrchg_D_Rq 1;
BA_ "U_UP375_MY15_Gas_Rx" SG_ 391 CmbbBrkPrchg_D_Rq 1;
BA_ "U_UP375_MY15_Diesel_Rx" SG_ 391 CmbbBrkPrchg_D_Rq 1;
BA_ "U_CD43_MY16_Gas_Rx" SG_ 391 CmbbBrkPrchg_D_Rq 1;
BA_ "U_CD4_MY13_Diesel_Tx" SG_ 391 CmbbBrkPrchg_D_Rq 1;
BA_ "U_CD4_MY13_Gas_Tx" SG_ 391 CmbbBrkPrchg_D_Rq 1;
BA_ "U_CD4_MY13_Hev_Tx" SG_ 391 CmbbBrkPrchg_D_Rq 1;
BA_ "U_CD4_MY13_Phev_Tx" SG_ 391 CmbbBrkPrchg_D_Rq 1;
BA_ "U_CD42_MY14_Diesel_Tx" SG_ 391 CmbbBrkPrchg_D_Rq 1;
BA_ "U_CD42_MY14_Gas_Tx" SG_ 391 CmbbBrkPrchg_D_Rq 1;
BA_ "U_P552_MY15_Gas_Tx" SG_ 391 CmbbBrkPrchg_D_Rq 1;
BA_ "U_S550_MY15_Gas_Tx" SG_ 391 CmbbBrkPrchg_D_Rq 1;
BA_ "U_C489_MY14_Gas_Tx" SG_ 391 CmbbBrkPrchg_D_Rq 1;
BA_ "U_U502_MY15_Gas_Tx" SG_ 391 CmbbBrkPrchg_D_Rq 1;
BA_ "U_UP375_MY15_Gas_Tx" SG_ 391 CmbbBrkPrchg_D_Rq 1;
BA_ "U_UP375_MY15_Diesel_Tx" SG_ 391 CmbbBrkPrchg_D_Rq 1;
BA_ "U_CD43_MY16_Gas_Tx" SG_ 391 CmbbBrkPrchg_D_Rq 1;
BA_ "GenSigTimeoutTime_ABS_ESC" SG_ 391 CmbbBrkPrchg_D_Rq 1000;
BA_ "U_CD4_MY13_Diesel_Rx" SG_ 391 CmbbBrkDecel_B_Rq 1;
BA_ "U_CD4_MY13_Gas_Rx" SG_ 391 CmbbBrkDecel_B_Rq 1;
BA_ "U_CD4_MY13_Hev_Rx" SG_ 391 CmbbBrkDecel_B_Rq 1;
BA_ "U_CD4_MY13_Phev_Rx" SG_ 391 CmbbBrkDecel_B_Rq 1;
BA_ "U_CD42_MY14_Diesel_Rx" SG_ 391 CmbbBrkDecel_B_Rq 1;
BA_ "U_CD42_MY14_Gas_Rx" SG_ 391 CmbbBrkDecel_B_Rq 1;
BA_ "U_P552_MY15_Gas_Rx" SG_ 391 CmbbBrkDecel_B_Rq 1;
BA_ "U_S550_MY15_Gas_Rx" SG_ 391 CmbbBrkDecel_B_Rq 1;
BA_ "U_C489_MY14_Gas_Rx" SG_ 391 CmbbBrkDecel_B_Rq 1;
BA_ "U_U502_MY15_Gas_Rx" SG_ 391 CmbbBrkDecel_B_Rq 1;
BA_ "U_UP375_MY15_Gas_Rx" SG_ 391 CmbbBrkDecel_B_Rq 1;
BA_ "U_UP375_MY15_Diesel_Rx" SG_ 391 CmbbBrkDecel_B_Rq 1;
BA_ "U_CD43_MY16_Gas_Rx" SG_ 391 CmbbBrkDecel_B_Rq 1;
BA_ "U_CD4_MY13_Diesel_Tx" SG_ 391 CmbbBrkDecel_B_Rq 1;
BA_ "U_CD4_MY13_Gas_Tx" SG_ 391 CmbbBrkDecel_B_Rq 1;
BA_ "U_CD4_MY13_Hev_Tx" SG_ 391 CmbbBrkDecel_B_Rq 1;
BA_ "U_CD4_MY13_Phev_Tx" SG_ 391 CmbbBrkDecel_B_Rq 1;
BA_ "U_CD42_MY14_Diesel_Tx" SG_ 391 CmbbBrkDecel_B_Rq 1;
BA_ "U_CD42_MY14_Gas_Tx" SG_ 391 CmbbBrkDecel_B_Rq 1;
BA_ "U_P552_MY15_Gas_Tx" SG_ 391 CmbbBrkDecel_B_Rq 1;
BA_ "U_S550_MY15_Gas_Tx" SG_ 391 CmbbBrkDecel_B_Rq 1;
BA_ "U_C489_MY14_Gas_Tx" SG_ 391 CmbbBrkDecel_B_Rq 1;
BA_ "U_U502_MY15_Gas_Tx" SG_ 391 CmbbBrkDecel_B_Rq 1;
BA_ "U_UP375_MY15_Gas_Tx" SG_ 391 CmbbBrkDecel_B_Rq 1;
BA_ "U_UP375_MY15_Diesel_Tx" SG_ 391 CmbbBrkDecel_B_Rq 1;
BA_ "U_CD43_MY16_Gas_Tx" SG_ 391 CmbbBrkDecel_B_Rq 1;
BA_ "GenSigTimeoutTime_ABS_ESC" SG_ 391 CmbbBrkDecel_B_Rq 1000;
BA_ "U_CD4_MY13_Diesel_Rx" SG_ 391 CmbbBaSens_D_Rq 1;
BA_ "U_CD4_MY13_Gas_Rx" SG_ 391 CmbbBaSens_D_Rq 1;
BA_ "U_CD4_MY13_Hev_Rx" SG_ 391 CmbbBaSens_D_Rq 1;
BA_ "U_CD4_MY13_Phev_Rx" SG_ 391 CmbbBaSens_D_Rq 1;
BA_ "U_CD42_MY14_Diesel_Rx" SG_ 391 CmbbBaSens_D_Rq 1;
BA_ "U_CD42_MY14_Gas_Rx" SG_ 391 CmbbBaSens_D_Rq 1;
BA_ "U_P552_MY15_Gas_Rx" SG_ 391 CmbbBaSens_D_Rq 1;
BA_ "U_S550_MY15_Gas_Rx" SG_ 391 CmbbBaSens_D_Rq 1;
BA_ "U_C489_MY14_Gas_Rx" SG_ 391 CmbbBaSens_D_Rq 1;
BA_ "U_U502_MY15_Gas_Rx" SG_ 391 CmbbBaSens_D_Rq 1;
BA_ "U_UP375_MY15_Gas_Rx" SG_ 391 CmbbBaSens_D_Rq 1;
BA_ "U_UP375_MY15_Diesel_Rx" SG_ 391 CmbbBaSens_D_Rq 1;
BA_ "U_CD43_MY16_Gas_Rx" SG_ 391 CmbbBaSens_D_Rq 1;
BA_ "U_CD4_MY13_Diesel_Tx" SG_ 391 CmbbBaSens_D_Rq 1;
BA_ "U_CD4_MY13_Gas_Tx" SG_ 391 CmbbBaSens_D_Rq 1;
BA_ "U_CD4_MY13_Hev_Tx" SG_ 391 CmbbBaSens_D_Rq 1;
BA_ "U_CD4_MY13_Phev_Tx" SG_ 391 CmbbBaSens_D_Rq 1;
BA_ "U_CD42_MY14_Diesel_Tx" SG_ 391 CmbbBaSens_D_Rq 1;
BA_ "U_CD42_MY14_Gas_Tx" SG_ 391 CmbbBaSens_D_Rq 1;
BA_ "U_P552_MY15_Gas_Tx" SG_ 391 CmbbBaSens_D_Rq 1;
BA_ "U_S550_MY15_Gas_Tx" SG_ 391 CmbbBaSens_D_Rq 1;
BA_ "U_C489_MY14_Gas_Tx" SG_ 391 CmbbBaSens_D_Rq 1;
BA_ "U_U502_MY15_Gas_Tx" SG_ 391 CmbbBaSens_D_Rq 1;
BA_ "U_UP375_MY15_Gas_Tx" SG_ 391 CmbbBaSens_D_Rq 1;
BA_ "U_UP375_MY15_Diesel_Tx" SG_ 391 CmbbBaSens_D_Rq 1;
BA_ "U_CD43_MY16_Gas_Tx" SG_ 391 CmbbBaSens_D_Rq 1;
BA_ "GenSigTimeoutTime_ABS_ESC" SG_ 391 CmbbBaSens_D_Rq 1000;
BA_ "U_CD4_MY13_Diesel_Rx" SG_ 535 WhlRr_W_Meas 1;
BA_ "U_CD4_MY13_Gas_Rx" SG_ 535 WhlRr_W_Meas 1;
BA_ "U_CD4_MY13_Hev_Rx" SG_ 535 WhlRr_W_Meas 1;
BA_ "U_CD4_MY13_Phev_Rx" SG_ 535 WhlRr_W_Meas 1;
BA_ "U_CD42_MY14_Diesel_Rx" SG_ 535 WhlRr_W_Meas 1;
BA_ "U_CD42_MY14_Gas_Rx" SG_ 535 WhlRr_W_Meas 1;
BA_ "U_P552_MY15_Gas_Rx" SG_ 535 WhlRr_W_Meas 1;
BA_ "U_C489_MY14_Gas_Rx" SG_ 535 WhlRr_W_Meas 1;
BA_ "U_U502_MY15_Gas_Rx" SG_ 535 WhlRr_W_Meas 1;
BA_ "U_UP375_MY15_Gas_Rx" SG_ 535 WhlRr_W_Meas 1;
BA_ "U_UP375_MY15_Diesel_Rx" SG_ 535 WhlRr_W_Meas 1;
BA_ "U_CD43_MY16_Gas_Rx" SG_ 535 WhlRr_W_Meas 1;
BA_ "U_CD4_MY13_Diesel_Tx" SG_ 535 WhlRr_W_Meas 1;
BA_ "U_CD4_MY13_Gas_Tx" SG_ 535 WhlRr_W_Meas 1;
BA_ "U_CD4_MY13_Hev_Tx" SG_ 535 WhlRr_W_Meas 1;
BA_ "U_CD4_MY13_Phev_Tx" SG_ 535 WhlRr_W_Meas 1;
BA_ "U_CD42_MY14_Diesel_Tx" SG_ 535 WhlRr_W_Meas 1;
BA_ "U_CD42_MY14_Gas_Tx" SG_ 535 WhlRr_W_Meas 1;
BA_ "U_P552_MY15_Gas_Tx" SG_ 535 WhlRr_W_Meas 1;
BA_ "U_S550_MY15_Gas_Tx" SG_ 535 WhlRr_W_Meas 1;
BA_ "U_C489_MY14_Gas_Tx" SG_ 535 WhlRr_W_Meas 1;
BA_ "U_B562LC_MY14_Diesel_Tx" SG_ 535 WhlRr_W_Meas 1;
BA_ "U_B562LC_MY14_Gas_Tx" SG_ 535 WhlRr_W_Meas 1;
BA_ "U_U502_MY15_Gas_Tx" SG_ 535 WhlRr_W_Meas 1;
BA_ "U_CD43_MY16_Gas_Tx" SG_ 535 WhlRr_W_Meas 1;
BA_ "U_CD4_MY13_Diesel_Rx" SG_ 535 WhlRl_W_Meas 1;
BA_ "U_CD4_MY13_Gas_Rx" SG_ 535 WhlRl_W_Meas 1;
BA_ "U_CD4_MY13_Hev_Rx" SG_ 535 WhlRl_W_Meas 1;
BA_ "U_CD4_MY13_Phev_Rx" SG_ 535 WhlRl_W_Meas 1;
BA_ "U_CD42_MY14_Diesel_Rx" SG_ 535 WhlRl_W_Meas 1;
BA_ "U_CD42_MY14_Gas_Rx" SG_ 535 WhlRl_W_Meas 1;
BA_ "U_P552_MY15_Gas_Rx" SG_ 535 WhlRl_W_Meas 1;
BA_ "U_C489_MY14_Gas_Rx" SG_ 535 WhlRl_W_Meas 1;
BA_ "U_U502_MY15_Gas_Rx" SG_ 535 WhlRl_W_Meas 1;
BA_ "U_UP375_MY15_Gas_Rx" SG_ 535 WhlRl_W_Meas 1;
BA_ "U_UP375_MY15_Diesel_Rx" SG_ 535 WhlRl_W_Meas 1;
BA_ "U_CD43_MY16_Gas_Rx" SG_ 535 WhlRl_W_Meas 1;
BA_ "U_CD4_MY13_Diesel_Tx" SG_ 535 WhlRl_W_Meas 1;
BA_ "U_CD4_MY13_Gas_Tx" SG_ 535 WhlRl_W_Meas 1;
BA_ "U_CD4_MY13_Hev_Tx" SG_ 535 WhlRl_W_Meas 1;
BA_ "U_CD4_MY13_Phev_Tx" SG_ 535 WhlRl_W_Meas 1;
BA_ "U_CD42_MY14_Diesel_Tx" SG_ 535 WhlRl_W_Meas 1;
BA_ "U_CD42_MY14_Gas_Tx" SG_ 535 WhlRl_W_Meas 1;
BA_ "U_P552_MY15_Gas_Tx" SG_ 535 WhlRl_W_Meas 1;
BA_ "U_S550_MY15_Gas_Tx" SG_ 535 WhlRl_W_Meas 1;
BA_ "U_C489_MY14_Gas_Tx" SG_ 535 WhlRl_W_Meas 1;
BA_ "U_B562LC_MY14_Diesel_Tx" SG_ 535 WhlRl_W_Meas 1;
BA_ "U_B562LC_MY14_Gas_Tx" SG_ 535 WhlRl_W_Meas 1;
BA_ "U_U502_MY15_Gas_Tx" SG_ 535 WhlRl_W_Meas 1;
BA_ "U_CD43_MY16_Gas_Tx" SG_ 535 WhlRl_W_Meas 1;
BA_ "U_CD4_MY13_Diesel_Rx" SG_ 535 WhlFr_W_Meas 1;
BA_ "U_CD4_MY13_Gas_Rx" SG_ 535 WhlFr_W_Meas 1;
BA_ "U_CD4_MY13_Hev_Rx" SG_ 535 WhlFr_W_Meas 1;
BA_ "U_CD4_MY13_Phev_Rx" SG_ 535 WhlFr_W_Meas 1;
BA_ "U_CD42_MY14_Diesel_Rx" SG_ 535 WhlFr_W_Meas 1;
BA_ "U_CD42_MY14_Gas_Rx" SG_ 535 WhlFr_W_Meas 1;
BA_ "U_P552_MY15_Gas_Rx" SG_ 535 WhlFr_W_Meas 1;
BA_ "U_S550_MY15_Gas_Rx" SG_ 535 WhlFr_W_Meas 1;
BA_ "U_C489_MY14_Gas_Rx" SG_ 535 WhlFr_W_Meas 1;
BA_ "U_U502_MY15_Gas_Rx" SG_ 535 WhlFr_W_Meas 1;
BA_ "U_UP375_MY15_Gas_Rx" SG_ 535 WhlFr_W_Meas 1;
BA_ "U_UP375_MY15_Diesel_Rx" SG_ 535 WhlFr_W_Meas 1;
BA_ "U_CD43_MY16_Gas_Rx" SG_ 535 WhlFr_W_Meas 1;
BA_ "U_CD4_MY13_Diesel_Tx" SG_ 535 WhlFr_W_Meas 1;
BA_ "U_CD4_MY13_Gas_Tx" SG_ 535 WhlFr_W_Meas 1;
BA_ "U_CD4_MY13_Hev_Tx" SG_ 535 WhlFr_W_Meas 1;
BA_ "U_CD4_MY13_Phev_Tx" SG_ 535 WhlFr_W_Meas 1;
BA_ "U_CD42_MY14_Diesel_Tx" SG_ 535 WhlFr_W_Meas 1;
BA_ "U_CD42_MY14_Gas_Tx" SG_ 535 WhlFr_W_Meas 1;
BA_ "U_P552_MY15_Gas_Tx" SG_ 535 WhlFr_W_Meas 1;
BA_ "U_S550_MY15_Gas_Tx" SG_ 535 WhlFr_W_Meas 1;
BA_ "U_C489_MY14_Gas_Tx" SG_ 535 WhlFr_W_Meas 1;
BA_ "U_B562LC_MY14_Diesel_Tx" SG_ 535 WhlFr_W_Meas 1;
BA_ "U_B562LC_MY14_Gas_Tx" SG_ 535 WhlFr_W_Meas 1;
BA_ "U_U502_MY15_Gas_Tx" SG_ 535 WhlFr_W_Meas 1;
BA_ "U_CD43_MY16_Gas_Tx" SG_ 535 WhlFr_W_Meas 1;
BA_ "U_CD4_MY13_Diesel_Rx" SG_ 535 WhlFl_W_Meas 1;
BA_ "U_CD4_MY13_Gas_Rx" SG_ 535 WhlFl_W_Meas 1;
BA_ "U_CD4_MY13_Hev_Rx" SG_ 535 WhlFl_W_Meas 1;
BA_ "U_CD4_MY13_Phev_Rx" SG_ 535 WhlFl_W_Meas 1;
BA_ "U_CD42_MY14_Diesel_Rx" SG_ 535 WhlFl_W_Meas 1;
BA_ "U_CD42_MY14_Gas_Rx" SG_ 535 WhlFl_W_Meas 1;
BA_ "U_P552_MY15_Gas_Rx" SG_ 535 WhlFl_W_Meas 1;
BA_ "U_S550_MY15_Gas_Rx" SG_ 535 WhlFl_W_Meas 1;
BA_ "U_C489_MY14_Gas_Rx" SG_ 535 WhlFl_W_Meas 1;
BA_ "U_U502_MY15_Gas_Rx" SG_ 535 WhlFl_W_Meas 1;
BA_ "U_UP375_MY15_Gas_Rx" SG_ 535 WhlFl_W_Meas 1;
BA_ "U_UP375_MY15_Diesel_Rx" SG_ 535 WhlFl_W_Meas 1;
BA_ "U_CD43_MY16_Gas_Rx" SG_ 535 WhlFl_W_Meas 1;
BA_ "U_CD4_MY13_Diesel_Tx" SG_ 535 WhlFl_W_Meas 1;
BA_ "U_CD4_MY13_Gas_Tx" SG_ 535 WhlFl_W_Meas 1;
BA_ "U_CD4_MY13_Hev_Tx" SG_ 535 WhlFl_W_Meas 1;
BA_ "U_CD4_MY13_Phev_Tx" SG_ 535 WhlFl_W_Meas 1;
BA_ "U_CD42_MY14_Diesel_Tx" SG_ 535 WhlFl_W_Meas 1;
BA_ "U_CD42_MY14_Gas_Tx" SG_ 535 WhlFl_W_Meas 1;
BA_ "U_P552_MY15_Gas_Tx" SG_ 535 WhlFl_W_Meas 1;
BA_ "U_S550_MY15_Gas_Tx" SG_ 535 WhlFl_W_Meas 1;
BA_ "U_C489_MY14_Gas_Tx" SG_ 535 WhlFl_W_Meas 1;
BA_ "U_B562LC_MY14_Diesel_Tx" SG_ 535 WhlFl_W_Meas 1;
BA_ "U_B562LC_MY14_Gas_Tx" SG_ 535 WhlFl_W_Meas 1;
BA_ "U_U502_MY15_Gas_Tx" SG_ 535 WhlFl_W_Meas 1;
BA_ "U_CD43_MY16_Gas_Tx" SG_ 535 WhlFl_W_Meas 1;
BA_ "U_CD4_MY13_Diesel_Tx" SG_ 532 PrplWhlTqRqMn_No_Cs 1;
BA_ "U_CD4_MY13_Gas_Tx" SG_ 532 PrplWhlTqRqMn_No_Cs 1;
BA_ "U_CD4_MY13_Hev_Tx" SG_ 532 PrplWhlTqRqMn_No_Cs 1;
BA_ "U_CD4_MY13_Phev_Tx" SG_ 532 PrplWhlTqRqMn_No_Cs 1;
BA_ "U_CD42_MY14_Diesel_Tx" SG_ 532 PrplWhlTqRqMn_No_Cs 1;
BA_ "U_CD42_MY14_Gas_Tx" SG_ 532 PrplWhlTqRqMn_No_Cs 1;
BA_ "U_P552_MY15_Gas_Tx" SG_ 532 PrplWhlTqRqMn_No_Cs 1;
BA_ "U_S550_MY15_Gas_Tx" SG_ 532 PrplWhlTqRqMn_No_Cs 1;
BA_ "U_C489_MY14_Gas_Tx" SG_ 532 PrplWhlTqRqMn_No_Cs 1;
BA_ "U_B562LC_MY14_Diesel_Tx" SG_ 532 PrplWhlTqRqMn_No_Cs 1;
BA_ "U_B562LC_MY14_Gas_Tx" SG_ 532 PrplWhlTqRqMn_No_Cs 1;
BA_ "U_U502_MY15_Gas_Tx" SG_ 532 PrplWhlTqRqMn_No_Cs 1;
BA_ "U_CD43_MY16_Gas_Tx" SG_ 532 PrplWhlTqRqMn_No_Cs 1;
BA_ "U_CD4_MY13_Diesel_Tx" SG_ 532 PrplWhlTot_Tq_RqMn 1;
BA_ "U_CD4_MY13_Gas_Tx" SG_ 532 PrplWhlTot_Tq_RqMn 1;
BA_ "U_CD4_MY13_Hev_Tx" SG_ 532 PrplWhlTot_Tq_RqMn 1;
BA_ "U_CD4_MY13_Phev_Tx" SG_ 532 PrplWhlTot_Tq_RqMn 1;
BA_ "U_CD42_MY14_Diesel_Tx" SG_ 532 PrplWhlTot_Tq_RqMn 1;
BA_ "U_CD42_MY14_Gas_Tx" SG_ 532 PrplWhlTot_Tq_RqMn 1;
BA_ "U_P552_MY15_Gas_Tx" SG_ 532 PrplWhlTot_Tq_RqMn 1;
BA_ "U_S550_MY15_Gas_Tx" SG_ 532 PrplWhlTot_Tq_RqMn 1;
BA_ "U_C489_MY14_Gas_Tx" SG_ 532 PrplWhlTot_Tq_RqMn 1;
BA_ "U_B562LC_MY14_Diesel_Tx" SG_ 532 PrplWhlTot_Tq_RqMn 1;
BA_ "U_B562LC_MY14_Gas_Tx" SG_ 532 PrplWhlTot_Tq_RqMn 1;
BA_ "U_U502_MY15_Gas_Tx" SG_ 532 PrplWhlTot_Tq_RqMn 1;
BA_ "U_UP375_MY15_Gas_Tx" SG_ 532 PrplWhlTot_Tq_RqMn 1;
BA_ "U_UP375_MY15_Diesel_Tx" SG_ 532 PrplWhlTot_Tq_RqMn 1;
BA_ "U_CD43_MY16_Gas_Tx" SG_ 532 PrplWhlTot_Tq_RqMn 1;
BA_ "U_CD4_MY13_Diesel_Tx" SG_ 532 PrplWhlTqRqMn_No_Cnt 1;
BA_ "U_CD4_MY13_Gas_Tx" SG_ 532 PrplWhlTqRqMn_No_Cnt 1;
BA_ "U_CD4_MY13_Hev_Tx" SG_ 532 PrplWhlTqRqMn_No_Cnt 1;
BA_ "U_CD4_MY13_Phev_Tx" SG_ 532 PrplWhlTqRqMn_No_Cnt 1;
BA_ "U_CD42_MY14_Diesel_Tx" SG_ 532 PrplWhlTqRqMn_No_Cnt 1;
BA_ "U_CD42_MY14_Gas_Tx" SG_ 532 PrplWhlTqRqMn_No_Cnt 1;
BA_ "U_P552_MY15_Gas_Tx" SG_ 532 PrplWhlTqRqMn_No_Cnt 1;
BA_ "U_S550_MY15_Gas_Tx" SG_ 532 PrplWhlTqRqMn_No_Cnt 1;
BA_ "U_C489_MY14_Gas_Tx" SG_ 532 PrplWhlTqRqMn_No_Cnt 1;
BA_ "U_B562LC_MY14_Diesel_Tx" SG_ 532 PrplWhlTqRqMn_No_Cnt 1;
BA_ "U_B562LC_MY14_Gas_Tx" SG_ 532 PrplWhlTqRqMn_No_Cnt 1;
BA_ "U_U502_MY15_Gas_Tx" SG_ 532 PrplWhlTqRqMn_No_Cnt 1;
BA_ "U_CD43_MY16_Gas_Tx" SG_ 532 PrplWhlTqRqMn_No_Cnt 1;
BA_ "CrossOver_InfoCAN" SG_ 531 VehicleStationary 1;
BA_ "U_CD4_MY13_Phev_Rx" SG_ 531 VehicleStationary 1;
BA_ "U_CD42_MY15_Diesel_Rx" SG_ 531 VehicleStationary 1;
BA_ "U_CD42_MY15_Gas_Rx" SG_ 531 VehicleStationary 1;
BA_ "U_UP375_MY15_Gas_Rx" SG_ 531 VehicleStationary 1;
BA_ "U_UP375_MY15_Diesel_Rx" SG_ 531 VehicleStationary 1;
BA_ "U_CD43_MY16_Gas_Rx" SG_ 531 VehicleStationary 1;
BA_ "U_CD4_MY14_Diesel_Rx" SG_ 531 VehicleStationary 1;
BA_ "U_CD4_MY14_Gas_Rx" SG_ 531 VehicleStationary 1;
BA_ "U_CD4_MY14_Hev_Rx" SG_ 531 VehicleStationary 1;
BA_ "U_CD4_MY14_Phev_Rx" SG_ 531 VehicleStationary 1;
BA_ "U_CD4_MY17_Diesel_Rx" SG_ 531 VehicleStationary 1;
BA_ "U_CD4_MY17_Gas_Rx" SG_ 531 VehicleStationary 1;
BA_ "U_CD4_MY17_Hev_Rx" SG_ 531 VehicleStationary 1;
BA_ "U_CD4_MY17_Phev_Rx" SG_ 531 VehicleStationary 1;
BA_ "U_CD42_MY16_Diesel_Rx" SG_ 531 VehicleStationary 1;
BA_ "U_CD42_MY16_Gas_Rx" SG_ 531 VehicleStationary 1;
BA_ "U_CD43_MY17_Gas_Rx" SG_ 531 VehicleStationary 1;
BA_ "U_U55x_MY18_Gas_Rx" SG_ 531 VehicleStationary 1;
BA_ "U_CD4_MY13_Diesel_Tx" SG_ 531 VehicleStationary 1;
BA_ "U_CD4_MY13_Gas_Tx" SG_ 531 VehicleStationary 1;
BA_ "U_CD4_MY13_Hev_Tx" SG_ 531 VehicleStationary 1;
BA_ "U_CD4_MY13_Phev_Tx" SG_ 531 VehicleStationary 1;
BA_ "U_CD42_MY15_Diesel_Tx" SG_ 531 VehicleStationary 1;
BA_ "U_CD42_MY15_Gas_Tx" SG_ 531 VehicleStationary 1;
BA_ "U_S550_MY15_Gas_Tx" SG_ 531 VehicleStationary 1;
BA_ "U_C489_MY14_Gas_Tx" SG_ 531 VehicleStationary 1;
BA_ "U_B562LC_MY15_Diesel_Tx" SG_ 531 VehicleStationary 1;
BA_ "U_B562LC_MY15_Gas_Tx" SG_ 531 VehicleStationary 1;
BA_ "U_U502_MY16_Gas_Tx" SG_ 531 VehicleStationary 1;
BA_ "U_CD43_MY16_Gas_Tx" SG_ 531 VehicleStationary 1;
BA_ "U_CD4_MY17_Diesel_Tx" SG_ 531 VehicleStationary 1;
BA_ "U_CD4_MY17_Gas_Tx" SG_ 531 VehicleStationary 1;
BA_ "U_CD4_MY17_Hev_Tx" SG_ 531 VehicleStationary 1;
BA_ "U_CD4_MY17_Phev_Tx" SG_ 531 VehicleStationary 1;
BA_ "U_C489_MY17_Gas_Tx" SG_ 531 VehicleStationary 1;
BA_ "U_CD42_MY16_Diesel_Tx" SG_ 531 VehicleStationary 1;
BA_ "U_CD42_MY16_Gas_Tx" SG_ 531 VehicleStationary 1;
BA_ "U_CD43_MY17_Gas_Tx" SG_ 531 VehicleStationary 1;
BA_ "U_U55x_MY18_Gas_Tx" SG_ 531 VehicleStationary 1;
BA_ "GenSigTimeoutTime_FDSM" SG_ 531 VehicleStationary 1000;
BA_ "GenSigStartValue" SG_ 531 VehStop_D_Stat 2;
BA_ "U_CD42_MY15_Diesel_Rx" SG_ 531 VehStop_D_Stat 1;
BA_ "U_CD42_MY15_Gas_Rx" SG_ 531 VehStop_D_Stat 1;
BA_ "U_CD43_MY16_Gas_Rx" SG_ 531 VehStop_D_Stat 1;
BA_ "U_CD4_MY17_Diesel_Rx" SG_ 531 VehStop_D_Stat 1;
BA_ "U_CD4_MY17_Gas_Rx" SG_ 531 VehStop_D_Stat 1;
BA_ "U_CD4_MY17_Hev_Rx" SG_ 531 VehStop_D_Stat 1;
BA_ "U_CD4_MY17_Phev_Rx" SG_ 531 VehStop_D_Stat 1;
BA_ "U_CD42_MY16_Diesel_Rx" SG_ 531 VehStop_D_Stat 1;
BA_ "U_CD42_MY16_Gas_Rx" SG_ 531 VehStop_D_Stat 1;
BA_ "U_CD43_MY17_Gas_Rx" SG_ 531 VehStop_D_Stat 1;
BA_ "U_U55x_MY18_Gas_Rx" SG_ 531 VehStop_D_Stat 1;
BA_ "U_CD42_MY15_Diesel_Tx" SG_ 531 VehStop_D_Stat 1;
BA_ "U_CD42_MY15_Gas_Tx" SG_ 531 VehStop_D_Stat 1;
BA_ "U_CD43_MY16_Gas_Tx" SG_ 531 VehStop_D_Stat 1;
BA_ "U_CD42_MY16_Diesel_Tx" SG_ 531 VehStop_D_Stat 1;
BA_ "U_CD42_MY16_Gas_Tx" SG_ 531 VehStop_D_Stat 1;
BA_ "U_CD43_MY17_Gas_Tx" SG_ 531 VehStop_D_Stat 1;
BA_ "CrossOver_InfoCAN" SG_ 531 AccStopActv_B_ActlBrk 1;
BA_ "U_CD4_MY13_Diesel_Rx" SG_ 531 AccStopActv_B_ActlBrk 1;
BA_ "U_CD4_MY13_Gas_Rx" SG_ 531 AccStopActv_B_ActlBrk 1;
BA_ "U_CD4_MY13_Hev_Rx" SG_ 531 AccStopActv_B_ActlBrk 1;
BA_ "U_CD4_MY13_Phev_Rx" SG_ 531 AccStopActv_B_ActlBrk 1;
BA_ "U_CD42_MY15_Diesel_Rx" SG_ 531 AccStopActv_B_ActlBrk 1;
BA_ "U_CD42_MY15_Gas_Rx" SG_ 531 AccStopActv_B_ActlBrk 1;
BA_ "U_UP375_MY15_Gas_Rx" SG_ 531 AccStopActv_B_ActlBrk 1;
BA_ "U_UP375_MY15_Diesel_Rx" SG_ 531 AccStopActv_B_ActlBrk 1;
BA_ "U_CD43_MY16_Gas_Rx" SG_ 531 AccStopActv_B_ActlBrk 1;
BA_ "U_CD4_MY14_Diesel_Rx" SG_ 531 AccStopActv_B_ActlBrk 1;
BA_ "U_CD4_MY14_Gas_Rx" SG_ 531 AccStopActv_B_ActlBrk 1;
BA_ "U_CD4_MY14_Hev_Rx" SG_ 531 AccStopActv_B_ActlBrk 1;
BA_ "U_CD4_MY14_Phev_Rx" SG_ 531 AccStopActv_B_ActlBrk 1;
BA_ "U_CD4_MY17_Diesel_Rx" SG_ 531 AccStopActv_B_ActlBrk 1;
BA_ "U_CD4_MY17_Gas_Rx" SG_ 531 AccStopActv_B_ActlBrk 1;
BA_ "U_CD4_MY17_Hev_Rx" SG_ 531 AccStopActv_B_ActlBrk 1;
BA_ "U_CD4_MY17_Phev_Rx" SG_ 531 AccStopActv_B_ActlBrk 1;
BA_ "U_CD42_MY16_Diesel_Rx" SG_ 531 AccStopActv_B_ActlBrk 1;
BA_ "U_CD42_MY16_Gas_Rx" SG_ 531 AccStopActv_B_ActlBrk 1;
BA_ "U_CD43_MY17_Gas_Rx" SG_ 531 AccStopActv_B_ActlBrk 1;
BA_ "U_U55x_MY18_Gas_Rx" SG_ 531 AccStopActv_B_ActlBrk 1;
BA_ "U_CD4_MY13_Diesel_Tx" SG_ 531 AccStopActv_B_ActlBrk 1;
BA_ "U_CD4_MY13_Gas_Tx" SG_ 531 AccStopActv_B_ActlBrk 1;
BA_ "U_CD4_MY13_Hev_Tx" SG_ 531 AccStopActv_B_ActlBrk 1;
BA_ "U_CD4_MY13_Phev_Tx" SG_ 531 AccStopActv_B_ActlBrk 1;
BA_ "U_CD42_MY15_Diesel_Tx" SG_ 531 AccStopActv_B_ActlBrk 1;
BA_ "U_CD42_MY15_Gas_Tx" SG_ 531 AccStopActv_B_ActlBrk 1;
BA_ "U_S550_MY15_Gas_Tx" SG_ 531 AccStopActv_B_ActlBrk 1;
BA_ "U_C489_MY14_Gas_Tx" SG_ 531 AccStopActv_B_ActlBrk 1;
BA_ "U_B562LC_MY15_Diesel_Tx" SG_ 531 AccStopActv_B_ActlBrk 1;
BA_ "U_B562LC_MY15_Gas_Tx" SG_ 531 AccStopActv_B_ActlBrk 1;
BA_ "U_U502_MY16_Gas_Tx" SG_ 531 AccStopActv_B_ActlBrk 1;
BA_ "U_CD43_MY16_Gas_Tx" SG_ 531 AccStopActv_B_ActlBrk 1;
BA_ "U_CD4_MY17_Diesel_Tx" SG_ 531 AccStopActv_B_ActlBrk 1;
BA_ "U_CD4_MY17_Gas_Tx" SG_ 531 AccStopActv_B_ActlBrk 1;
BA_ "U_CD4_MY17_Hev_Tx" SG_ 531 AccStopActv_B_ActlBrk 1;
BA_ "U_CD4_MY17_Phev_Tx" SG_ 531 AccStopActv_B_ActlBrk 1;
BA_ "U_C489_MY17_Gas_Tx" SG_ 531 AccStopActv_B_ActlBrk 1;
BA_ "U_CD42_MY16_Diesel_Tx" SG_ 531 AccStopActv_B_ActlBrk 1;
BA_ "U_CD42_MY16_Gas_Tx" SG_ 531 AccStopActv_B_ActlBrk 1;
BA_ "U_CD43_MY17_Gas_Tx" SG_ 531 AccStopActv_B_ActlBrk 1;
BA_ "U_U55x_MY18_Gas_Tx" SG_ 531 AccStopActv_B_ActlBrk 1;
BA_ "GenSigTimeoutTime_CCM" SG_ 531 AccStopActv_B_ActlBrk 1000;
BA_ "CrossOver_InfoCAN" SG_ 531 AccDis_B_ActlEpb 1;
BA_ "U_UP375_MY15_Gas_Rx" SG_ 531 AccDis_B_ActlEpb 1;
BA_ "U_UP375_MY15_Diesel_Rx" SG_ 531 AccDis_B_ActlEpb 1;
BA_ "U_CD43_MY16_Gas_Rx" SG_ 531 AccDis_B_ActlEpb 1;
BA_ "U_CD4_MY14_Diesel_Rx" SG_ 531 AccDis_B_ActlEpb 1;
BA_ "U_CD4_MY14_Gas_Rx" SG_ 531 AccDis_B_ActlEpb 1;
BA_ "U_CD4_MY14_Hev_Rx" SG_ 531 AccDis_B_ActlEpb 1;
BA_ "U_CD4_MY14_Phev_Rx" SG_ 531 AccDis_B_ActlEpb 1;
BA_ "U_CD4_MY17_Diesel_Rx" SG_ 531 AccDis_B_ActlEpb 1;
BA_ "U_CD4_MY17_Gas_Rx" SG_ 531 AccDis_B_ActlEpb 1;
BA_ "U_CD4_MY17_Hev_Rx" SG_ 531 AccDis_B_ActlEpb 1;
BA_ "U_CD4_MY17_Phev_Rx" SG_ 531 AccDis_B_ActlEpb 1;
BA_ "U_CD42_MY16_Diesel_Rx" SG_ 531 AccDis_B_ActlEpb 1;
BA_ "U_CD42_MY16_Gas_Rx" SG_ 531 AccDis_B_ActlEpb 1;
BA_ "U_CD43_MY17_Gas_Rx" SG_ 531 AccDis_B_ActlEpb 1;
BA_ "U_U55x_MY18_Gas_Rx" SG_ 531 AccDis_B_ActlEpb 1;
BA_ "U_CD4_MY13_Diesel_Tx" SG_ 531 AccDis_B_ActlEpb 1;
BA_ "U_CD4_MY13_Gas_Tx" SG_ 531 AccDis_B_ActlEpb 1;
BA_ "U_CD4_MY13_Hev_Tx" SG_ 531 AccDis_B_ActlEpb 1;
BA_ "U_CD4_MY13_Phev_Tx" SG_ 531 AccDis_B_ActlEpb 1;
BA_ "U_CD42_MY15_Diesel_Tx" SG_ 531 AccDis_B_ActlEpb 1;
BA_ "U_CD42_MY15_Gas_Tx" SG_ 531 AccDis_B_ActlEpb 1;
BA_ "U_C489_MY14_Gas_Tx" SG_ 531 AccDis_B_ActlEpb 1;
BA_ "U_B562LC_MY15_Diesel_Tx" SG_ 531 AccDis_B_ActlEpb 1;
BA_ "U_B562LC_MY15_Gas_Tx" SG_ 531 AccDis_B_ActlEpb 1;
BA_ "U_U502_MY16_Gas_Tx" SG_ 531 AccDis_B_ActlEpb 1;
BA_ "U_CD43_MY16_Gas_Tx" SG_ 531 AccDis_B_ActlEpb 1;
BA_ "U_CD4_MY17_Diesel_Tx" SG_ 531 AccDis_B_ActlEpb 1;
BA_ "U_CD4_MY17_Gas_Tx" SG_ 531 AccDis_B_ActlEpb 1;
BA_ "U_CD4_MY17_Hev_Tx" SG_ 531 AccDis_B_ActlEpb 1;
BA_ "U_CD4_MY17_Phev_Tx" SG_ 531 AccDis_B_ActlEpb 1;
BA_ "U_C489_MY17_Gas_Tx" SG_ 531 AccDis_B_ActlEpb 1;
BA_ "U_CD42_MY16_Diesel_Tx" SG_ 531 AccDis_B_ActlEpb 1;
BA_ "U_CD42_MY16_Gas_Tx" SG_ 531 AccDis_B_ActlEpb 1;
BA_ "U_CD43_MY17_Gas_Tx" SG_ 531 AccDis_B_ActlEpb 1;
BA_ "U_B515_MCA_MY17_Diesel_Tx" SG_ 531 AccDis_B_ActlEpb 1;
BA_ "U_B515_MCA_MY17_Gas_Tx" SG_ 531 AccDis_B_ActlEpb 1;
BA_ "U_U55x_MY18_Gas_Tx" SG_ 531 AccDis_B_ActlEpb 1;
BA_ "GenSigTimeoutTime_CCM" SG_ 531 AccDis_B_ActlEpb 1000;
BA_ "WakeupSignal" SG_ 531 PrkBrkYwLamp_D_Rq 1;
BA_ "CrossOver_InfoCAN" SG_ 531 PrkBrkYwLamp_D_Rq 1;
BA_ "U_CD4_MY13_Diesel_Rx" SG_ 531 PrkBrkYwLamp_D_Rq 1;
BA_ "U_CD4_MY13_Gas_Rx" SG_ 531 PrkBrkYwLamp_D_Rq 1;
BA_ "U_CD4_MY13_Hev_Rx" SG_ 531 PrkBrkYwLamp_D_Rq 1;
BA_ "U_CD4_MY13_Phev_Rx" SG_ 531 PrkBrkYwLamp_D_Rq 1;
BA_ "U_CD42_MY15_Diesel_Rx" SG_ 531 PrkBrkYwLamp_D_Rq 1;
BA_ "U_CD42_MY15_Gas_Rx" SG_ 531 PrkBrkYwLamp_D_Rq 1;
BA_ "U_P552_MY15_Gas_Rx" SG_ 531 PrkBrkYwLamp_D_Rq 1;
BA_ "U_S550_MY15_Gas_Rx" SG_ 531 PrkBrkYwLamp_D_Rq 1;
BA_ "U_C489_MY14_Gas_Rx" SG_ 531 PrkBrkYwLamp_D_Rq 1;
BA_ "U_U502_MY16_Gas_Rx" SG_ 531 PrkBrkYwLamp_D_Rq 1;
BA_ "U_B479_MY17_Gas_Rx" SG_ 531 PrkBrkYwLamp_D_Rq 1;
BA_ "U_UP375_MY15_Gas_Rx" SG_ 531 PrkBrkYwLamp_D_Rq 1;
BA_ "U_UP375_MY15_Diesel_Rx" SG_ 531 PrkBrkYwLamp_D_Rq 1;
BA_ "U_CD4_MY13_Diesel_Tx" SG_ 531 PrkBrkYwLamp_D_Rq 1;
BA_ "U_CD4_MY13_Gas_Tx" SG_ 531 PrkBrkYwLamp_D_Rq 1;
BA_ "U_CD4_MY13_Hev_Tx" SG_ 531 PrkBrkYwLamp_D_Rq 1;
BA_ "U_CD4_MY13_Phev_Tx" SG_ 531 PrkBrkYwLamp_D_Rq 1;
BA_ "U_CD42_MY15_Diesel_Tx" SG_ 531 PrkBrkYwLamp_D_Rq 1;
BA_ "U_CD42_MY15_Gas_Tx" SG_ 531 PrkBrkYwLamp_D_Rq 1;
BA_ "U_P552_MY15_Gas_Tx" SG_ 531 PrkBrkYwLamp_D_Rq 1;
BA_ "U_C489_MY14_Gas_Tx" SG_ 531 PrkBrkYwLamp_D_Rq 1;
BA_ "U_B562LC_MY15_Diesel_Tx" SG_ 531 PrkBrkYwLamp_D_Rq 1;
BA_ "U_B562LC_MY15_Gas_Tx" SG_ 531 PrkBrkYwLamp_D_Rq 1;
BA_ "U_U502_MY16_Gas_Tx" SG_ 531 PrkBrkYwLamp_D_Rq 1;
BA_ "U_CD43_MY16_Gas_Tx" SG_ 531 PrkBrkYwLamp_D_Rq 1;
BA_ "U_CD4_MY17_Diesel_Tx" SG_ 531 PrkBrkYwLamp_D_Rq 1;
BA_ "U_CD4_MY17_Gas_Tx" SG_ 531 PrkBrkYwLamp_D_Rq 1;
BA_ "U_CD4_MY17_Hev_Tx" SG_ 531 PrkBrkYwLamp_D_Rq 1;
BA_ "U_CD4_MY17_Phev_Tx" SG_ 531 PrkBrkYwLamp_D_Rq 1;
BA_ "U_P558_MY17_Gas_Tx" SG_ 531 PrkBrkYwLamp_D_Rq 1;
BA_ "U_P558_MY17_Diesel_Tx" SG_ 531 PrkBrkYwLamp_D_Rq 1;
BA_ "U_V36X_MY16_5_Diesel_Tx" SG_ 531 PrkBrkYwLamp_D_Rq 1;
BA_ "U_C489_MY17_Gas_Tx" SG_ 531 PrkBrkYwLamp_D_Rq 1;
BA_ "U_CD42_MY16_Diesel_Tx" SG_ 531 PrkBrkYwLamp_D_Rq 1;
BA_ "U_CD42_MY16_Gas_Tx" SG_ 531 PrkBrkYwLamp_D_Rq 1;
BA_ "U_CD43_MY17_Gas_Tx" SG_ 531 PrkBrkYwLamp_D_Rq 1;
BA_ "U_B515_MCA_MY17_Diesel_Tx" SG_ 531 PrkBrkYwLamp_D_Rq 1;
BA_ "U_B515_MCA_MY17_Gas_Tx" SG_ 531 PrkBrkYwLamp_D_Rq 1;
BA_ "U_U55x_MY18_Gas_Tx" SG_ 531 PrkBrkYwLamp_D_Rq 1;
BA_ "WakeupSignal" SG_ 531 PrkBrkRedLamp_D_Rq 1;
BA_ "CrossOver_InfoCAN" SG_ 531 PrkBrkRedLamp_D_Rq 1;
BA_ "U_CD4_MY13_Diesel_Rx" SG_ 531 PrkBrkRedLamp_D_Rq 1;
BA_ "U_CD4_MY13_Gas_Rx" SG_ 531 PrkBrkRedLamp_D_Rq 1;
BA_ "U_CD4_MY13_Hev_Rx" SG_ 531 PrkBrkRedLamp_D_Rq 1;
BA_ "U_CD4_MY13_Phev_Rx" SG_ 531 PrkBrkRedLamp_D_Rq 1;
BA_ "U_CD42_MY15_Diesel_Rx" SG_ 531 PrkBrkRedLamp_D_Rq 1;
BA_ "U_CD42_MY15_Gas_Rx" SG_ 531 PrkBrkRedLamp_D_Rq 1;
BA_ "U_P552_MY15_Gas_Rx" SG_ 531 PrkBrkRedLamp_D_Rq 1;
BA_ "U_S550_MY15_Gas_Rx" SG_ 531 PrkBrkRedLamp_D_Rq 1;
BA_ "U_C489_MY14_Gas_Rx" SG_ 531 PrkBrkRedLamp_D_Rq 1;
BA_ "U_U502_MY16_Gas_Rx" SG_ 531 PrkBrkRedLamp_D_Rq 1;
BA_ "U_B479_MY17_Gas_Rx" SG_ 531 PrkBrkRedLamp_D_Rq 1;
BA_ "U_UP375_MY15_Gas_Rx" SG_ 531 PrkBrkRedLamp_D_Rq 1;
BA_ "U_UP375_MY15_Diesel_Rx" SG_ 531 PrkBrkRedLamp_D_Rq 1;
BA_ "U_CD4_MY13_Diesel_Tx" SG_ 531 PrkBrkRedLamp_D_Rq 1;
BA_ "U_CD4_MY13_Gas_Tx" SG_ 531 PrkBrkRedLamp_D_Rq 1;
BA_ "U_CD4_MY13_Hev_Tx" SG_ 531 PrkBrkRedLamp_D_Rq 1;
BA_ "U_CD4_MY13_Phev_Tx" SG_ 531 PrkBrkRedLamp_D_Rq 1;
BA_ "U_CD42_MY15_Diesel_Tx" SG_ 531 PrkBrkRedLamp_D_Rq 1;
BA_ "U_CD42_MY15_Gas_Tx" SG_ 531 PrkBrkRedLamp_D_Rq 1;
BA_ "U_P552_MY15_Gas_Tx" SG_ 531 PrkBrkRedLamp_D_Rq 1;
BA_ "U_C489_MY14_Gas_Tx" SG_ 531 PrkBrkRedLamp_D_Rq 1;
BA_ "U_B562LC_MY15_Diesel_Tx" SG_ 531 PrkBrkRedLamp_D_Rq 1;
BA_ "U_B562LC_MY15_Gas_Tx" SG_ 531 PrkBrkRedLamp_D_Rq 1;
BA_ "U_U502_MY16_Gas_Tx" SG_ 531 PrkBrkRedLamp_D_Rq 1;
BA_ "U_CD43_MY16_Gas_Tx" SG_ 531 PrkBrkRedLamp_D_Rq 1;
BA_ "U_CD4_MY17_Diesel_Tx" SG_ 531 PrkBrkRedLamp_D_Rq 1;
BA_ "U_CD4_MY17_Gas_Tx" SG_ 531 PrkBrkRedLamp_D_Rq 1;
BA_ "U_CD4_MY17_Hev_Tx" SG_ 531 PrkBrkRedLamp_D_Rq 1;
BA_ "U_CD4_MY17_Phev_Tx" SG_ 531 PrkBrkRedLamp_D_Rq 1;
BA_ "U_P558_MY17_Gas_Tx" SG_ 531 PrkBrkRedLamp_D_Rq 1;
BA_ "U_P558_MY17_Diesel_Tx" SG_ 531 PrkBrkRedLamp_D_Rq 1;
BA_ "U_V36X_MY16_5_Diesel_Tx" SG_ 531 PrkBrkRedLamp_D_Rq 1;
BA_ "U_C489_MY17_Gas_Tx" SG_ 531 PrkBrkRedLamp_D_Rq 1;
BA_ "U_CD42_MY16_Diesel_Tx" SG_ 531 PrkBrkRedLamp_D_Rq 1;
BA_ "U_CD42_MY16_Gas_Tx" SG_ 531 PrkBrkRedLamp_D_Rq 1;
BA_ "U_CD43_MY17_Gas_Tx" SG_ 531 PrkBrkRedLamp_D_Rq 1;
BA_ "U_B515_MCA_MY17_Diesel_Tx" SG_ 531 PrkBrkRedLamp_D_Rq 1;
BA_ "U_B515_MCA_MY17_Gas_Tx" SG_ 531 PrkBrkRedLamp_D_Rq 1;
BA_ "U_U55x_MY18_Gas_Tx" SG_ 531 PrkBrkRedLamp_D_Rq 1;
BA_ "WakeupSignal" SG_ 531 PrkBrkMsgTxt_D_Rq 1;
BA_ "CrossOver_InfoCAN" SG_ 531 PrkBrkMsgTxt_D_Rq 1;
BA_ "U_CD4_MY13_Diesel_Rx" SG_ 531 PrkBrkMsgTxt_D_Rq 1;
BA_ "U_CD4_MY13_Gas_Rx" SG_ 531 PrkBrkMsgTxt_D_Rq 1;
BA_ "U_CD4_MY13_Hev_Rx" SG_ 531 PrkBrkMsgTxt_D_Rq 1;
BA_ "U_CD4_MY13_Phev_Rx" SG_ 531 PrkBrkMsgTxt_D_Rq 1;
BA_ "U_CD42_MY15_Diesel_Rx" SG_ 531 PrkBrkMsgTxt_D_Rq 1;
BA_ "U_CD42_MY15_Gas_Rx" SG_ 531 PrkBrkMsgTxt_D_Rq 1;
BA_ "U_P552_MY15_Gas_Rx" SG_ 531 PrkBrkMsgTxt_D_Rq 1;
BA_ "U_S550_MY15_Gas_Rx" SG_ 531 PrkBrkMsgTxt_D_Rq 1;
BA_ "U_C489_MY14_Gas_Rx" SG_ 531 PrkBrkMsgTxt_D_Rq 1;
BA_ "U_U502_MY16_Gas_Rx" SG_ 531 PrkBrkMsgTxt_D_Rq 1;
BA_ "U_B479_MY17_Gas_Rx" SG_ 531 PrkBrkMsgTxt_D_Rq 1;
BA_ "U_UP375_MY15_Gas_Rx" SG_ 531 PrkBrkMsgTxt_D_Rq 1;
BA_ "U_UP375_MY15_Diesel_Rx" SG_ 531 PrkBrkMsgTxt_D_Rq 1;
BA_ "U_CD4_MY13_Diesel_Tx" SG_ 531 PrkBrkMsgTxt_D_Rq 1;
BA_ "U_CD4_MY13_Gas_Tx" SG_ 531 PrkBrkMsgTxt_D_Rq 1;
BA_ "U_CD4_MY13_Hev_Tx" SG_ 531 PrkBrkMsgTxt_D_Rq 1;
BA_ "U_CD4_MY13_Phev_Tx" SG_ 531 PrkBrkMsgTxt_D_Rq 1;
BA_ "U_CD42_MY15_Diesel_Tx" SG_ 531 PrkBrkMsgTxt_D_Rq 1;
BA_ "U_CD42_MY15_Gas_Tx" SG_ 531 PrkBrkMsgTxt_D_Rq 1;
BA_ "U_P552_MY15_Gas_Tx" SG_ 531 PrkBrkMsgTxt_D_Rq 1;
BA_ "U_C489_MY14_Gas_Tx" SG_ 531 PrkBrkMsgTxt_D_Rq 1;
BA_ "U_B562LC_MY15_Diesel_Tx" SG_ 531 PrkBrkMsgTxt_D_Rq 1;
BA_ "U_B562LC_MY15_Gas_Tx" SG_ 531 PrkBrkMsgTxt_D_Rq 1;
BA_ "U_U502_MY16_Gas_Tx" SG_ 531 PrkBrkMsgTxt_D_Rq 1;
BA_ "U_CD43_MY16_Gas_Tx" SG_ 531 PrkBrkMsgTxt_D_Rq 1;
BA_ "U_CD4_MY17_Diesel_Tx" SG_ 531 PrkBrkMsgTxt_D_Rq 1;
BA_ "U_CD4_MY17_Gas_Tx" SG_ 531 PrkBrkMsgTxt_D_Rq 1;
BA_ "U_CD4_MY17_Hev_Tx" SG_ 531 PrkBrkMsgTxt_D_Rq 1;
BA_ "U_CD4_MY17_Phev_Tx" SG_ 531 PrkBrkMsgTxt_D_Rq 1;
BA_ "U_P558_MY17_Gas_Tx" SG_ 531 PrkBrkMsgTxt_D_Rq 1;
BA_ "U_P558_MY17_Diesel_Tx" SG_ 531 PrkBrkMsgTxt_D_Rq 1;
BA_ "U_V36X_MY16_5_Diesel_Tx" SG_ 531 PrkBrkMsgTxt_D_Rq 1;
BA_ "U_C489_MY17_Gas_Tx" SG_ 531 PrkBrkMsgTxt_D_Rq 1;
BA_ "U_CD42_MY16_Diesel_Tx" SG_ 531 PrkBrkMsgTxt_D_Rq 1;
BA_ "U_CD42_MY16_Gas_Tx" SG_ 531 PrkBrkMsgTxt_D_Rq 1;
BA_ "U_CD43_MY17_Gas_Tx" SG_ 531 PrkBrkMsgTxt_D_Rq 1;
BA_ "U_B515_MCA_MY17_Diesel_Tx" SG_ 531 PrkBrkMsgTxt_D_Rq 1;
BA_ "U_B515_MCA_MY17_Gas_Tx" SG_ 531 PrkBrkMsgTxt_D_Rq 1;
BA_ "U_U55x_MY18_Gas_Tx" SG_ 531 PrkBrkMsgTxt_D_Rq 1;
BA_ "CrossOver_InfoCAN" SG_ 531 TracCtlPtActv_B_Actl 1;
BA_ "U_CD42_MY14_Diesel_Rx" SG_ 531 TracCtlPtActv_B_Actl 1;
BA_ "U_CD42_MY14_Gas_Rx" SG_ 531 TracCtlPtActv_B_Actl 1;
BA_ "U_P552_MY15_Gas_Rx" SG_ 531 TracCtlPtActv_B_Actl 1;
BA_ "U_S550_MY15_Gas_Rx" SG_ 531 TracCtlPtActv_B_Actl 1;
BA_ "U_C489_MY14_Gas_Rx" SG_ 531 TracCtlPtActv_B_Actl 1;
BA_ "U_U502_MY15_Gas_Rx" SG_ 531 TracCtlPtActv_B_Actl 1;
BA_ "U_CD43_MY16_Gas_Rx" SG_ 531 TracCtlPtActv_B_Actl 1;
BA_ "U_UP375_MY15_Gas_Rx" SG_ 531 TracCtlPtActv_B_Actl 1;
BA_ "U_UP375_MY15_Diesel_Rx" SG_ 531 TracCtlPtActv_B_Actl 1;
BA_ "U_CD4_MY13_Diesel_Tx" SG_ 531 TracCtlPtActv_B_Actl 1;
BA_ "U_CD4_MY13_Gas_Tx" SG_ 531 TracCtlPtActv_B_Actl 1;
BA_ "U_CD4_MY13_Hev_Tx" SG_ 531 TracCtlPtActv_B_Actl 1;
BA_ "U_CD4_MY13_Phev_Tx" SG_ 531 TracCtlPtActv_B_Actl 1;
BA_ "U_CD42_MY14_Diesel_Tx" SG_ 531 TracCtlPtActv_B_Actl 1;
BA_ "U_CD42_MY14_Gas_Tx" SG_ 531 TracCtlPtActv_B_Actl 1;
BA_ "U_P552_MY15_Gas_Tx" SG_ 531 TracCtlPtActv_B_Actl 1;
BA_ "U_S550_MY15_Gas_Tx" SG_ 531 TracCtlPtActv_B_Actl 1;
BA_ "U_C489_MY14_Gas_Tx" SG_ 531 TracCtlPtActv_B_Actl 1;
BA_ "U_B562LC_MY14_Diesel_Tx" SG_ 531 TracCtlPtActv_B_Actl 1;
BA_ "U_B562LC_MY14_Gas_Tx" SG_ 531 TracCtlPtActv_B_Actl 1;
BA_ "U_U502_MY15_Gas_Tx" SG_ 531 TracCtlPtActv_B_Actl 1;
BA_ "U_UP375_MY15_Gas_Tx" SG_ 531 TracCtlPtActv_B_Actl 1;
BA_ "U_UP375_MY15_Diesel_Tx" SG_ 531 TracCtlPtActv_B_Actl 1;
BA_ "U_CD43_MY16_Gas_Tx" SG_ 531 TracCtlPtActv_B_Actl 1;
BA_ "CrossOver_InfoCAN" SG_ 531 AbsActv_B_Actl 1;
BA_ "U_CD4_MY13_Diesel_Rx" SG_ 531 AbsActv_B_Actl 1;
BA_ "U_CD4_MY13_Gas_Rx" SG_ 531 AbsActv_B_Actl 1;
BA_ "U_CD4_MY13_Hev_Rx" SG_ 531 AbsActv_B_Actl 1;
BA_ "U_CD4_MY13_Phev_Rx" SG_ 531 AbsActv_B_Actl 1;
BA_ "U_CD42_MY14_Diesel_Rx" SG_ 531 AbsActv_B_Actl 1;
BA_ "U_CD42_MY14_Gas_Rx" SG_ 531 AbsActv_B_Actl 1;
BA_ "U_P552_MY15_Gas_Rx" SG_ 531 AbsActv_B_Actl 1;
BA_ "U_S550_MY15_Gas_Rx" SG_ 531 AbsActv_B_Actl 1;
BA_ "U_C489_MY14_Gas_Rx" SG_ 531 AbsActv_B_Actl 1;
BA_ "U_U502_MY15_Gas_Rx" SG_ 531 AbsActv_B_Actl 1;
BA_ "U_UP375_MY15_Gas_Rx" SG_ 531 AbsActv_B_Actl 1;
BA_ "U_UP375_MY15_Diesel_Rx" SG_ 531 AbsActv_B_Actl 1;
BA_ "U_CD43_MY16_Gas_Rx" SG_ 531 AbsActv_B_Actl 1;
BA_ "U_CD4_MY13_Diesel_Tx" SG_ 531 AbsActv_B_Actl 1;
BA_ "U_CD4_MY13_Gas_Tx" SG_ 531 AbsActv_B_Actl 1;
BA_ "U_CD4_MY13_Hev_Tx" SG_ 531 AbsActv_B_Actl 1;
BA_ "U_CD4_MY13_Phev_Tx" SG_ 531 AbsActv_B_Actl 1;
BA_ "U_CD42_MY14_Diesel_Tx" SG_ 531 AbsActv_B_Actl 1;
BA_ "U_CD42_MY14_Gas_Tx" SG_ 531 AbsActv_B_Actl 1;
BA_ "U_P552_MY15_Gas_Tx" SG_ 531 AbsActv_B_Actl 1;
BA_ "U_S550_MY15_Gas_Tx" SG_ 531 AbsActv_B_Actl 1;
BA_ "U_C489_MY14_Gas_Tx" SG_ 531 AbsActv_B_Actl 1;
BA_ "U_B562LC_MY14_Diesel_Tx" SG_ 531 AbsActv_B_Actl 1;
BA_ "U_B562LC_MY14_Gas_Tx" SG_ 531 AbsActv_B_Actl 1;
BA_ "U_U502_MY15_Gas_Tx" SG_ 531 AbsActv_B_Actl 1;
BA_ "U_UP375_MY15_Gas_Tx" SG_ 531 AbsActv_B_Actl 1;
BA_ "U_UP375_MY15_Diesel_Tx" SG_ 531 AbsActv_B_Actl 1;
BA_ "U_CD43_MY16_Gas_Tx" SG_ 531 AbsActv_B_Actl 1;
BA_ "CrossOver_InfoCAN" SG_ 531 StabCtlBrkActv_B_Actl 1;
BA_ "U_P552_MY15_Gas_Rx" SG_ 531 StabCtlBrkActv_B_Actl 1;
BA_ "U_U502_MY15_Gas_Rx" SG_ 531 StabCtlBrkActv_B_Actl 1;
BA_ "U_UP375_MY15_Gas_Rx" SG_ 531 StabCtlBrkActv_B_Actl 1;
BA_ "U_UP375_MY15_Diesel_Rx" SG_ 531 StabCtlBrkActv_B_Actl 1;
BA_ "U_CD43_MY16_Gas_Rx" SG_ 531 StabCtlBrkActv_B_Actl 1;
BA_ "U_CD4_MY13_Diesel_Tx" SG_ 531 StabCtlBrkActv_B_Actl 1;
BA_ "U_CD4_MY13_Gas_Tx" SG_ 531 StabCtlBrkActv_B_Actl 1;
BA_ "U_CD4_MY13_Hev_Tx" SG_ 531 StabCtlBrkActv_B_Actl 1;
BA_ "U_CD4_MY13_Phev_Tx" SG_ 531 StabCtlBrkActv_B_Actl 1;
BA_ "U_CD42_MY14_Diesel_Tx" SG_ 531 StabCtlBrkActv_B_Actl 1;
BA_ "U_CD42_MY14_Gas_Tx" SG_ 531 StabCtlBrkActv_B_Actl 1;
BA_ "U_P552_MY15_Gas_Tx" SG_ 531 StabCtlBrkActv_B_Actl 1;
BA_ "U_S550_MY15_Gas_Tx" SG_ 531 StabCtlBrkActv_B_Actl 1;
BA_ "U_C489_MY14_Gas_Tx" SG_ 531 StabCtlBrkActv_B_Actl 1;
BA_ "U_B562LC_MY14_Diesel_Tx" SG_ 531 StabCtlBrkActv_B_Actl 1;
BA_ "U_B562LC_MY14_Gas_Tx" SG_ 531 StabCtlBrkActv_B_Actl 1;
BA_ "U_U502_MY15_Gas_Tx" SG_ 531 StabCtlBrkActv_B_Actl 1;
BA_ "U_UP375_MY15_Gas_Tx" SG_ 531 StabCtlBrkActv_B_Actl 1;
BA_ "U_UP375_MY15_Diesel_Tx" SG_ 531 StabCtlBrkActv_B_Actl 1;
BA_ "U_CD43_MY16_Gas_Tx" SG_ 531 StabCtlBrkActv_B_Actl 1;
BA_ "CrossOver_InfoCAN" SG_ 531 CmbbBrkPrchg_B_Actl 1;
BA_ "U_P552_MY15_Gas_Rx" SG_ 531 CmbbBrkPrchg_B_Actl 1;
BA_ "U_U502_MY15_Gas_Rx" SG_ 531 CmbbBrkPrchg_B_Actl 1;
BA_ "U_UP375_MY15_Gas_Rx" SG_ 531 CmbbBrkPrchg_B_Actl 1;
BA_ "U_UP375_MY15_Diesel_Rx" SG_ 531 CmbbBrkPrchg_B_Actl 1;
BA_ "U_CD43_MY16_Gas_Rx" SG_ 531 CmbbBrkPrchg_B_Actl 1;
BA_ "U_CD4_MY13_Diesel_Tx" SG_ 531 CmbbBrkPrchg_B_Actl 1;
BA_ "U_CD4_MY13_Gas_Tx" SG_ 531 CmbbBrkPrchg_B_Actl 1;
BA_ "U_CD4_MY13_Hev_Tx" SG_ 531 CmbbBrkPrchg_B_Actl 1;
BA_ "U_CD4_MY13_Phev_Tx" SG_ 531 CmbbBrkPrchg_B_Actl 1;
BA_ "U_CD42_MY14_Diesel_Tx" SG_ 531 CmbbBrkPrchg_B_Actl 1;
BA_ "U_CD42_MY14_Gas_Tx" SG_ 531 CmbbBrkPrchg_B_Actl 1;
BA_ "U_P552_MY15_Gas_Tx" SG_ 531 CmbbBrkPrchg_B_Actl 1;
BA_ "U_S550_MY15_Gas_Tx" SG_ 531 CmbbBrkPrchg_B_Actl 1;
BA_ "U_C489_MY14_Gas_Tx" SG_ 531 CmbbBrkPrchg_B_Actl 1;
BA_ "U_B562LC_MY14_Diesel_Tx" SG_ 531 CmbbBrkPrchg_B_Actl 1;
BA_ "U_B562LC_MY14_Gas_Tx" SG_ 531 CmbbBrkPrchg_B_Actl 1;
BA_ "U_U502_MY15_Gas_Tx" SG_ 531 CmbbBrkPrchg_B_Actl 1;
BA_ "U_UP375_MY15_Gas_Tx" SG_ 531 CmbbBrkPrchg_B_Actl 1;
BA_ "U_UP375_MY15_Diesel_Tx" SG_ 531 CmbbBrkPrchg_B_Actl 1;
BA_ "U_CD43_MY16_Gas_Tx" SG_ 531 CmbbBrkPrchg_B_Actl 1;
BA_ "CrossOver_InfoCAN" SG_ 531 CmbbBrkDecel_B_Actl 1;
BA_ "U_P552_MY15_Gas_Rx" SG_ 531 CmbbBrkDecel_B_Actl 1;
BA_ "U_U502_MY15_Gas_Rx" SG_ 531 CmbbBrkDecel_B_Actl 1;
BA_ "U_UP375_MY15_Gas_Rx" SG_ 531 CmbbBrkDecel_B_Actl 1;
BA_ "U_UP375_MY15_Diesel_Rx" SG_ 531 CmbbBrkDecel_B_Actl 1;
BA_ "U_CD43_MY16_Gas_Rx" SG_ 531 CmbbBrkDecel_B_Actl 1;
BA_ "U_CD4_MY13_Diesel_Tx" SG_ 531 CmbbBrkDecel_B_Actl 1;
BA_ "U_CD4_MY13_Gas_Tx" SG_ 531 CmbbBrkDecel_B_Actl 1;
BA_ "U_CD4_MY13_Hev_Tx" SG_ 531 CmbbBrkDecel_B_Actl 1;
BA_ "U_CD4_MY13_Phev_Tx" SG_ 531 CmbbBrkDecel_B_Actl 1;
BA_ "U_CD42_MY14_Diesel_Tx" SG_ 531 CmbbBrkDecel_B_Actl 1;
BA_ "U_CD42_MY14_Gas_Tx" SG_ 531 CmbbBrkDecel_B_Actl 1;
BA_ "U_P552_MY15_Gas_Tx" SG_ 531 CmbbBrkDecel_B_Actl 1;
BA_ "U_S550_MY15_Gas_Tx" SG_ 531 CmbbBrkDecel_B_Actl 1;
BA_ "U_C489_MY14_Gas_Tx" SG_ 531 CmbbBrkDecel_B_Actl 1;
BA_ "U_B562LC_MY14_Diesel_Tx" SG_ 531 CmbbBrkDecel_B_Actl 1;
BA_ "U_B562LC_MY14_Gas_Tx" SG_ 531 CmbbBrkDecel_B_Actl 1;
BA_ "U_U502_MY15_Gas_Tx" SG_ 531 CmbbBrkDecel_B_Actl 1;
BA_ "U_UP375_MY15_Gas_Tx" SG_ 531 CmbbBrkDecel_B_Actl 1;
BA_ "U_UP375_MY15_Diesel_Tx" SG_ 531 CmbbBrkDecel_B_Actl 1;
BA_ "U_CD43_MY16_Gas_Tx" SG_ 531 CmbbBrkDecel_B_Actl 1;
BA_ "CrossOver_InfoCAN" SG_ 531 CmbbBaSensInc_B_Actl 1;
BA_ "U_U502_MY15_Gas_Rx" SG_ 531 CmbbBaSensInc_B_Actl 1;
BA_ "U_UP375_MY15_Gas_Rx" SG_ 531 CmbbBaSensInc_B_Actl 1;
BA_ "U_UP375_MY15_Diesel_Rx" SG_ 531 CmbbBaSensInc_B_Actl 1;
BA_ "U_CD43_MY16_Gas_Rx" SG_ 531 CmbbBaSensInc_B_Actl 1;
BA_ "U_CD4_MY13_Diesel_Tx" SG_ 531 CmbbBaSensInc_B_Actl 1;
BA_ "U_CD4_MY13_Gas_Tx" SG_ 531 CmbbBaSensInc_B_Actl 1;
BA_ "U_CD4_MY13_Hev_Tx" SG_ 531 CmbbBaSensInc_B_Actl 1;
BA_ "U_CD4_MY13_Phev_Tx" SG_ 531 CmbbBaSensInc_B_Actl 1;
BA_ "U_CD42_MY14_Diesel_Tx" SG_ 531 CmbbBaSensInc_B_Actl 1;
BA_ "U_CD42_MY14_Gas_Tx" SG_ 531 CmbbBaSensInc_B_Actl 1;
BA_ "U_P552_MY15_Gas_Tx" SG_ 531 CmbbBaSensInc_B_Actl 1;
BA_ "U_S550_MY15_Gas_Tx" SG_ 531 CmbbBaSensInc_B_Actl 1;
BA_ "U_C489_MY14_Gas_Tx" SG_ 531 CmbbBaSensInc_B_Actl 1;
BA_ "U_B562LC_MY14_Diesel_Tx" SG_ 531 CmbbBaSensInc_B_Actl 1;
BA_ "U_B562LC_MY14_Gas_Tx" SG_ 531 CmbbBaSensInc_B_Actl 1;
BA_ "U_U502_MY15_Gas_Tx" SG_ 531 CmbbBaSensInc_B_Actl 1;
BA_ "U_UP375_MY15_Gas_Tx" SG_ 531 CmbbBaSensInc_B_Actl 1;
BA_ "U_UP375_MY15_Diesel_Tx" SG_ 531 CmbbBaSensInc_B_Actl 1;
BA_ "U_CD43_MY16_Gas_Tx" SG_ 531 CmbbBaSensInc_B_Actl 1;
BA_ "CrossOver_InfoCAN" SG_ 531 AccBrkWarm_B_Actl 1;
BA_ "U_U502_MY15_Gas_Rx" SG_ 531 AccBrkWarm_B_Actl 1;
BA_ "U_UP375_MY15_Gas_Rx" SG_ 531 AccBrkWarm_B_Actl 1;
BA_ "U_UP375_MY15_Diesel_Rx" SG_ 531 AccBrkWarm_B_Actl 1;
BA_ "U_CD43_MY16_Gas_Rx" SG_ 531 AccBrkWarm_B_Actl 1;
BA_ "U_CD4_MY13_Diesel_Tx" SG_ 531 AccBrkWarm_B_Actl 1;
BA_ "U_CD4_MY13_Gas_Tx" SG_ 531 AccBrkWarm_B_Actl 1;
BA_ "U_CD4_MY13_Hev_Tx" SG_ 531 AccBrkWarm_B_Actl 1;
BA_ "U_CD4_MY13_Phev_Tx" SG_ 531 AccBrkWarm_B_Actl 1;
BA_ "U_CD42_MY14_Diesel_Tx" SG_ 531 AccBrkWarm_B_Actl 1;
BA_ "U_CD42_MY14_Gas_Tx" SG_ 531 AccBrkWarm_B_Actl 1;
BA_ "U_P552_MY15_Gas_Tx" SG_ 531 AccBrkWarm_B_Actl 1;
BA_ "U_S550_MY15_Gas_Tx" SG_ 531 AccBrkWarm_B_Actl 1;
BA_ "U_C489_MY14_Gas_Tx" SG_ 531 AccBrkWarm_B_Actl 1;
BA_ "U_B562LC_MY14_Diesel_Tx" SG_ 531 AccBrkWarm_B_Actl 1;
BA_ "U_B562LC_MY14_Gas_Tx" SG_ 531 AccBrkWarm_B_Actl 1;
BA_ "U_U502_MY15_Gas_Tx" SG_ 531 AccBrkWarm_B_Actl 1;
BA_ "U_UP375_MY15_Gas_Tx" SG_ 531 AccBrkWarm_B_Actl 1;
BA_ "U_UP375_MY15_Diesel_Tx" SG_ 531 AccBrkWarm_B_Actl 1;
BA_ "U_CD43_MY16_Gas_Tx" SG_ 531 AccBrkWarm_B_Actl 1;
BA_ "CrossOver_InfoCAN" SG_ 531 AccBrkTotTqMn_B_Actl 1;
BA_ "U_P552_MY15_Gas_Rx" SG_ 531 AccBrkTotTqMn_B_Actl 1;
BA_ "U_U502_MY15_Gas_Rx" SG_ 531 AccBrkTotTqMn_B_Actl 1;
BA_ "U_UP375_MY15_Gas_Rx" SG_ 531 AccBrkTotTqMn_B_Actl 1;
BA_ "U_UP375_MY15_Diesel_Rx" SG_ 531 AccBrkTotTqMn_B_Actl 1;
BA_ "U_CD43_MY16_Gas_Rx" SG_ 531 AccBrkTotTqMn_B_Actl 1;
BA_ "U_CD4_MY13_Diesel_Tx" SG_ 531 AccBrkTotTqMn_B_Actl 1;
BA_ "U_CD4_MY13_Gas_Tx" SG_ 531 AccBrkTotTqMn_B_Actl 1;
BA_ "U_CD4_MY13_Hev_Tx" SG_ 531 AccBrkTotTqMn_B_Actl 1;
BA_ "U_CD4_MY13_Phev_Tx" SG_ 531 AccBrkTotTqMn_B_Actl 1;
BA_ "U_CD42_MY14_Diesel_Tx" SG_ 531 AccBrkTotTqMn_B_Actl 1;
BA_ "U_CD42_MY14_Gas_Tx" SG_ 531 AccBrkTotTqMn_B_Actl 1;
BA_ "U_P552_MY15_Gas_Tx" SG_ 531 AccBrkTotTqMn_B_Actl 1;
BA_ "U_S550_MY15_Gas_Tx" SG_ 531 AccBrkTotTqMn_B_Actl 1;
BA_ "U_C489_MY14_Gas_Tx" SG_ 531 AccBrkTotTqMn_B_Actl 1;
BA_ "U_B562LC_MY14_Diesel_Tx" SG_ 531 AccBrkTotTqMn_B_Actl 1;
BA_ "U_B562LC_MY14_Gas_Tx" SG_ 531 AccBrkTotTqMn_B_Actl 1;
BA_ "U_U502_MY15_Gas_Tx" SG_ 531 AccBrkTotTqMn_B_Actl 1;
BA_ "U_UP375_MY15_Gas_Tx" SG_ 531 AccBrkTotTqMn_B_Actl 1;
BA_ "U_UP375_MY15_Diesel_Tx" SG_ 531 AccBrkTotTqMn_B_Actl 1;
BA_ "U_CD43_MY16_Gas_Tx" SG_ 531 AccBrkTotTqMn_B_Actl 1;
BA_ "GenSigTimeoutTime_CCM" SG_ 531 AccBrkTotTqMn_B_Actl 1000;
BA_ "CrossOver_InfoCAN" SG_ 531 AccBrkPrchgActv_B_Actl 1;
BA_ "U_U502_MY15_Gas_Rx" SG_ 531 AccBrkPrchgActv_B_Actl 1;
BA_ "U_UP375_MY15_Gas_Rx" SG_ 531 AccBrkPrchgActv_B_Actl 1;
BA_ "U_UP375_MY15_Diesel_Rx" SG_ 531 AccBrkPrchgActv_B_Actl 1;
BA_ "U_CD43_MY16_Gas_Rx" SG_ 531 AccBrkPrchgActv_B_Actl 1;
BA_ "U_CD4_MY13_Diesel_Tx" SG_ 531 AccBrkPrchgActv_B_Actl 1;
BA_ "U_CD4_MY13_Gas_Tx" SG_ 531 AccBrkPrchgActv_B_Actl 1;
BA_ "U_CD4_MY13_Hev_Tx" SG_ 531 AccBrkPrchgActv_B_Actl 1;
BA_ "U_CD4_MY13_Phev_Tx" SG_ 531 AccBrkPrchgActv_B_Actl 1;
BA_ "U_CD42_MY14_Diesel_Tx" SG_ 531 AccBrkPrchgActv_B_Actl 1;
BA_ "U_CD42_MY14_Gas_Tx" SG_ 531 AccBrkPrchgActv_B_Actl 1;
BA_ "U_P552_MY15_Gas_Tx" SG_ 531 AccBrkPrchgActv_B_Actl 1;
BA_ "U_S550_MY15_Gas_Tx" SG_ 531 AccBrkPrchgActv_B_Actl 1;
BA_ "U_C489_MY14_Gas_Tx" SG_ 531 AccBrkPrchgActv_B_Actl 1;
BA_ "U_B562LC_MY14_Diesel_Tx" SG_ 531 AccBrkPrchgActv_B_Actl 1;
BA_ "U_B562LC_MY14_Gas_Tx" SG_ 531 AccBrkPrchgActv_B_Actl 1;
BA_ "U_U502_MY15_Gas_Tx" SG_ 531 AccBrkPrchgActv_B_Actl 1;
BA_ "U_UP375_MY15_Gas_Tx" SG_ 531 AccBrkPrchgActv_B_Actl 1;
BA_ "U_UP375_MY15_Diesel_Tx" SG_ 531 AccBrkPrchgActv_B_Actl 1;
BA_ "U_CD43_MY16_Gas_Tx" SG_ 531 AccBrkPrchgActv_B_Actl 1;
BA_ "CrossOver_InfoCAN" SG_ 531 AccBrkDis_B_Actl 1;
BA_ "U_U502_MY15_Gas_Rx" SG_ 531 AccBrkDis_B_Actl 1;
BA_ "U_UP375_MY15_Gas_Rx" SG_ 531 AccBrkDis_B_Actl 1;
BA_ "U_UP375_MY15_Diesel_Rx" SG_ 531 AccBrkDis_B_Actl 1;
BA_ "U_CD43_MY16_Gas_Rx" SG_ 531 AccBrkDis_B_Actl 1;
BA_ "U_CD4_MY13_Diesel_Tx" SG_ 531 AccBrkDis_B_Actl 1;
BA_ "U_CD4_MY13_Gas_Tx" SG_ 531 AccBrkDis_B_Actl 1;
BA_ "U_CD4_MY13_Hev_Tx" SG_ 531 AccBrkDis_B_Actl 1;
BA_ "U_CD4_MY13_Phev_Tx" SG_ 531 AccBrkDis_B_Actl 1;
BA_ "U_CD42_MY14_Diesel_Tx" SG_ 531 AccBrkDis_B_Actl 1;
BA_ "U_CD42_MY14_Gas_Tx" SG_ 531 AccBrkDis_B_Actl 1;
BA_ "U_P552_MY15_Gas_Tx" SG_ 531 AccBrkDis_B_Actl 1;
BA_ "U_S550_MY15_Gas_Tx" SG_ 531 AccBrkDis_B_Actl 1;
BA_ "U_C489_MY14_Gas_Tx" SG_ 531 AccBrkDis_B_Actl 1;
BA_ "U_B562LC_MY14_Diesel_Tx" SG_ 531 AccBrkDis_B_Actl 1;
BA_ "U_B562LC_MY14_Gas_Tx" SG_ 531 AccBrkDis_B_Actl 1;
BA_ "U_U502_MY15_Gas_Tx" SG_ 531 AccBrkDis_B_Actl 1;
BA_ "U_UP375_MY15_Gas_Tx" SG_ 531 AccBrkDis_B_Actl 1;
BA_ "U_UP375_MY15_Diesel_Tx" SG_ 531 AccBrkDis_B_Actl 1;
BA_ "U_CD43_MY16_Gas_Tx" SG_ 531 AccBrkDis_B_Actl 1;
BA_ "CrossOver_InfoCAN" SG_ 531 AccBrkDeny_B_Actl 1;
BA_ "U_U502_MY15_Gas_Rx" SG_ 531 AccBrkDeny_B_Actl 1;
BA_ "U_UP375_MY15_Gas_Rx" SG_ 531 AccBrkDeny_B_Actl 1;
BA_ "U_UP375_MY15_Diesel_Rx" SG_ 531 AccBrkDeny_B_Actl 1;
BA_ "U_CD43_MY16_Gas_Rx" SG_ 531 AccBrkDeny_B_Actl 1;
BA_ "U_CD4_MY13_Diesel_Tx" SG_ 531 AccBrkDeny_B_Actl 1;
BA_ "U_CD4_MY13_Gas_Tx" SG_ 531 AccBrkDeny_B_Actl 1;
BA_ "U_CD4_MY13_Hev_Tx" SG_ 531 AccBrkDeny_B_Actl 1;
BA_ "U_CD4_MY13_Phev_Tx" SG_ 531 AccBrkDeny_B_Actl 1;
BA_ "U_CD42_MY14_Diesel_Tx" SG_ 531 AccBrkDeny_B_Actl 1;
BA_ "U_CD42_MY14_Gas_Tx" SG_ 531 AccBrkDeny_B_Actl 1;
BA_ "U_P552_MY15_Gas_Tx" SG_ 531 AccBrkDeny_B_Actl 1;
BA_ "U_S550_MY15_Gas_Tx" SG_ 531 AccBrkDeny_B_Actl 1;
BA_ "U_C489_MY14_Gas_Tx" SG_ 531 AccBrkDeny_B_Actl 1;
BA_ "U_B562LC_MY14_Diesel_Tx" SG_ 531 AccBrkDeny_B_Actl 1;
BA_ "U_B562LC_MY14_Gas_Tx" SG_ 531 AccBrkDeny_B_Actl 1;
BA_ "U_U502_MY15_Gas_Tx" SG_ 531 AccBrkDeny_B_Actl 1;
BA_ "U_UP375_MY15_Gas_Tx" SG_ 531 AccBrkDeny_B_Actl 1;
BA_ "U_UP375_MY15_Diesel_Tx" SG_ 531 AccBrkDeny_B_Actl 1;
BA_ "U_CD43_MY16_Gas_Tx" SG_ 531 AccBrkDeny_B_Actl 1;
BA_ "GenSigTimeoutTime_CCM" SG_ 531 AccBrkDeny_B_Actl 1000;
BA_ "CrossOver_InfoCAN" SG_ 531 AccBrkActv_B_Actl 1;
BA_ "U_U502_MY15_Gas_Rx" SG_ 531 AccBrkActv_B_Actl 1;
BA_ "U_UP375_MY15_Gas_Rx" SG_ 531 AccBrkActv_B_Actl 1;
BA_ "U_UP375_MY15_Diesel_Rx" SG_ 531 AccBrkActv_B_Actl 1;
BA_ "U_CD43_MY16_Gas_Rx" SG_ 531 AccBrkActv_B_Actl 1;
BA_ "U_CD4_MY13_Diesel_Tx" SG_ 531 AccBrkActv_B_Actl 1;
BA_ "U_CD4_MY13_Gas_Tx" SG_ 531 AccBrkActv_B_Actl 1;
BA_ "U_CD4_MY13_Hev_Tx" SG_ 531 AccBrkActv_B_Actl 1;
BA_ "U_CD4_MY13_Phev_Tx" SG_ 531 AccBrkActv_B_Actl 1;
BA_ "U_CD42_MY14_Diesel_Tx" SG_ 531 AccBrkActv_B_Actl 1;
BA_ "U_CD42_MY14_Gas_Tx" SG_ 531 AccBrkActv_B_Actl 1;
BA_ "U_P552_MY15_Gas_Tx" SG_ 531 AccBrkActv_B_Actl 1;
BA_ "U_S550_MY15_Gas_Tx" SG_ 531 AccBrkActv_B_Actl 1;
BA_ "U_C489_MY14_Gas_Tx" SG_ 531 AccBrkActv_B_Actl 1;
BA_ "U_B562LC_MY14_Diesel_Tx" SG_ 531 AccBrkActv_B_Actl 1;
BA_ "U_B562LC_MY14_Gas_Tx" SG_ 531 AccBrkActv_B_Actl 1;
BA_ "U_U502_MY15_Gas_Tx" SG_ 531 AccBrkActv_B_Actl 1;
BA_ "U_UP375_MY15_Gas_Tx" SG_ 531 AccBrkActv_B_Actl 1;
BA_ "U_UP375_MY15_Diesel_Tx" SG_ 531 AccBrkActv_B_Actl 1;
BA_ "U_CD43_MY16_Gas_Tx" SG_ 531 AccBrkActv_B_Actl 1;
BA_ "CrossOver_InfoCAN" SG_ 531 PrplDrgCtlActv_B_Actl 1;
BA_ "U_CD4_MY13_Diesel_Tx" SG_ 531 PrplDrgCtlActv_B_Actl 1;
BA_ "U_CD4_MY13_Gas_Tx" SG_ 531 PrplDrgCtlActv_B_Actl 1;
BA_ "U_CD4_MY13_Hev_Tx" SG_ 531 PrplDrgCtlActv_B_Actl 1;
BA_ "U_CD4_MY13_Phev_Tx" SG_ 531 PrplDrgCtlActv_B_Actl 1;
BA_ "U_CD42_MY14_Diesel_Tx" SG_ 531 PrplDrgCtlActv_B_Actl 1;
BA_ "U_CD42_MY14_Gas_Tx" SG_ 531 PrplDrgCtlActv_B_Actl 1;
BA_ "U_P552_MY15_Gas_Tx" SG_ 531 PrplDrgCtlActv_B_Actl 1;
BA_ "U_S550_MY15_Gas_Tx" SG_ 531 PrplDrgCtlActv_B_Actl 1;
BA_ "U_C489_MY14_Gas_Tx" SG_ 531 PrplDrgCtlActv_B_Actl 1;
BA_ "U_B562LC_MY14_Diesel_Tx" SG_ 531 PrplDrgCtlActv_B_Actl 1;
BA_ "U_B562LC_MY14_Gas_Tx" SG_ 531 PrplDrgCtlActv_B_Actl 1;
BA_ "U_U502_MY15_Gas_Tx" SG_ 531 PrplDrgCtlActv_B_Actl 1;
BA_ "U_UP375_MY15_Gas_Tx" SG_ 531 PrplDrgCtlActv_B_Actl 1;
BA_ "U_UP375_MY15_Diesel_Tx" SG_ 531 PrplDrgCtlActv_B_Actl 1;
BA_ "U_CD43_MY16_Gas_Tx" SG_ 531 PrplDrgCtlActv_B_Actl 1;
BA_ "CrossOver_InfoCAN" SG_ 531 PrplWhlTot_Tq_RqMx 1;
BA_ "U_P552_MY15_Gas_Rx" SG_ 531 PrplWhlTot_Tq_RqMx 1;
BA_ "U_UP375_MY15_Gas_Rx" SG_ 531 PrplWhlTot_Tq_RqMx 1;
BA_ "U_UP375_MY15_Diesel_Rx" SG_ 531 PrplWhlTot_Tq_RqMx 1;
BA_ "U_CD4_MY13_Diesel_Tx" SG_ 531 PrplWhlTot_Tq_RqMx 1;
BA_ "U_CD4_MY13_Gas_Tx" SG_ 531 PrplWhlTot_Tq_RqMx 1;
BA_ "U_CD4_MY13_Hev_Tx" SG_ 531 PrplWhlTot_Tq_RqMx 1;
BA_ "U_CD4_MY13_Phev_Tx" SG_ 531 PrplWhlTot_Tq_RqMx 1;
BA_ "U_CD42_MY14_Diesel_Tx" SG_ 531 PrplWhlTot_Tq_RqMx 1;
BA_ "U_CD42_MY14_Gas_Tx" SG_ 531 PrplWhlTot_Tq_RqMx 1;
BA_ "U_P552_MY15_Gas_Tx" SG_ 531 PrplWhlTot_Tq_RqMx 1;
BA_ "U_S550_MY15_Gas_Tx" SG_ 531 PrplWhlTot_Tq_RqMx 1;
BA_ "U_C489_MY14_Gas_Tx" SG_ 531 PrplWhlTot_Tq_RqMx 1;
BA_ "U_B562LC_MY14_Diesel_Tx" SG_ 531 PrplWhlTot_Tq_RqMx 1;
BA_ "U_B562LC_MY14_Gas_Tx" SG_ 531 PrplWhlTot_Tq_RqMx 1;
BA_ "U_U502_MY15_Gas_Tx" SG_ 531 PrplWhlTot_Tq_RqMx 1;
BA_ "U_UP375_MY15_Gas_Tx" SG_ 531 PrplWhlTot_Tq_RqMx 1;
BA_ "U_UP375_MY15_Diesel_Tx" SG_ 531 PrplWhlTot_Tq_RqMx 1;
BA_ "U_CD43_MY16_Gas_Tx" SG_ 531 PrplWhlTot_Tq_RqMx 1;
BA_ "CrossOver_InfoCAN" SG_ 531 CmbbBrkDis_B_Actl 1;
BA_ "U_U502_MY15_Gas_Rx" SG_ 531 CmbbBrkDis_B_Actl 1;
BA_ "U_UP375_MY15_Gas_Rx" SG_ 531 CmbbBrkDis_B_Actl 1;
BA_ "U_UP375_MY15_Diesel_Rx" SG_ 531 CmbbBrkDis_B_Actl 1;
BA_ "U_CD43_MY16_Gas_Rx" SG_ 531 CmbbBrkDis_B_Actl 1;
BA_ "U_CD4_MY13_Diesel_Tx" SG_ 531 CmbbBrkDis_B_Actl 1;
BA_ "U_CD4_MY13_Gas_Tx" SG_ 531 CmbbBrkDis_B_Actl 1;
BA_ "U_CD4_MY13_Hev_Tx" SG_ 531 CmbbBrkDis_B_Actl 1;
BA_ "U_CD4_MY13_Phev_Tx" SG_ 531 CmbbBrkDis_B_Actl 1;
BA_ "U_CD42_MY14_Diesel_Tx" SG_ 531 CmbbBrkDis_B_Actl 1;
BA_ "U_CD42_MY14_Gas_Tx" SG_ 531 CmbbBrkDis_B_Actl 1;
BA_ "U_P552_MY15_Gas_Tx" SG_ 531 CmbbBrkDis_B_Actl 1;
BA_ "U_S550_MY15_Gas_Tx" SG_ 531 CmbbBrkDis_B_Actl 1;
BA_ "U_C489_MY14_Gas_Tx" SG_ 531 CmbbBrkDis_B_Actl 1;
BA_ "U_B562LC_MY14_Diesel_Tx" SG_ 531 CmbbBrkDis_B_Actl 1;
BA_ "U_B562LC_MY14_Gas_Tx" SG_ 531 CmbbBrkDis_B_Actl 1;
BA_ "U_U502_MY15_Gas_Tx" SG_ 531 CmbbBrkDis_B_Actl 1;
BA_ "U_UP375_MY15_Gas_Tx" SG_ 531 CmbbBrkDis_B_Actl 1;
BA_ "U_UP375_MY15_Diesel_Tx" SG_ 531 CmbbBrkDis_B_Actl 1;
BA_ "U_CD43_MY16_Gas_Tx" SG_ 531 CmbbBrkDis_B_Actl 1;
BA_ "CrossOver_InfoCAN" SG_ 531 CmbbDeny_B_ActlBrk 1;
BA_ "U_U502_MY15_Gas_Rx" SG_ 531 CmbbDeny_B_ActlBrk 1;
BA_ "U_UP375_MY15_Gas_Rx" SG_ 531 CmbbDeny_B_ActlBrk 1;
BA_ "U_UP375_MY15_Diesel_Rx" SG_ 531 CmbbDeny_B_ActlBrk 1;
BA_ "U_CD43_MY16_Gas_Rx" SG_ 531 CmbbDeny_B_ActlBrk 1;
BA_ "U_CD4_MY13_Diesel_Tx" SG_ 531 CmbbDeny_B_ActlBrk 1;
BA_ "U_CD4_MY13_Gas_Tx" SG_ 531 CmbbDeny_B_ActlBrk 1;
BA_ "U_CD4_MY13_Hev_Tx" SG_ 531 CmbbDeny_B_ActlBrk 1;
BA_ "U_CD4_MY13_Phev_Tx" SG_ 531 CmbbDeny_B_ActlBrk 1;
BA_ "U_CD42_MY14_Diesel_Tx" SG_ 531 CmbbDeny_B_ActlBrk 1;
BA_ "U_CD42_MY14_Gas_Tx" SG_ 531 CmbbDeny_B_ActlBrk 1;
BA_ "U_P552_MY15_Gas_Tx" SG_ 531 CmbbDeny_B_ActlBrk 1;
BA_ "U_S550_MY15_Gas_Tx" SG_ 531 CmbbDeny_B_ActlBrk 1;
BA_ "U_C489_MY14_Gas_Tx" SG_ 531 CmbbDeny_B_ActlBrk 1;
BA_ "U_B562LC_MY14_Diesel_Tx" SG_ 531 CmbbDeny_B_ActlBrk 1;
BA_ "U_B562LC_MY14_Gas_Tx" SG_ 531 CmbbDeny_B_ActlBrk 1;
BA_ "U_U502_MY15_Gas_Tx" SG_ 531 CmbbDeny_B_ActlBrk 1;
BA_ "U_UP375_MY15_Gas_Tx" SG_ 531 CmbbDeny_B_ActlBrk 1;
BA_ "U_UP375_MY15_Diesel_Tx" SG_ 531 CmbbDeny_B_ActlBrk 1;
BA_ "U_CD43_MY16_Gas_Tx" SG_ 531 CmbbDeny_B_ActlBrk 1;
BA_ "GenSigTimeoutTime_CCM" SG_ 531 CmbbDeny_B_ActlBrk 1000;
BA_ "CrossOver_InfoCAN" SG_ 531 CcDis_B_Cmd 1;
BA_ "U_CD4_MY13_Diesel_Tx" SG_ 531 CcDis_B_Cmd 1;
BA_ "U_CD4_MY13_Gas_Tx" SG_ 531 CcDis_B_Cmd 1;
BA_ "U_CD4_MY13_Hev_Tx" SG_ 531 CcDis_B_Cmd 1;
BA_ "U_CD4_MY13_Phev_Tx" SG_ 531 CcDis_B_Cmd 1;
BA_ "U_CD42_MY14_Diesel_Tx" SG_ 531 CcDis_B_Cmd 1;
BA_ "U_CD42_MY14_Gas_Tx" SG_ 531 CcDis_B_Cmd 1;
BA_ "U_P552_MY15_Gas_Tx" SG_ 531 CcDis_B_Cmd 1;
BA_ "U_S550_MY15_Gas_Tx" SG_ 531 CcDis_B_Cmd 1;
BA_ "U_C489_MY14_Gas_Tx" SG_ 531 CcDis_B_Cmd 1;
BA_ "U_B562LC_MY14_Diesel_Tx" SG_ 531 CcDis_B_Cmd 1;
BA_ "U_B562LC_MY14_Gas_Tx" SG_ 531 CcDis_B_Cmd 1;
BA_ "U_U502_MY15_Gas_Tx" SG_ 531 CcDis_B_Cmd 1;
BA_ "U_UP375_MY15_Gas_Tx" SG_ 531 CcDis_B_Cmd 1;
BA_ "U_UP375_MY15_Diesel_Tx" SG_ 531 CcDis_B_Cmd 1;
BA_ "U_CD43_MY16_Gas_Tx" SG_ 531 CcDis_B_Cmd 1;
BA_ "CrossOver_InfoCAN" SG_ 531 VehLongOvrGnd_A_Est 1;
BA_ "GenSigStartValue" SG_ 531 VehLongOvrGnd_A_Est 511;
BA_ "U_CD4_MY13_Phev_Rx" SG_ 531 VehLongOvrGnd_A_Est 1;
BA_ "U_CD42_MY14_Diesel_Rx" SG_ 531 VehLongOvrGnd_A_Est 1;
BA_ "U_CD42_MY14_Gas_Rx" SG_ 531 VehLongOvrGnd_A_Est 1;
BA_ "U_P552_MY15_Gas_Rx" SG_ 531 VehLongOvrGnd_A_Est 1;
BA_ "U_S550_MY15_Gas_Rx" SG_ 531 VehLongOvrGnd_A_Est 1;
BA_ "U_C489_MY14_Gas_Rx" SG_ 531 VehLongOvrGnd_A_Est 1;
BA_ "U_U502_MY15_Gas_Rx" SG_ 531 VehLongOvrGnd_A_Est 1;
BA_ "U_UP375_MY15_Gas_Rx" SG_ 531 VehLongOvrGnd_A_Est 1;
BA_ "U_UP375_MY15_Diesel_Rx" SG_ 531 VehLongOvrGnd_A_Est 1;
BA_ "U_CD43_MY16_Gas_Rx" SG_ 531 VehLongOvrGnd_A_Est 1;
BA_ "U_CD4_MY13_Diesel_Tx" SG_ 531 VehLongOvrGnd_A_Est 1;
BA_ "U_CD4_MY13_Gas_Tx" SG_ 531 VehLongOvrGnd_A_Est 1;
BA_ "U_CD4_MY13_Hev_Tx" SG_ 531 VehLongOvrGnd_A_Est 1;
BA_ "U_CD4_MY13_Phev_Tx" SG_ 531 VehLongOvrGnd_A_Est 1;
BA_ "U_CD42_MY14_Diesel_Tx" SG_ 531 VehLongOvrGnd_A_Est 1;
BA_ "U_CD42_MY14_Gas_Tx" SG_ 531 VehLongOvrGnd_A_Est 1;
BA_ "U_P552_MY15_Gas_Tx" SG_ 531 VehLongOvrGnd_A_Est 1;
BA_ "U_S550_MY15_Gas_Tx" SG_ 531 VehLongOvrGnd_A_Est 1;
BA_ "U_C489_MY14_Gas_Tx" SG_ 531 VehLongOvrGnd_A_Est 1;
BA_ "U_B562LC_MY14_Diesel_Tx" SG_ 531 VehLongOvrGnd_A_Est 1;
BA_ "U_B562LC_MY14_Gas_Tx" SG_ 531 VehLongOvrGnd_A_Est 1;
BA_ "U_U502_MY15_Gas_Tx" SG_ 531 VehLongOvrGnd_A_Est 1;
BA_ "U_UP375_MY15_Gas_Tx" SG_ 531 VehLongOvrGnd_A_Est 1;
BA_ "U_UP375_MY15_Diesel_Tx" SG_ 531 VehLongOvrGnd_A_Est 1;
BA_ "U_CD43_MY16_Gas_Tx" SG_ 531 VehLongOvrGnd_A_Est 1;
BA_ "GenSigTimeoutTime_CCM" SG_ 531 VehLongOvrGnd_A_Est 1000;
BA_ "GenSigStartValue" SG_ 531 PrkBrkStatus 7;
BA_ "CrossOver_InfoCAN" SG_ 531 PrkBrkStatus 1;
BA_ "U_CD4_MY13_Diesel_Tx" SG_ 531 PrkBrkStatus 1;
BA_ "U_CD4_MY13_Gas_Tx" SG_ 531 PrkBrkStatus 1;
BA_ "U_CD4_MY13_Hev_Tx" SG_ 531 PrkBrkStatus 1;
BA_ "U_CD4_MY13_Phev_Tx" SG_ 531 PrkBrkStatus 1;
BA_ "U_CD42_MY14_Diesel_Tx" SG_ 531 PrkBrkStatus 1;
BA_ "U_CD42_MY14_Gas_Tx" SG_ 531 PrkBrkStatus 1;
BA_ "U_P552_MY15_Gas_Tx" SG_ 531 PrkBrkStatus 1;
BA_ "U_C489_MY14_Gas_Tx" SG_ 531 PrkBrkStatus 1;
BA_ "U_B562LC_MY14_Diesel_Tx" SG_ 531 PrkBrkStatus 1;
BA_ "U_B562LC_MY14_Gas_Tx" SG_ 531 PrkBrkStatus 1;
BA_ "U_U502_MY15_Gas_Tx" SG_ 531 PrkBrkStatus 1;
BA_ "U_CD43_MY16_Gas_Tx" SG_ 531 PrkBrkStatus 1;
BA_ "CrossOver_InfoCAN" SG_ 2015 TesterFunctionalReq 1;
BA_ "GenSigSendType" SG_ 2015 TesterFunctionalReq 3;
BA_ "U_CD4_MY13_Diesel_Rx" SG_ 2015 TesterFunctionalReq 1;
BA_ "U_CD4_MY13_Gas_Rx" SG_ 2015 TesterFunctionalReq 1;
BA_ "U_CD4_MY13_Hev_Rx" SG_ 2015 TesterFunctionalReq 1;
BA_ "U_CD4_MY13_Phev_Rx" SG_ 2015 TesterFunctionalReq 1;
BA_ "U_P552_MY15_Gas_Rx" SG_ 2015 TesterFunctionalReq 1;
BA_ "U_CD42_MY14_Diesel_Rx" SG_ 2015 TesterFunctionalReq 1;
BA_ "U_CD42_MY14_Gas_Rx" SG_ 2015 TesterFunctionalReq 1;
BA_ "U_S550_MY15_Gas_Rx" SG_ 2015 TesterFunctionalReq 1;
BA_ "U_C489_MY14_Gas_Rx" SG_ 2015 TesterFunctionalReq 1;
BA_ "U_U502_MY15_Gas_Rx" SG_ 2015 TesterFunctionalReq 1;
BA_ "U_UP375_MY15_Gas_Rx" SG_ 2015 TesterFunctionalReq 1;
BA_ "U_UP375_MY15_Diesel_Rx" SG_ 2015 TesterFunctionalReq 1;
BA_ "U_CD43_MY16_Gas_Rx" SG_ 2015 TesterFunctionalReq 1;
BA_ "U_CD4_MY14_Diesel_Rx" SG_ 2015 TesterFunctionalReq 1;
BA_ "U_CD4_MY14_Gas_Rx" SG_ 2015 TesterFunctionalReq 1;
BA_ "U_CD4_MY14_Hev_Rx" SG_ 2015 TesterFunctionalReq 1;
BA_ "U_CD4_MY14_Phev_Rx" SG_ 2015 TesterFunctionalReq 1;
BA_ "GenSigTimeoutTime_OCS" SG_ 2015 TesterFunctionalReq 6000;
BA_ "U_S550_MY18_Gas_Rx" SG_ 2015 TesterFunctionalReq 1;
BA_ "U_U502_MY17_Gas_Rx" SG_ 2015 TesterFunctionalReq 1;
BA_ "U_U55x_MY18_Gas_Rx" SG_ 2015 TesterFunctionalReq 1;
BA_ "U_B515_MCA_MY17_Gas_Rx" SG_ 2015 TesterFunctionalReq 1;
BA_ "U_B515_MCA_MY17_Diesel_Rx" SG_ 2015 TesterFunctionalReq 1;
BA_ "U_P552_MY18_Gas_Rx" SG_ 2015 TesterFunctionalReq 1;
BA_ "U_P552_MY17_Gas_Rx" SG_ 2015 TesterFunctionalReq 1;
BA_ "U_CD43_MY17_Gas_Rx" SG_ 2015 TesterFunctionalReq 1;
BA_ "U_CD42_MY16_Gas_Rx" SG_ 2015 TesterFunctionalReq 1;
BA_ "U_CD42_MY16_Diesel_Rx" SG_ 2015 TesterFunctionalReq 1;
BA_ "U_C489_MY17_Gas_Rx" SG_ 2015 TesterFunctionalReq 1;
BA_ "U_V36X_MY16_5_Diesel_Rx" SG_ 2015 TesterFunctionalReq 1;
BA_ "U_P558_MY17_Diesel_Rx" SG_ 2015 TesterFunctionalReq 1;
BA_ "U_P558_MY17_Gas_Rx" SG_ 2015 TesterFunctionalReq 1;
BA_ "U_CD4_MY17_Phev_Rx" SG_ 2015 TesterFunctionalReq 1;
BA_ "U_CD4_MY17_Hev_Rx" SG_ 2015 TesterFunctionalReq 1;
BA_ "U_CD4_MY17_Gas_Rx" SG_ 2015 TesterFunctionalReq 1;
BA_ "U_CD4_MY17_Diesel_Rx" SG_ 2015 TesterFunctionalReq 1;
BA_ "U_B479_MY17_Diesel_Rx" SG_ 2015 TesterFunctionalReq 1;
BA_ "U_B479_MY17_Gas_Rx" SG_ 2015 TesterFunctionalReq 1;
BA_ "U_U502_MY16_Gas_Rx" SG_ 2015 TesterFunctionalReq 1;
BA_ "U_CD42_MY15_Gas_Rx" SG_ 2015 TesterFunctionalReq 1;
BA_ "U_CD42_MY15_Diesel_Rx" SG_ 2015 TesterFunctionalReq 1;
BA_ "GenSigStartValue" SG_ 125 VehRolComp_W_Actl 4094;
BA_ "U_CD4_MY13_Diesel_Tx" SG_ 125 VehRolComp_W_Actl 1;
BA_ "U_CD4_MY13_Gas_Tx" SG_ 125 VehRolComp_W_Actl 1;
BA_ "U_CD4_MY13_Hev_Tx" SG_ 125 VehRolComp_W_Actl 1;
BA_ "U_CD4_MY13_Phev_Tx" SG_ 125 VehRolComp_W_Actl 1;
BA_ "U_CD42_MY14_Diesel_Tx" SG_ 125 VehRolComp_W_Actl 1;
BA_ "U_CD42_MY14_Gas_Tx" SG_ 125 VehRolComp_W_Actl 1;
BA_ "U_P552_MY15_Gas_Tx" SG_ 125 VehRolComp_W_Actl 1;
BA_ "U_S550_MY15_Gas_Tx" SG_ 125 VehRolComp_W_Actl 1;
BA_ "U_C489_MY14_Gas_Tx" SG_ 125 VehRolComp_W_Actl 1;
BA_ "U_B562LC_MY14_Diesel_Tx" SG_ 125 VehRolComp_W_Actl 1;
BA_ "U_B562LC_MY14_Gas_Tx" SG_ 125 VehRolComp_W_Actl 1;
BA_ "U_U502_MY15_Gas_Tx" SG_ 125 VehRolComp_W_Actl 1;
BA_ "U_UP375_MY15_Gas_Tx" SG_ 125 VehRolComp_W_Actl 1;
BA_ "U_UP375_MY15_Diesel_Tx" SG_ 125 VehRolComp_W_Actl 1;
BA_ "U_CD43_MY16_Gas_Tx" SG_ 125 VehRolComp_W_Actl 1;
BA_ "GenSigStartValue" SG_ 125 VehVertComp_A_Actl 1022;
BA_ "U_CD4_MY13_Diesel_Tx" SG_ 125 VehVertComp_A_Actl 1;
BA_ "U_CD4_MY13_Gas_Tx" SG_ 125 VehVertComp_A_Actl 1;
BA_ "U_CD4_MY13_Hev_Tx" SG_ 125 VehVertComp_A_Actl 1;
BA_ "U_CD4_MY13_Phev_Tx" SG_ 125 VehVertComp_A_Actl 1;
BA_ "U_CD42_MY14_Diesel_Tx" SG_ 125 VehVertComp_A_Actl 1;
BA_ "U_CD42_MY14_Gas_Tx" SG_ 125 VehVertComp_A_Actl 1;
BA_ "U_P552_MY15_Gas_Tx" SG_ 125 VehVertComp_A_Actl 1;
BA_ "U_S550_MY15_Gas_Tx" SG_ 125 VehVertComp_A_Actl 1;
BA_ "U_C489_MY14_Gas_Tx" SG_ 125 VehVertComp_A_Actl 1;
BA_ "U_B562LC_MY14_Diesel_Tx" SG_ 125 VehVertComp_A_Actl 1;
BA_ "U_B562LC_MY14_Gas_Tx" SG_ 125 VehVertComp_A_Actl 1;
BA_ "U_U502_MY15_Gas_Tx" SG_ 125 VehVertComp_A_Actl 1;
BA_ "U_UP375_MY15_Gas_Tx" SG_ 125 VehVertComp_A_Actl 1;
BA_ "U_UP375_MY15_Diesel_Tx" SG_ 125 VehVertComp_A_Actl 1;
BA_ "U_CD43_MY16_Gas_Tx" SG_ 125 VehVertComp_A_Actl 1;
BA_ "U_P552_MY15_Gas_Rx" SG_ 125 BrkTotTqRqArb_No_Cs 1;
BA_ "U_CD4_MY13_Diesel_Tx" SG_ 125 BrkTotTqRqArb_No_Cs 1;
BA_ "U_CD4_MY13_Gas_Tx" SG_ 125 BrkTotTqRqArb_No_Cs 1;
BA_ "U_CD4_MY13_Hev_Tx" SG_ 125 BrkTotTqRqArb_No_Cs 1;
BA_ "U_CD4_MY13_Phev_Tx" SG_ 125 BrkTotTqRqArb_No_Cs 1;
BA_ "U_CD42_MY14_Diesel_Tx" SG_ 125 BrkTotTqRqArb_No_Cs 1;
BA_ "U_CD42_MY14_Gas_Tx" SG_ 125 BrkTotTqRqArb_No_Cs 1;
BA_ "U_P552_MY15_Gas_Tx" SG_ 125 BrkTotTqRqArb_No_Cs 1;
BA_ "U_S550_MY15_Gas_Tx" SG_ 125 BrkTotTqRqArb_No_Cs 1;
BA_ "U_C489_MY14_Gas_Tx" SG_ 125 BrkTotTqRqArb_No_Cs 1;
BA_ "U_B562LC_MY14_Diesel_Tx" SG_ 125 BrkTotTqRqArb_No_Cs 1;
BA_ "U_B562LC_MY14_Gas_Tx" SG_ 125 BrkTotTqRqArb_No_Cs 1;
BA_ "U_U502_MY15_Gas_Tx" SG_ 125 BrkTotTqRqArb_No_Cs 1;
BA_ "U_UP375_MY15_Gas_Tx" SG_ 125 BrkTotTqRqArb_No_Cs 1;
BA_ "U_UP375_MY15_Diesel_Tx" SG_ 125 BrkTotTqRqArb_No_Cs 1;
BA_ "U_CD43_MY16_Gas_Tx" SG_ 125 BrkTotTqRqArb_No_Cs 1;
BA_ "U_P552_MY15_Gas_Rx" SG_ 125 BrkTotTqRqArb_No_Cnt 1;
BA_ "U_CD4_MY13_Diesel_Tx" SG_ 125 BrkTotTqRqArb_No_Cnt 1;
BA_ "U_CD4_MY13_Gas_Tx" SG_ 125 BrkTotTqRqArb_No_Cnt 1;
BA_ "U_CD4_MY13_Hev_Tx" SG_ 125 BrkTotTqRqArb_No_Cnt 1;
BA_ "U_CD4_MY13_Phev_Tx" SG_ 125 BrkTotTqRqArb_No_Cnt 1;
BA_ "U_CD42_MY14_Diesel_Tx" SG_ 125 BrkTotTqRqArb_No_Cnt 1;
BA_ "U_CD42_MY14_Gas_Tx" SG_ 125 BrkTotTqRqArb_No_Cnt 1;
BA_ "U_P552_MY15_Gas_Tx" SG_ 125 BrkTotTqRqArb_No_Cnt 1;
BA_ "U_S550_MY15_Gas_Tx" SG_ 125 BrkTotTqRqArb_No_Cnt 1;
BA_ "U_C489_MY14_Gas_Tx" SG_ 125 BrkTotTqRqArb_No_Cnt 1;
BA_ "U_B562LC_MY14_Diesel_Tx" SG_ 125 BrkTotTqRqArb_No_Cnt 1;
BA_ "U_B562LC_MY14_Gas_Tx" SG_ 125 BrkTotTqRqArb_No_Cnt 1;
BA_ "U_U502_MY15_Gas_Tx" SG_ 125 BrkTotTqRqArb_No_Cnt 1;
BA_ "U_UP375_MY15_Gas_Tx" SG_ 125 BrkTotTqRqArb_No_Cnt 1;
BA_ "U_UP375_MY15_Diesel_Tx" SG_ 125 BrkTotTqRqArb_No_Cnt 1;
BA_ "U_CD43_MY16_Gas_Tx" SG_ 125 BrkTotTqRqArb_No_Cnt 1;
BA_ "U_P552_MY15_Gas_Rx" SG_ 125 BrkTot_Tq_RqArb 1;
BA_ "U_U502_MY15_Gas_Rx" SG_ 125 BrkTot_Tq_RqArb 1;
BA_ "U_UP375_MY15_Gas_Rx" SG_ 125 BrkTot_Tq_RqArb 1;
BA_ "U_UP375_MY15_Diesel_Rx" SG_ 125 BrkTot_Tq_RqArb 1;
BA_ "U_CD43_MY16_Gas_Rx" SG_ 125 BrkTot_Tq_RqArb 1;
BA_ "U_CD4_MY13_Diesel_Tx" SG_ 125 BrkTot_Tq_RqArb 1;
BA_ "U_CD4_MY13_Gas_Tx" SG_ 125 BrkTot_Tq_RqArb 1;
BA_ "U_CD4_MY13_Hev_Tx" SG_ 125 BrkTot_Tq_RqArb 1;
BA_ "U_CD4_MY13_Phev_Tx" SG_ 125 BrkTot_Tq_RqArb 1;
BA_ "U_CD42_MY14_Diesel_Tx" SG_ 125 BrkTot_Tq_RqArb 1;
BA_ "U_CD42_MY14_Gas_Tx" SG_ 125 BrkTot_Tq_RqArb 1;
BA_ "U_P552_MY15_Gas_Tx" SG_ 125 BrkTot_Tq_RqArb 1;
BA_ "U_S550_MY15_Gas_Tx" SG_ 125 BrkTot_Tq_RqArb 1;
BA_ "U_C489_MY14_Gas_Tx" SG_ 125 BrkTot_Tq_RqArb 1;
BA_ "U_B562LC_MY14_Diesel_Tx" SG_ 125 BrkTot_Tq_RqArb 1;
BA_ "U_B562LC_MY14_Gas_Tx" SG_ 125 BrkTot_Tq_RqArb 1;
BA_ "U_U502_MY15_Gas_Tx" SG_ 125 BrkTot_Tq_RqArb 1;
BA_ "U_UP375_MY15_Gas_Tx" SG_ 125 BrkTot_Tq_RqArb 1;
BA_ "U_UP375_MY15_Diesel_Tx" SG_ 125 BrkTot_Tq_RqArb 1;
BA_ "U_CD43_MY16_Gas_Tx" SG_ 125 BrkTot_Tq_RqArb 1;
BA_ "U_CD4_MY13_Diesel_Tx" SG_ 125 BrkTot_Tq_Actl 1;
BA_ "U_CD4_MY13_Gas_Tx" SG_ 125 BrkTot_Tq_Actl 1;
BA_ "U_CD4_MY13_Hev_Tx" SG_ 125 BrkTot_Tq_Actl 1;
BA_ "U_CD4_MY13_Phev_Tx" SG_ 125 BrkTot_Tq_Actl 1;
BA_ "U_CD42_MY14_Diesel_Tx" SG_ 125 BrkTot_Tq_Actl 1;
BA_ "U_CD42_MY14_Gas_Tx" SG_ 125 BrkTot_Tq_Actl 1;
BA_ "U_P552_MY15_Gas_Tx" SG_ 125 BrkTot_Tq_Actl 1;
BA_ "U_S550_MY15_Gas_Tx" SG_ 125 BrkTot_Tq_Actl 1;
BA_ "U_C489_MY14_Gas_Tx" SG_ 125 BrkTot_Tq_Actl 1;
BA_ "U_B562LC_MY14_Diesel_Tx" SG_ 125 BrkTot_Tq_Actl 1;
BA_ "U_B562LC_MY14_Gas_Tx" SG_ 125 BrkTot_Tq_Actl 1;
BA_ "U_U502_MY15_Gas_Tx" SG_ 125 BrkTot_Tq_Actl 1;
BA_ "U_UP375_MY15_Gas_Tx" SG_ 125 BrkTot_Tq_Actl 1;
BA_ "U_UP375_MY15_Diesel_Tx" SG_ 125 BrkTot_Tq_Actl 1;
BA_ "U_CD43_MY16_Gas_Tx" SG_ 125 BrkTot_Tq_Actl 1;
BA_ "CrossOver_InfoCAN" SG_ 125 HsaStat_D_Actl 1;
BA_ "U_CD4_MY13_Diesel_Tx" SG_ 125 HsaStat_D_Actl 1;
BA_ "U_CD4_MY13_Gas_Tx" SG_ 125 HsaStat_D_Actl 1;
BA_ "U_CD4_MY13_Hev_Tx" SG_ 125 HsaStat_D_Actl 1;
BA_ "U_CD4_MY13_Phev_Tx" SG_ 125 HsaStat_D_Actl 1;
BA_ "U_CD42_MY14_Diesel_Tx" SG_ 125 HsaStat_D_Actl 1;
BA_ "U_CD42_MY14_Gas_Tx" SG_ 125 HsaStat_D_Actl 1;
BA_ "U_P552_MY15_Gas_Tx" SG_ 125 HsaStat_D_Actl 1;
BA_ "U_S550_MY15_Gas_Tx" SG_ 125 HsaStat_D_Actl 1;
BA_ "U_C489_MY14_Gas_Tx" SG_ 125 HsaStat_D_Actl 1;
BA_ "U_B562LC_MY14_Diesel_Tx" SG_ 125 HsaStat_D_Actl 1;
BA_ "U_B562LC_MY14_Gas_Tx" SG_ 125 HsaStat_D_Actl 1;
BA_ "U_U502_MY15_Gas_Tx" SG_ 125 HsaStat_D_Actl 1;
BA_ "U_UP375_MY15_Gas_Tx" SG_ 125 HsaStat_D_Actl 1;
BA_ "U_UP375_MY15_Diesel_Tx" SG_ 125 HsaStat_D_Actl 1;
BA_ "U_CD43_MY16_Gas_Tx" SG_ 125 HsaStat_D_Actl 1;
BA_ "U_CD4_MY13_Diesel_Rx" SG_ 119 VehOverGnd_V_Est 1;
BA_ "U_CD4_MY13_Gas_Rx" SG_ 119 VehOverGnd_V_Est 1;
BA_ "U_CD4_MY13_Hev_Rx" SG_ 119 VehOverGnd_V_Est 1;
BA_ "U_CD4_MY13_Phev_Rx" SG_ 119 VehOverGnd_V_Est 1;
BA_ "U_CD42_MY14_Diesel_Rx" SG_ 119 VehOverGnd_V_Est 1;
BA_ "U_CD42_MY14_Gas_Rx" SG_ 119 VehOverGnd_V_Est 1;
BA_ "U_P552_MY15_Gas_Rx" SG_ 119 VehOverGnd_V_Est 1;
BA_ "U_S550_MY15_Gas_Rx" SG_ 119 VehOverGnd_V_Est 1;
BA_ "U_C489_MY14_Gas_Rx" SG_ 119 VehOverGnd_V_Est 1;
BA_ "U_U502_MY15_Gas_Rx" SG_ 119 VehOverGnd_V_Est 1;
BA_ "U_UP375_MY15_Gas_Rx" SG_ 119 VehOverGnd_V_Est 1;
BA_ "U_UP375_MY15_Diesel_Rx" SG_ 119 VehOverGnd_V_Est 1;
BA_ "U_CD43_MY16_Gas_Rx" SG_ 119 VehOverGnd_V_Est 1;
BA_ "U_CD4_MY13_Diesel_Tx" SG_ 119 VehOverGnd_V_Est 1;
BA_ "U_CD4_MY13_Gas_Tx" SG_ 119 VehOverGnd_V_Est 1;
BA_ "U_CD4_MY13_Hev_Tx" SG_ 119 VehOverGnd_V_Est 1;
BA_ "U_CD4_MY13_Phev_Tx" SG_ 119 VehOverGnd_V_Est 1;
BA_ "U_CD42_MY14_Diesel_Tx" SG_ 119 VehOverGnd_V_Est 1;
BA_ "U_CD42_MY14_Gas_Tx" SG_ 119 VehOverGnd_V_Est 1;
BA_ "U_P552_MY15_Gas_Tx" SG_ 119 VehOverGnd_V_Est 1;
BA_ "U_S550_MY15_Gas_Tx" SG_ 119 VehOverGnd_V_Est 1;
BA_ "U_C489_MY14_Gas_Tx" SG_ 119 VehOverGnd_V_Est 1;
BA_ "U_B562LC_MY14_Diesel_Tx" SG_ 119 VehOverGnd_V_Est 1;
BA_ "U_B562LC_MY14_Gas_Tx" SG_ 119 VehOverGnd_V_Est 1;
BA_ "U_U502_MY15_Gas_Tx" SG_ 119 VehOverGnd_V_Est 1;
BA_ "U_UP375_MY15_Gas_Tx" SG_ 119 VehOverGnd_V_Est 1;
BA_ "U_UP375_MY15_Diesel_Tx" SG_ 119 VehOverGnd_V_Est 1;
BA_ "U_CD43_MY16_Gas_Tx" SG_ 119 VehOverGnd_V_Est 1;
BA_ "GenSigTimeoutTime_CCM" SG_ 119 VehOverGnd_V_Est 1000;
BA_ "GenSigStartValue" SG_ 119 VehLongComp_A_Actl 1022;
BA_ "U_P552_MY15_Gas_Rx" SG_ 119 VehLongComp_A_Actl 1;
BA_ "U_CD4_MY13_Diesel_Tx" SG_ 119 VehLongComp_A_Actl 1;
BA_ "U_CD4_MY13_Gas_Tx" SG_ 119 VehLongComp_A_Actl 1;
BA_ "U_CD4_MY13_Hev_Tx" SG_ 119 VehLongComp_A_Actl 1;
BA_ "U_CD4_MY13_Phev_Tx" SG_ 119 VehLongComp_A_Actl 1;
BA_ "U_CD42_MY14_Diesel_Tx" SG_ 119 VehLongComp_A_Actl 1;
BA_ "U_CD42_MY14_Gas_Tx" SG_ 119 VehLongComp_A_Actl 1;
BA_ "U_P552_MY15_Gas_Tx" SG_ 119 VehLongComp_A_Actl 1;
BA_ "U_S550_MY15_Gas_Tx" SG_ 119 VehLongComp_A_Actl 1;
BA_ "U_C489_MY14_Gas_Tx" SG_ 119 VehLongComp_A_Actl 1;
BA_ "U_B562LC_MY14_Diesel_Tx" SG_ 119 VehLongComp_A_Actl 1;
BA_ "U_B562LC_MY14_Gas_Tx" SG_ 119 VehLongComp_A_Actl 1;
BA_ "U_U502_MY15_Gas_Tx" SG_ 119 VehLongComp_A_Actl 1;
BA_ "U_UP375_MY15_Gas_Tx" SG_ 119 VehLongComp_A_Actl 1;
BA_ "U_UP375_MY15_Diesel_Tx" SG_ 119 VehLongComp_A_Actl 1;
BA_ "U_CD43_MY16_Gas_Tx" SG_ 119 VehLongComp_A_Actl 1;
BA_ "GenSigStartValue" SG_ 119 VehLatComp_A_Actl 1022;
BA_ "U_CD4_MY13_Diesel_Rx" SG_ 119 VehLatComp_A_Actl 1;
BA_ "U_CD4_MY13_Gas_Rx" SG_ 119 VehLatComp_A_Actl 1;
BA_ "U_CD4_MY13_Hev_Rx" SG_ 119 VehLatComp_A_Actl 1;
BA_ "U_CD4_MY13_Phev_Rx" SG_ 119 VehLatComp_A_Actl 1;
BA_ "U_CD42_MY14_Diesel_Rx" SG_ 119 VehLatComp_A_Actl 1;
BA_ "U_CD42_MY14_Gas_Rx" SG_ 119 VehLatComp_A_Actl 1;
BA_ "U_P552_MY15_Gas_Rx" SG_ 119 VehLatComp_A_Actl 1;
BA_ "U_S550_MY15_Gas_Rx" SG_ 119 VehLatComp_A_Actl 1;
BA_ "U_C489_MY14_Gas_Rx" SG_ 119 VehLatComp_A_Actl 1;
BA_ "U_U502_MY15_Gas_Rx" SG_ 119 VehLatComp_A_Actl 1;
BA_ "U_UP375_MY15_Gas_Rx" SG_ 119 VehLatComp_A_Actl 1;
BA_ "U_UP375_MY15_Diesel_Rx" SG_ 119 VehLatComp_A_Actl 1;
BA_ "U_CD43_MY16_Gas_Rx" SG_ 119 VehLatComp_A_Actl 1;
BA_ "U_CD4_MY13_Diesel_Tx" SG_ 119 VehLatComp_A_Actl 1;
BA_ "U_CD4_MY13_Gas_Tx" SG_ 119 VehLatComp_A_Actl 1;
BA_ "U_CD4_MY13_Hev_Tx" SG_ 119 VehLatComp_A_Actl 1;
BA_ "U_CD4_MY13_Phev_Tx" SG_ 119 VehLatComp_A_Actl 1;
BA_ "U_CD42_MY14_Diesel_Tx" SG_ 119 VehLatComp_A_Actl 1;
BA_ "U_CD42_MY14_Gas_Tx" SG_ 119 VehLatComp_A_Actl 1;
BA_ "U_P552_MY15_Gas_Tx" SG_ 119 VehLatComp_A_Actl 1;
BA_ "U_S550_MY15_Gas_Tx" SG_ 119 VehLatComp_A_Actl 1;
BA_ "U_C489_MY14_Gas_Tx" SG_ 119 VehLatComp_A_Actl 1;
BA_ "U_B562LC_MY14_Diesel_Tx" SG_ 119 VehLatComp_A_Actl 1;
BA_ "U_B562LC_MY14_Gas_Tx" SG_ 119 VehLatComp_A_Actl 1;
BA_ "U_U502_MY15_Gas_Tx" SG_ 119 VehLatComp_A_Actl 1;
BA_ "U_UP375_MY15_Gas_Tx" SG_ 119 VehLatComp_A_Actl 1;
BA_ "U_UP375_MY15_Diesel_Tx" SG_ 119 VehLatComp_A_Actl 1;
BA_ "U_CD43_MY16_Gas_Tx" SG_ 119 VehLatComp_A_Actl 1;
BA_ "CrossOver_InfoCAN" SG_ 119 VehYawComp_W_Actl 1;
BA_ "GenSigStartValue" SG_ 119 VehYawComp_W_Actl 4094;
BA_ "U_CD4_MY13_Diesel_Rx" SG_ 119 VehYawComp_W_Actl 1;
BA_ "U_CD4_MY13_Gas_Rx" SG_ 119 VehYawComp_W_Actl 1;
BA_ "U_CD4_MY13_Hev_Rx" SG_ 119 VehYawComp_W_Actl 1;
BA_ "U_CD4_MY13_Phev_Rx" SG_ 119 VehYawComp_W_Actl 1;
BA_ "U_CD42_MY14_Diesel_Rx" SG_ 119 VehYawComp_W_Actl 1;
BA_ "U_CD42_MY14_Gas_Rx" SG_ 119 VehYawComp_W_Actl 1;
BA_ "U_P552_MY15_Gas_Rx" SG_ 119 VehYawComp_W_Actl 1;
BA_ "U_S550_MY15_Gas_Rx" SG_ 119 VehYawComp_W_Actl 1;
BA_ "U_C489_MY14_Gas_Rx" SG_ 119 VehYawComp_W_Actl 1;
BA_ "U_U502_MY15_Gas_Rx" SG_ 119 VehYawComp_W_Actl 1;
BA_ "U_UP375_MY15_Gas_Rx" SG_ 119 VehYawComp_W_Actl 1;
BA_ "U_UP375_MY15_Diesel_Rx" SG_ 119 VehYawComp_W_Actl 1;
BA_ "U_CD43_MY16_Gas_Rx" SG_ 119 VehYawComp_W_Actl 1;
BA_ "U_CD4_MY13_Diesel_Tx" SG_ 119 VehYawComp_W_Actl 1;
BA_ "U_CD4_MY13_Gas_Tx" SG_ 119 VehYawComp_W_Actl 1;
BA_ "U_CD4_MY13_Hev_Tx" SG_ 119 VehYawComp_W_Actl 1;
BA_ "U_CD4_MY13_Phev_Tx" SG_ 119 VehYawComp_W_Actl 1;
BA_ "U_CD42_MY14_Diesel_Tx" SG_ 119 VehYawComp_W_Actl 1;
BA_ "U_CD42_MY14_Gas_Tx" SG_ 119 VehYawComp_W_Actl 1;
BA_ "U_P552_MY15_Gas_Tx" SG_ 119 VehYawComp_W_Actl 1;
BA_ "U_S550_MY15_Gas_Tx" SG_ 119 VehYawComp_W_Actl 1;
BA_ "U_C489_MY14_Gas_Tx" SG_ 119 VehYawComp_W_Actl 1;
BA_ "U_B562LC_MY14_Diesel_Tx" SG_ 119 VehYawComp_W_Actl 1;
BA_ "U_B562LC_MY14_Gas_Tx" SG_ 119 VehYawComp_W_Actl 1;
BA_ "U_U502_MY15_Gas_Tx" SG_ 119 VehYawComp_W_Actl 1;
BA_ "U_UP375_MY15_Gas_Tx" SG_ 119 VehYawComp_W_Actl 1;
BA_ "U_UP375_MY15_Diesel_Tx" SG_ 119 VehYawComp_W_Actl 1;
BA_ "U_CD43_MY16_Gas_Tx" SG_ 119 VehYawComp_W_Actl 1;
BA_ "GenSigTimeoutTime_CCM" SG_ 119 VehYawComp_W_Actl 1000;
BA_ "U_P552_MY15_Gas_Rx" SG_ 118 BrkCtrFnd_B_Stat 1;
BA_ "U_S550_MY15_Gas_Rx" SG_ 118 BrkCtrFnd_B_Stat 1;
BA_ "U_P552_MY15_Gas_Tx" SG_ 118 BrkCtrFnd_B_Stat 1;
BA_ "U_S550_MY15_Gas_Tx" SG_ 118 BrkCtrFnd_B_Stat 1;
BA_ "U_CD4_MY13_Diesel_Tx" SG_ 118 EmgcyBrkLamp_D_Rq 1;
BA_ "U_CD4_MY13_Gas_Tx" SG_ 118 EmgcyBrkLamp_D_Rq 1;
BA_ "U_CD4_MY13_Hev_Tx" SG_ 118 EmgcyBrkLamp_D_Rq 1;
BA_ "U_CD4_MY13_Phev_Tx" SG_ 118 EmgcyBrkLamp_D_Rq 1;
BA_ "U_CD42_MY14_Diesel_Tx" SG_ 118 EmgcyBrkLamp_D_Rq 1;
BA_ "U_CD42_MY14_Gas_Tx" SG_ 118 EmgcyBrkLamp_D_Rq 1;
BA_ "U_P552_MY15_Gas_Tx" SG_ 118 EmgcyBrkLamp_D_Rq 1;
BA_ "U_S550_MY15_Gas_Tx" SG_ 118 EmgcyBrkLamp_D_Rq 1;
BA_ "U_C489_MY14_Gas_Tx" SG_ 118 EmgcyBrkLamp_D_Rq 1;
BA_ "U_B562LC_MY14_Diesel_Tx" SG_ 118 EmgcyBrkLamp_D_Rq 1;
BA_ "U_B562LC_MY14_Gas_Tx" SG_ 118 EmgcyBrkLamp_D_Rq 1;
BA_ "U_U502_MY15_Gas_Tx" SG_ 118 EmgcyBrkLamp_D_Rq 1;
BA_ "U_CD43_MY16_Gas_Tx" SG_ 118 EmgcyBrkLamp_D_Rq 1;
BA_ "U_P552_MY15_Gas_Rx" SG_ 118 AwdLck_Tq_RqMx 1;
BA_ "U_UP375_MY15_Gas_Rx" SG_ 118 AwdLck_Tq_RqMx 1;
BA_ "U_UP375_MY15_Diesel_Rx" SG_ 118 AwdLck_Tq_RqMx 1;
BA_ "U_CD4_MY13_Diesel_Tx" SG_ 118 AwdLck_Tq_RqMx 1;
BA_ "U_CD4_MY13_Gas_Tx" SG_ 118 AwdLck_Tq_RqMx 1;
BA_ "U_CD42_MY14_Diesel_Tx" SG_ 118 AwdLck_Tq_RqMx 1;
BA_ "U_CD42_MY14_Gas_Tx" SG_ 118 AwdLck_Tq_RqMx 1;
BA_ "U_P552_MY15_Gas_Tx" SG_ 118 AwdLck_Tq_RqMx 1;
BA_ "U_C489_MY14_Gas_Tx" SG_ 118 AwdLck_Tq_RqMx 1;
BA_ "U_B562LC_MY14_Diesel_Tx" SG_ 118 AwdLck_Tq_RqMx 1;
BA_ "U_B562LC_MY14_Gas_Tx" SG_ 118 AwdLck_Tq_RqMx 1;
BA_ "U_U502_MY15_Gas_Tx" SG_ 118 AwdLck_Tq_RqMx 1;
BA_ "U_UP375_MY15_Gas_Tx" SG_ 118 AwdLck_Tq_RqMx 1;
BA_ "U_UP375_MY15_Diesel_Tx" SG_ 118 AwdLck_Tq_RqMx 1;
BA_ "U_CD43_MY16_Gas_Tx" SG_ 118 AwdLck_Tq_RqMx 1;
BA_ "U_P552_MY15_Gas_Rx" SG_ 118 AwdLck_Tq_RqMn 1;
BA_ "U_UP375_MY15_Gas_Rx" SG_ 118 AwdLck_Tq_RqMn 1;
BA_ "U_UP375_MY15_Diesel_Rx" SG_ 118 AwdLck_Tq_RqMn 1;
BA_ "U_CD4_MY13_Diesel_Tx" SG_ 118 AwdLck_Tq_RqMn 1;
BA_ "U_CD4_MY13_Gas_Tx" SG_ 118 AwdLck_Tq_RqMn 1;
BA_ "U_CD42_MY14_Diesel_Tx" SG_ 118 AwdLck_Tq_RqMn 1;
BA_ "U_CD42_MY14_Gas_Tx" SG_ 118 AwdLck_Tq_RqMn 1;
BA_ "U_P552_MY15_Gas_Tx" SG_ 118 AwdLck_Tq_RqMn 1;
BA_ "U_C489_MY14_Gas_Tx" SG_ 118 AwdLck_Tq_RqMn 1;
BA_ "U_B562LC_MY14_Diesel_Tx" SG_ 118 AwdLck_Tq_RqMn 1;
BA_ "U_B562LC_MY14_Gas_Tx" SG_ 118 AwdLck_Tq_RqMn 1;
BA_ "U_U502_MY15_Gas_Tx" SG_ 118 AwdLck_Tq_RqMn 1;
BA_ "U_UP375_MY15_Gas_Tx" SG_ 118 AwdLck_Tq_RqMn 1;
BA_ "U_UP375_MY15_Diesel_Tx" SG_ 118 AwdLck_Tq_RqMn 1;
BA_ "U_CD43_MY16_Gas_Tx" SG_ 118 AwdLck_Tq_RqMn 1;
BA_ "U_CD4_MY13_Diesel_Rx" SG_ 118 SteWhlComp_An_Est 1;
BA_ "U_CD4_MY13_Gas_Rx" SG_ 118 SteWhlComp_An_Est 1;
BA_ "U_CD4_MY13_Hev_Rx" SG_ 118 SteWhlComp_An_Est 1;
BA_ "U_CD4_MY13_Phev_Rx" SG_ 118 SteWhlComp_An_Est 1;
BA_ "U_CD42_MY14_Diesel_Rx" SG_ 118 SteWhlComp_An_Est 1;
BA_ "U_CD42_MY14_Gas_Rx" SG_ 118 SteWhlComp_An_Est 1;
BA_ "U_P552_MY15_Gas_Rx" SG_ 118 SteWhlComp_An_Est 1;
BA_ "U_S550_MY15_Gas_Rx" SG_ 118 SteWhlComp_An_Est 1;
BA_ "U_C489_MY14_Gas_Rx" SG_ 118 SteWhlComp_An_Est 1;
BA_ "U_U502_MY15_Gas_Rx" SG_ 118 SteWhlComp_An_Est 1;
BA_ "U_UP375_MY15_Gas_Rx" SG_ 118 SteWhlComp_An_Est 1;
BA_ "U_UP375_MY15_Diesel_Rx" SG_ 118 SteWhlComp_An_Est 1;
BA_ "U_CD43_MY16_Gas_Rx" SG_ 118 SteWhlComp_An_Est 1;
BA_ "U_CD4_MY14_Diesel_Rx" SG_ 118 SteWhlComp_An_Est 1;
BA_ "U_CD4_MY14_Gas_Rx" SG_ 118 SteWhlComp_An_Est 1;
BA_ "U_CD4_MY14_Hev_Rx" SG_ 118 SteWhlComp_An_Est 1;
BA_ "U_CD4_MY14_Phev_Rx" SG_ 118 SteWhlComp_An_Est 1;
BA_ "U_CD4_MY13_Diesel_Tx" SG_ 118 SteWhlComp_An_Est 1;
BA_ "U_CD4_MY13_Gas_Tx" SG_ 118 SteWhlComp_An_Est 1;
BA_ "U_CD4_MY13_Hev_Tx" SG_ 118 SteWhlComp_An_Est 1;
BA_ "U_CD4_MY13_Phev_Tx" SG_ 118 SteWhlComp_An_Est 1;
BA_ "U_CD42_MY14_Diesel_Tx" SG_ 118 SteWhlComp_An_Est 1;
BA_ "U_CD42_MY14_Gas_Tx" SG_ 118 SteWhlComp_An_Est 1;
BA_ "U_P552_MY15_Gas_Tx" SG_ 118 SteWhlComp_An_Est 1;
BA_ "U_S550_MY15_Gas_Tx" SG_ 118 SteWhlComp_An_Est 1;
BA_ "U_C489_MY14_Gas_Tx" SG_ 118 SteWhlComp_An_Est 1;
BA_ "U_B562LC_MY14_Diesel_Tx" SG_ 118 SteWhlComp_An_Est 1;
BA_ "U_B562LC_MY14_Gas_Tx" SG_ 118 SteWhlComp_An_Est 1;
BA_ "U_U502_MY15_Gas_Tx" SG_ 118 SteWhlComp_An_Est 1;
BA_ "U_UP375_MY15_Gas_Tx" SG_ 118 SteWhlComp_An_Est 1;
BA_ "U_UP375_MY15_Diesel_Tx" SG_ 118 SteWhlComp_An_Est 1;
BA_ "U_CD43_MY16_Gas_Tx" SG_ 118 SteWhlComp_An_Est 1;
BA_ "U_CD4_MY13_Diesel_Tx" SG_ 118 StopLamp_B_RqBrk 1;
BA_ "U_CD4_MY13_Gas_Tx" SG_ 118 StopLamp_B_RqBrk 1;
BA_ "U_CD4_MY13_Hev_Tx" SG_ 118 StopLamp_B_RqBrk 1;
BA_ "U_CD4_MY13_Phev_Tx" SG_ 118 StopLamp_B_RqBrk 1;
BA_ "U_CD42_MY14_Diesel_Tx" SG_ 118 StopLamp_B_RqBrk 1;
BA_ "U_CD42_MY14_Gas_Tx" SG_ 118 StopLamp_B_RqBrk 1;
BA_ "U_P552_MY15_Gas_Tx" SG_ 118 StopLamp_B_RqBrk 1;
BA_ "U_S550_MY15_Gas_Tx" SG_ 118 StopLamp_B_RqBrk 1;
BA_ "U_C489_MY14_Gas_Tx" SG_ 118 StopLamp_B_RqBrk 1;
BA_ "U_B562LC_MY14_Diesel_Tx" SG_ 118 StopLamp_B_RqBrk 1;
BA_ "U_B562LC_MY14_Gas_Tx" SG_ 118 StopLamp_B_RqBrk 1;
BA_ "U_U502_MY15_Gas_Tx" SG_ 118 StopLamp_B_RqBrk 1;
BA_ "U_UP375_MY15_Gas_Tx" SG_ 118 StopLamp_B_RqBrk 1;
BA_ "U_UP375_MY15_Diesel_Tx" SG_ 118 StopLamp_B_RqBrk 1;
BA_ "U_CD43_MY16_Gas_Tx" SG_ 118 StopLamp_B_RqBrk 1;
BA_ "U_CD4_MY13_Diesel_Rx" SG_ 118 SteWhlCompAnEst_D_Qf 1;
BA_ "U_CD4_MY13_Gas_Rx" SG_ 118 SteWhlCompAnEst_D_Qf 1;
BA_ "U_CD4_MY13_Hev_Rx" SG_ 118 SteWhlCompAnEst_D_Qf 1;
BA_ "U_CD4_MY13_Phev_Rx" SG_ 118 SteWhlCompAnEst_D_Qf 1;
BA_ "U_CD42_MY14_Diesel_Rx" SG_ 118 SteWhlCompAnEst_D_Qf 1;
BA_ "U_CD42_MY14_Gas_Rx" SG_ 118 SteWhlCompAnEst_D_Qf 1;
BA_ "U_P552_MY15_Gas_Rx" SG_ 118 SteWhlCompAnEst_D_Qf 1;
BA_ "U_S550_MY15_Gas_Rx" SG_ 118 SteWhlCompAnEst_D_Qf 1;
BA_ "U_C489_MY14_Gas_Rx" SG_ 118 SteWhlCompAnEst_D_Qf 1;
BA_ "U_U502_MY15_Gas_Rx" SG_ 118 SteWhlCompAnEst_D_Qf 1;
BA_ "U_UP375_MY15_Gas_Rx" SG_ 118 SteWhlCompAnEst_D_Qf 1;
BA_ "U_UP375_MY15_Diesel_Rx" SG_ 118 SteWhlCompAnEst_D_Qf 1;
BA_ "U_CD43_MY16_Gas_Rx" SG_ 118 SteWhlCompAnEst_D_Qf 1;
BA_ "U_CD4_MY14_Diesel_Rx" SG_ 118 SteWhlCompAnEst_D_Qf 1;
BA_ "U_CD4_MY14_Gas_Rx" SG_ 118 SteWhlCompAnEst_D_Qf 1;
BA_ "U_CD4_MY14_Hev_Rx" SG_ 118 SteWhlCompAnEst_D_Qf 1;
BA_ "U_CD4_MY14_Phev_Rx" SG_ 118 SteWhlCompAnEst_D_Qf 1;
BA_ "U_CD4_MY13_Diesel_Tx" SG_ 118 SteWhlCompAnEst_D_Qf 1;
BA_ "U_CD4_MY13_Gas_Tx" SG_ 118 SteWhlCompAnEst_D_Qf 1;
BA_ "U_CD4_MY13_Hev_Tx" SG_ 118 SteWhlCompAnEst_D_Qf 1;
BA_ "U_CD4_MY13_Phev_Tx" SG_ 118 SteWhlCompAnEst_D_Qf 1;
BA_ "U_CD42_MY14_Diesel_Tx" SG_ 118 SteWhlCompAnEst_D_Qf 1;
BA_ "U_CD42_MY14_Gas_Tx" SG_ 118 SteWhlCompAnEst_D_Qf 1;
BA_ "U_P552_MY15_Gas_Tx" SG_ 118 SteWhlCompAnEst_D_Qf 1;
BA_ "U_S550_MY15_Gas_Tx" SG_ 118 SteWhlCompAnEst_D_Qf 1;
BA_ "U_C489_MY14_Gas_Tx" SG_ 118 SteWhlCompAnEst_D_Qf 1;
BA_ "U_B562LC_MY14_Diesel_Tx" SG_ 118 SteWhlCompAnEst_D_Qf 1;
BA_ "U_B562LC_MY14_Gas_Tx" SG_ 118 SteWhlCompAnEst_D_Qf 1;
BA_ "U_U502_MY15_Gas_Tx" SG_ 118 SteWhlCompAnEst_D_Qf 1;
BA_ "U_UP375_MY15_Gas_Tx" SG_ 118 SteWhlCompAnEst_D_Qf 1;
BA_ "U_UP375_MY15_Diesel_Tx" SG_ 118 SteWhlCompAnEst_D_Qf 1;
BA_ "U_CD43_MY16_Gas_Tx" SG_ 118 SteWhlCompAnEst_D_Qf 1;
BA_ "CrossOver_InfoCAN" SG_ 118 VehDynamicsSOS 1;
BA_ "U_CD4_MY13_Diesel_Tx" SG_ 118 VehDynamicsSOS 1;
BA_ "U_CD4_MY13_Gas_Tx" SG_ 118 VehDynamicsSOS 1;
BA_ "U_CD4_MY13_Hev_Tx" SG_ 118 VehDynamicsSOS 1;
BA_ "U_CD4_MY13_Phev_Tx" SG_ 118 VehDynamicsSOS 1;
BA_ "U_CD42_MY14_Diesel_Tx" SG_ 118 VehDynamicsSOS 1;
BA_ "U_CD42_MY14_Gas_Tx" SG_ 118 VehDynamicsSOS 1;
BA_ "U_P552_MY15_Gas_Tx" SG_ 118 VehDynamicsSOS 1;
BA_ "U_S550_MY15_Gas_Tx" SG_ 118 VehDynamicsSOS 1;
BA_ "U_C489_MY14_Gas_Tx" SG_ 118 VehDynamicsSOS 1;
BA_ "U_B562LC_MY14_Diesel_Tx" SG_ 118 VehDynamicsSOS 1;
BA_ "U_B562LC_MY14_Gas_Tx" SG_ 118 VehDynamicsSOS 1;
BA_ "U_U502_MY15_Gas_Tx" SG_ 118 VehDynamicsSOS 1;
BA_ "U_UP375_MY15_Gas_Tx" SG_ 118 VehDynamicsSOS 1;
BA_ "U_UP375_MY15_Diesel_Tx" SG_ 118 VehDynamicsSOS 1;
BA_ "U_CD43_MY16_Gas_Tx" SG_ 118 VehDynamicsSOS 1;
BA_ "GenSigSendType" SG_ 1713 UUDTABSResponse2 3;
BA_ "U_CD4_MY13_Diesel_Tx" SG_ 1713 UUDTABSResponse2 1;
BA_ "U_CD4_MY13_Gas_Tx" SG_ 1713 UUDTABSResponse2 1;
BA_ "U_CD4_MY13_Hev_Tx" SG_ 1713 UUDTABSResponse2 1;
BA_ "U_CD4_MY13_Phev_Tx" SG_ 1713 UUDTABSResponse2 1;
BA_ "U_CD42_MY14_Diesel_Tx" SG_ 1713 UUDTABSResponse2 1;
BA_ "U_CD42_MY14_Gas_Tx" SG_ 1713 UUDTABSResponse2 1;
BA_ "U_P552_MY15_Gas_Tx" SG_ 1713 UUDTABSResponse2 1;
BA_ "U_S550_MY15_Gas_Tx" SG_ 1713 UUDTABSResponse2 1;
BA_ "U_C489_MY14_Gas_Tx" SG_ 1713 UUDTABSResponse2 1;
BA_ "U_B562LC_MY14_Diesel_Tx" SG_ 1713 UUDTABSResponse2 1;
BA_ "U_B562LC_MY14_Gas_Tx" SG_ 1713 UUDTABSResponse2 1;
BA_ "U_U502_MY15_Gas_Tx" SG_ 1713 UUDTABSResponse2 1;
BA_ "U_UP375_MY15_Gas_Tx" SG_ 1713 UUDTABSResponse2 1;
BA_ "U_UP375_MY15_Diesel_Tx" SG_ 1713 UUDTABSResponse2 1;
BA_ "U_CD43_MY16_Gas_Tx" SG_ 1713 UUDTABSResponse2 1;
BA_ "GenSigSendType" SG_ 1712 UUDTABSResponse1 3;
BA_ "U_CD4_MY13_Diesel_Tx" SG_ 1712 UUDTABSResponse1 1;
BA_ "U_CD4_MY13_Gas_Tx" SG_ 1712 UUDTABSResponse1 1;
BA_ "U_CD4_MY13_Hev_Tx" SG_ 1712 UUDTABSResponse1 1;
BA_ "U_CD4_MY13_Phev_Tx" SG_ 1712 UUDTABSResponse1 1;
BA_ "U_CD42_MY14_Diesel_Tx" SG_ 1712 UUDTABSResponse1 1;
BA_ "U_CD42_MY14_Gas_Tx" SG_ 1712 UUDTABSResponse1 1;
BA_ "U_P552_MY15_Gas_Tx" SG_ 1712 UUDTABSResponse1 1;
BA_ "U_S550_MY15_Gas_Tx" SG_ 1712 UUDTABSResponse1 1;
BA_ "U_C489_MY14_Gas_Tx" SG_ 1712 UUDTABSResponse1 1;
BA_ "U_B562LC_MY14_Diesel_Tx" SG_ 1712 UUDTABSResponse1 1;
BA_ "U_B562LC_MY14_Gas_Tx" SG_ 1712 UUDTABSResponse1 1;
BA_ "U_U502_MY15_Gas_Tx" SG_ 1712 UUDTABSResponse1 1;
BA_ "U_UP375_MY15_Gas_Tx" SG_ 1712 UUDTABSResponse1 1;
BA_ "U_UP375_MY15_Diesel_Tx" SG_ 1712 UUDTABSResponse1 1;
BA_ "U_CD43_MY16_Gas_Tx" SG_ 1712 UUDTABSResponse1 1;
BA_ "GenSigSendType" SG_ 75 VedsPasKneeBag_D_Ltchd 3;
BA_ "U_CD42_MY14_Diesel_Tx" SG_ 75 VedsPasKneeBag_D_Ltchd 1;
BA_ "U_CD42_MY14_Gas_Tx" SG_ 75 VedsPasKneeBag_D_Ltchd 1;
BA_ "U_P552_MY15_Gas_Tx" SG_ 75 VedsPasKneeBag_D_Ltchd 1;
BA_ "U_S550_MY15_Gas_Tx" SG_ 75 VedsPasKneeBag_D_Ltchd 1;
BA_ "U_C489_MY14_Gas_Tx" SG_ 75 VedsPasKneeBag_D_Ltchd 1;
BA_ "U_U502_MY15_Gas_Tx" SG_ 75 VedsPasKneeBag_D_Ltchd 1;
BA_ "U_UP375_MY15_Gas_Tx" SG_ 75 VedsPasKneeBag_D_Ltchd 1;
BA_ "U_UP375_MY15_Diesel_Tx" SG_ 75 VedsPasKneeBag_D_Ltchd 1;
BA_ "U_CD43_MY16_Gas_Tx" SG_ 75 VedsPasKneeBag_D_Ltchd 1;
BA_ "GenSigSendType" SG_ 75 VedsRw1mBckl_D_Ltchd 3;
BA_ "U_CD4_MY13_Diesel_Tx" SG_ 75 VedsRw1mBckl_D_Ltchd 1;
BA_ "U_CD4_MY13_Gas_Tx" SG_ 75 VedsRw1mBckl_D_Ltchd 1;
BA_ "U_CD4_MY13_Hev_Tx" SG_ 75 VedsRw1mBckl_D_Ltchd 1;
BA_ "U_CD4_MY13_Phev_Tx" SG_ 75 VedsRw1mBckl_D_Ltchd 1;
BA_ "U_CD42_MY14_Diesel_Tx" SG_ 75 VedsRw1mBckl_D_Ltchd 1;
BA_ "U_CD42_MY14_Gas_Tx" SG_ 75 VedsRw1mBckl_D_Ltchd 1;
BA_ "U_P552_MY15_Gas_Tx" SG_ 75 VedsRw1mBckl_D_Ltchd 1;
BA_ "U_S550_MY15_Gas_Tx" SG_ 75 VedsRw1mBckl_D_Ltchd 1;
BA_ "U_C489_MY14_Gas_Tx" SG_ 75 VedsRw1mBckl_D_Ltchd 1;
BA_ "U_U502_MY15_Gas_Tx" SG_ 75 VedsRw1mBckl_D_Ltchd 1;
BA_ "U_UP375_MY15_Gas_Tx" SG_ 75 VedsRw1mBckl_D_Ltchd 1;
BA_ "U_UP375_MY15_Diesel_Tx" SG_ 75 VedsRw1mBckl_D_Ltchd 1;
BA_ "U_CD43_MY16_Gas_Tx" SG_ 75 VedsRw1mBckl_D_Ltchd 1;
BA_ "GenSigSendType" SG_ 75 VedsRw1mBelt_D_Ltchd 3;
BA_ "U_CD4_MY13_Diesel_Tx" SG_ 75 VedsRw1mBelt_D_Ltchd 1;
BA_ "U_CD4_MY13_Gas_Tx" SG_ 75 VedsRw1mBelt_D_Ltchd 1;
BA_ "U_CD4_MY13_Hev_Tx" SG_ 75 VedsRw1mBelt_D_Ltchd 1;
BA_ "U_CD4_MY13_Phev_Tx" SG_ 75 VedsRw1mBelt_D_Ltchd 1;
BA_ "U_CD42_MY14_Diesel_Tx" SG_ 75 VedsRw1mBelt_D_Ltchd 1;
BA_ "U_CD42_MY14_Gas_Tx" SG_ 75 VedsRw1mBelt_D_Ltchd 1;
BA_ "U_P552_MY15_Gas_Tx" SG_ 75 VedsRw1mBelt_D_Ltchd 1;
BA_ "U_S550_MY15_Gas_Tx" SG_ 75 VedsRw1mBelt_D_Ltchd 1;
BA_ "U_C489_MY14_Gas_Tx" SG_ 75 VedsRw1mBelt_D_Ltchd 1;
BA_ "U_U502_MY15_Gas_Tx" SG_ 75 VedsRw1mBelt_D_Ltchd 1;
BA_ "U_UP375_MY15_Gas_Tx" SG_ 75 VedsRw1mBelt_D_Ltchd 1;
BA_ "U_UP375_MY15_Diesel_Tx" SG_ 75 VedsRw1mBelt_D_Ltchd 1;
BA_ "U_CD43_MY16_Gas_Tx" SG_ 75 VedsRw1mBelt_D_Ltchd 1;
BA_ "GenSigSendType" SG_ 75 VedsRw2pRib_D_Ltchd 3;
BA_ "U_CD4_MY13_Diesel_Tx" SG_ 75 VedsRw2pRib_D_Ltchd 1;
BA_ "U_CD4_MY13_Gas_Tx" SG_ 75 VedsRw2pRib_D_Ltchd 1;
BA_ "U_CD4_MY13_Hev_Tx" SG_ 75 VedsRw2pRib_D_Ltchd 1;
BA_ "U_CD4_MY13_Phev_Tx" SG_ 75 VedsRw2pRib_D_Ltchd 1;
BA_ "U_CD42_MY14_Diesel_Tx" SG_ 75 VedsRw2pRib_D_Ltchd 1;
BA_ "U_CD42_MY14_Gas_Tx" SG_ 75 VedsRw2pRib_D_Ltchd 1;
BA_ "U_P552_MY15_Gas_Tx" SG_ 75 VedsRw2pRib_D_Ltchd 1;
BA_ "U_S550_MY15_Gas_Tx" SG_ 75 VedsRw2pRib_D_Ltchd 1;
BA_ "U_U502_MY15_Gas_Tx" SG_ 75 VedsRw2pRib_D_Ltchd 1;
BA_ "U_UP375_MY15_Gas_Tx" SG_ 75 VedsRw2pRib_D_Ltchd 1;
BA_ "U_UP375_MY15_Diesel_Tx" SG_ 75 VedsRw2pRib_D_Ltchd 1;
BA_ "U_CD43_MY16_Gas_Tx" SG_ 75 VedsRw2pRib_D_Ltchd 1;
BA_ "GenSigSendType" SG_ 75 VedsRw2dRib_D_Ltchd 3;
BA_ "U_CD4_MY13_Diesel_Tx" SG_ 75 VedsRw2dRib_D_Ltchd 1;
BA_ "U_CD4_MY13_Gas_Tx" SG_ 75 VedsRw2dRib_D_Ltchd 1;
BA_ "U_CD4_MY13_Hev_Tx" SG_ 75 VedsRw2dRib_D_Ltchd 1;
BA_ "U_CD4_MY13_Phev_Tx" SG_ 75 VedsRw2dRib_D_Ltchd 1;
BA_ "U_CD42_MY14_Diesel_Tx" SG_ 75 VedsRw2dRib_D_Ltchd 1;
BA_ "U_CD42_MY14_Gas_Tx" SG_ 75 VedsRw2dRib_D_Ltchd 1;
BA_ "U_P552_MY15_Gas_Tx" SG_ 75 VedsRw2dRib_D_Ltchd 1;
BA_ "U_S550_MY15_Gas_Tx" SG_ 75 VedsRw2dRib_D_Ltchd 1;
BA_ "U_U502_MY15_Gas_Tx" SG_ 75 VedsRw2dRib_D_Ltchd 1;
BA_ "U_UP375_MY15_Gas_Tx" SG_ 75 VedsRw2dRib_D_Ltchd 1;
BA_ "U_UP375_MY15_Diesel_Tx" SG_ 75 VedsRw2dRib_D_Ltchd 1;
BA_ "U_CD43_MY16_Gas_Tx" SG_ 75 VedsRw2dRib_D_Ltchd 1;
BA_ "GenSigSendType" SG_ 75 VedsRw3pBckl_D_Ltchd 3;
BA_ "U_CD4_MY13_Diesel_Tx" SG_ 75 VedsRw3pBckl_D_Ltchd 1;
BA_ "U_CD4_MY13_Gas_Tx" SG_ 75 VedsRw3pBckl_D_Ltchd 1;
BA_ "U_CD4_MY13_Hev_Tx" SG_ 75 VedsRw3pBckl_D_Ltchd 1;
BA_ "U_CD4_MY13_Phev_Tx" SG_ 75 VedsRw3pBckl_D_Ltchd 1;
BA_ "U_CD42_MY14_Diesel_Tx" SG_ 75 VedsRw3pBckl_D_Ltchd 1;
BA_ "U_CD42_MY14_Gas_Tx" SG_ 75 VedsRw3pBckl_D_Ltchd 1;
BA_ "U_P552_MY15_Gas_Tx" SG_ 75 VedsRw3pBckl_D_Ltchd 1;
BA_ "U_S550_MY15_Gas_Tx" SG_ 75 VedsRw3pBckl_D_Ltchd 1;
BA_ "U_U502_MY15_Gas_Tx" SG_ 75 VedsRw3pBckl_D_Ltchd 1;
BA_ "U_UP375_MY15_Gas_Tx" SG_ 75 VedsRw3pBckl_D_Ltchd 1;
BA_ "U_UP375_MY15_Diesel_Tx" SG_ 75 VedsRw3pBckl_D_Ltchd 1;
BA_ "U_CD43_MY16_Gas_Tx" SG_ 75 VedsRw3pBckl_D_Ltchd 1;
BA_ "GenSigSendType" SG_ 75 VedsRw3mBckl_D_Ltchd 3;
BA_ "U_CD4_MY13_Diesel_Tx" SG_ 75 VedsRw3mBckl_D_Ltchd 1;
BA_ "U_CD4_MY13_Gas_Tx" SG_ 75 VedsRw3mBckl_D_Ltchd 1;
BA_ "U_CD4_MY13_Hev_Tx" SG_ 75 VedsRw3mBckl_D_Ltchd 1;
BA_ "U_CD4_MY13_Phev_Tx" SG_ 75 VedsRw3mBckl_D_Ltchd 1;
BA_ "U_CD42_MY14_Diesel_Tx" SG_ 75 VedsRw3mBckl_D_Ltchd 1;
BA_ "U_CD42_MY14_Gas_Tx" SG_ 75 VedsRw3mBckl_D_Ltchd 1;
BA_ "U_P552_MY15_Gas_Tx" SG_ 75 VedsRw3mBckl_D_Ltchd 1;
BA_ "U_S550_MY15_Gas_Tx" SG_ 75 VedsRw3mBckl_D_Ltchd 1;
BA_ "U_U502_MY15_Gas_Tx" SG_ 75 VedsRw3mBckl_D_Ltchd 1;
BA_ "U_UP375_MY15_Gas_Tx" SG_ 75 VedsRw3mBckl_D_Ltchd 1;
BA_ "U_UP375_MY15_Diesel_Tx" SG_ 75 VedsRw3mBckl_D_Ltchd 1;
BA_ "U_CD43_MY16_Gas_Tx" SG_ 75 VedsRw3mBckl_D_Ltchd 1;
BA_ "GenSigSendType" SG_ 75 VedsRw3dBckl_D_Ltchd 3;
BA_ "U_CD4_MY13_Diesel_Tx" SG_ 75 VedsRw3dBckl_D_Ltchd 1;
BA_ "U_CD4_MY13_Gas_Tx" SG_ 75 VedsRw3dBckl_D_Ltchd 1;
BA_ "U_CD4_MY13_Hev_Tx" SG_ 75 VedsRw3dBckl_D_Ltchd 1;
BA_ "U_CD4_MY13_Phev_Tx" SG_ 75 VedsRw3dBckl_D_Ltchd 1;
BA_ "U_CD42_MY14_Diesel_Tx" SG_ 75 VedsRw3dBckl_D_Ltchd 1;
BA_ "U_CD42_MY14_Gas_Tx" SG_ 75 VedsRw3dBckl_D_Ltchd 1;
BA_ "U_P552_MY15_Gas_Tx" SG_ 75 VedsRw3dBckl_D_Ltchd 1;
BA_ "U_S550_MY15_Gas_Tx" SG_ 75 VedsRw3dBckl_D_Ltchd 1;
BA_ "U_U502_MY15_Gas_Tx" SG_ 75 VedsRw3dBckl_D_Ltchd 1;
BA_ "U_UP375_MY15_Gas_Tx" SG_ 75 VedsRw3dBckl_D_Ltchd 1;
BA_ "U_UP375_MY15_Diesel_Tx" SG_ 75 VedsRw3dBckl_D_Ltchd 1;
BA_ "U_CD43_MY16_Gas_Tx" SG_ 75 VedsRw3dBckl_D_Ltchd 1;
BA_ "GenSigSendType" SG_ 75 VedsRw2pBckl_D_Ltchd 3;
BA_ "U_CD4_MY13_Diesel_Tx" SG_ 75 VedsRw2pBckl_D_Ltchd 1;
BA_ "U_CD4_MY13_Gas_Tx" SG_ 75 VedsRw2pBckl_D_Ltchd 1;
BA_ "U_CD4_MY13_Hev_Tx" SG_ 75 VedsRw2pBckl_D_Ltchd 1;
BA_ "U_CD4_MY13_Phev_Tx" SG_ 75 VedsRw2pBckl_D_Ltchd 1;
BA_ "U_CD42_MY14_Diesel_Tx" SG_ 75 VedsRw2pBckl_D_Ltchd 1;
BA_ "U_CD42_MY14_Gas_Tx" SG_ 75 VedsRw2pBckl_D_Ltchd 1;
BA_ "U_P552_MY15_Gas_Tx" SG_ 75 VedsRw2pBckl_D_Ltchd 1;
BA_ "U_S550_MY15_Gas_Tx" SG_ 75 VedsRw2pBckl_D_Ltchd 1;
BA_ "U_U502_MY15_Gas_Tx" SG_ 75 VedsRw2pBckl_D_Ltchd 1;
BA_ "U_UP375_MY15_Gas_Tx" SG_ 75 VedsRw2pBckl_D_Ltchd 1;
BA_ "U_UP375_MY15_Diesel_Tx" SG_ 75 VedsRw2pBckl_D_Ltchd 1;
BA_ "U_CD43_MY16_Gas_Tx" SG_ 75 VedsRw2pBckl_D_Ltchd 1;
BA_ "GenSigSendType" SG_ 75 VedsRw2mBckl_D_Ltchd 3;
BA_ "U_CD4_MY13_Diesel_Tx" SG_ 75 VedsRw2mBckl_D_Ltchd 1;
BA_ "U_CD4_MY13_Gas_Tx" SG_ 75 VedsRw2mBckl_D_Ltchd 1;
BA_ "U_CD4_MY13_Hev_Tx" SG_ 75 VedsRw2mBckl_D_Ltchd 1;
BA_ "U_CD4_MY13_Phev_Tx" SG_ 75 VedsRw2mBckl_D_Ltchd 1;
BA_ "U_CD42_MY14_Diesel_Tx" SG_ 75 VedsRw2mBckl_D_Ltchd 1;
BA_ "U_CD42_MY14_Gas_Tx" SG_ 75 VedsRw2mBckl_D_Ltchd 1;
BA_ "U_P552_MY15_Gas_Tx" SG_ 75 VedsRw2mBckl_D_Ltchd 1;
BA_ "U_S550_MY15_Gas_Tx" SG_ 75 VedsRw2mBckl_D_Ltchd 1;
BA_ "U_U502_MY15_Gas_Tx" SG_ 75 VedsRw2mBckl_D_Ltchd 1;
BA_ "U_UP375_MY15_Gas_Tx" SG_ 75 VedsRw2mBckl_D_Ltchd 1;
BA_ "U_UP375_MY15_Diesel_Tx" SG_ 75 VedsRw2mBckl_D_Ltchd 1;
BA_ "U_CD43_MY16_Gas_Tx" SG_ 75 VedsRw2mBckl_D_Ltchd 1;
BA_ "GenSigSendType" SG_ 75 VedsRw2dBckl_D_Ltchd 3;
BA_ "U_CD4_MY13_Diesel_Tx" SG_ 75 VedsRw2dBckl_D_Ltchd 1;
BA_ "U_CD4_MY13_Gas_Tx" SG_ 75 VedsRw2dBckl_D_Ltchd 1;
BA_ "U_CD4_MY13_Hev_Tx" SG_ 75 VedsRw2dBckl_D_Ltchd 1;
BA_ "U_CD4_MY13_Phev_Tx" SG_ 75 VedsRw2dBckl_D_Ltchd 1;
BA_ "U_CD42_MY14_Diesel_Tx" SG_ 75 VedsRw2dBckl_D_Ltchd 1;
BA_ "U_CD42_MY14_Gas_Tx" SG_ 75 VedsRw2dBckl_D_Ltchd 1;
BA_ "U_P552_MY15_Gas_Tx" SG_ 75 VedsRw2dBckl_D_Ltchd 1;
BA_ "U_S550_MY15_Gas_Tx" SG_ 75 VedsRw2dBckl_D_Ltchd 1;
BA_ "U_U502_MY15_Gas_Tx" SG_ 75 VedsRw2dBckl_D_Ltchd 1;
BA_ "U_UP375_MY15_Gas_Tx" SG_ 75 VedsRw2dBckl_D_Ltchd 1;
BA_ "U_UP375_MY15_Diesel_Tx" SG_ 75 VedsRw2dBckl_D_Ltchd 1;
BA_ "U_CD43_MY16_Gas_Tx" SG_ 75 VedsRw2dBckl_D_Ltchd 1;
BA_ "GenSigSendType" SG_ 75 VedsRw1PasChld_D_Ltchd 3;
BA_ "U_CD4_MY13_Diesel_Tx" SG_ 75 VedsRw1PasChld_D_Ltchd 1;
BA_ "U_CD4_MY13_Gas_Tx" SG_ 75 VedsRw1PasChld_D_Ltchd 1;
BA_ "U_CD4_MY13_Hev_Tx" SG_ 75 VedsRw1PasChld_D_Ltchd 1;
BA_ "U_CD4_MY13_Phev_Tx" SG_ 75 VedsRw1PasChld_D_Ltchd 1;
BA_ "U_CD42_MY14_Diesel_Tx" SG_ 75 VedsRw1PasChld_D_Ltchd 1;
BA_ "U_CD42_MY14_Gas_Tx" SG_ 75 VedsRw1PasChld_D_Ltchd 1;
BA_ "U_P552_MY15_Gas_Tx" SG_ 75 VedsRw1PasChld_D_Ltchd 1;
BA_ "U_S550_MY15_Gas_Tx" SG_ 75 VedsRw1PasChld_D_Ltchd 1;
BA_ "U_C489_MY14_Gas_Tx" SG_ 75 VedsRw1PasChld_D_Ltchd 1;
BA_ "U_U502_MY15_Gas_Tx" SG_ 75 VedsRw1PasChld_D_Ltchd 1;
BA_ "U_UP375_MY15_Gas_Tx" SG_ 75 VedsRw1PasChld_D_Ltchd 1;
BA_ "U_UP375_MY15_Diesel_Tx" SG_ 75 VedsRw1PasChld_D_Ltchd 1;
BA_ "U_CD43_MY16_Gas_Tx" SG_ 75 VedsRw1PasChld_D_Ltchd 1;
BA_ "GenSigSendType" SG_ 75 VedsRw1PasBckl_D_Ltchd 3;
BA_ "U_CD4_MY13_Diesel_Tx" SG_ 75 VedsRw1PasBckl_D_Ltchd 1;
BA_ "U_CD4_MY13_Gas_Tx" SG_ 75 VedsRw1PasBckl_D_Ltchd 1;
BA_ "U_CD4_MY13_Hev_Tx" SG_ 75 VedsRw1PasBckl_D_Ltchd 1;
BA_ "U_CD4_MY13_Phev_Tx" SG_ 75 VedsRw1PasBckl_D_Ltchd 1;
BA_ "U_CD42_MY14_Diesel_Tx" SG_ 75 VedsRw1PasBckl_D_Ltchd 1;
BA_ "U_CD42_MY14_Gas_Tx" SG_ 75 VedsRw1PasBckl_D_Ltchd 1;
BA_ "U_P552_MY15_Gas_Tx" SG_ 75 VedsRw1PasBckl_D_Ltchd 1;
BA_ "U_S550_MY15_Gas_Tx" SG_ 75 VedsRw1PasBckl_D_Ltchd 1;
BA_ "U_C489_MY14_Gas_Tx" SG_ 75 VedsRw1PasBckl_D_Ltchd 1;
BA_ "U_U502_MY15_Gas_Tx" SG_ 75 VedsRw1PasBckl_D_Ltchd 1;
BA_ "U_UP375_MY15_Gas_Tx" SG_ 75 VedsRw1PasBckl_D_Ltchd 1;
BA_ "U_UP375_MY15_Diesel_Tx" SG_ 75 VedsRw1PasBckl_D_Ltchd 1;
BA_ "U_CD43_MY16_Gas_Tx" SG_ 75 VedsRw1PasBckl_D_Ltchd 1;
BA_ "GenSigSendType" SG_ 75 VedsRw1DrvBckl_D_Ltchd 3;
BA_ "U_CD4_MY13_Diesel_Tx" SG_ 75 VedsRw1DrvBckl_D_Ltchd 1;
BA_ "U_CD4_MY13_Gas_Tx" SG_ 75 VedsRw1DrvBckl_D_Ltchd 1;
BA_ "U_CD4_MY13_Hev_Tx" SG_ 75 VedsRw1DrvBckl_D_Ltchd 1;
BA_ "U_CD4_MY13_Phev_Tx" SG_ 75 VedsRw1DrvBckl_D_Ltchd 1;
BA_ "U_CD42_MY14_Diesel_Tx" SG_ 75 VedsRw1DrvBckl_D_Ltchd 1;
BA_ "U_CD42_MY14_Gas_Tx" SG_ 75 VedsRw1DrvBckl_D_Ltchd 1;
BA_ "U_P552_MY15_Gas_Tx" SG_ 75 VedsRw1DrvBckl_D_Ltchd 1;
BA_ "U_S550_MY15_Gas_Tx" SG_ 75 VedsRw1DrvBckl_D_Ltchd 1;
BA_ "U_C489_MY14_Gas_Tx" SG_ 75 VedsRw1DrvBckl_D_Ltchd 1;
BA_ "U_U502_MY15_Gas_Tx" SG_ 75 VedsRw1DrvBckl_D_Ltchd 1;
BA_ "U_UP375_MY15_Gas_Tx" SG_ 75 VedsRw1DrvBckl_D_Ltchd 1;
BA_ "U_UP375_MY15_Diesel_Tx" SG_ 75 VedsRw1DrvBckl_D_Ltchd 1;
BA_ "U_CD43_MY16_Gas_Tx" SG_ 75 VedsRw1DrvBckl_D_Ltchd 1;
VAL_ 376 PtcHtr_D_Cmd 3 "TurnOn" 2 "AutoMode" 1 "TurnOff" 0 "NoDecision_Initializing" ;
VAL_ 376 GasPrtc_D_RqDsply 7 "NotUsed_5" 6 "NotUsed_4" 5 "NotUsed_3" 4 "NotUsed_2" 3 "NotUsed_1" 2 "GpfOverLimit" 1 "GpfAtLimit" 0 "NormalOperation" ;
VAL_ 376 AslIconDsply_D_Rq 3 "Not_Used" 2 "On_Active" 1 "On_Passive" 0 "Off" ;
VAL_ 376 AslChime_B_Rq 1 "Yes" 0 "No" ;
VAL_ 376 DynoMde_B_Cmd 1 "Two_Wheel_Dyno" 0 "Normal_Operation" ;
VAL_ 376 AirAmbTe_D_Qf 3 "OK" 2 "Not_Within_Specifications" 1 "No_Data_Exists" 0 "Faulty" ;
VAL_ 376 AirAmb_P_Actl 63 "Fault" 62 "NoDataExists" ;
VAL_ 516 ApedPos_PcRate_ActlArb 255 "Fault" 254 "Unknown" ;
VAL_ 516 ApedPosPcActl_D_Qf 3 "OK" 2 "Not_Within_Specifications" 1 "No_Data_Exists" 0 "Faulty" ;
VAL_ 514 VehVTrlrAid_B_Avail 1 "Yes" 0 "No" ;
VAL_ 514 StrtrMtrCtlMsgTxt_D_Rq 15 "Message_15" 14 "Message_14" 13 "Message_13" 12 "Message_12" 11 "Message_11" 10 "Message_10" 9 "Message_9" 8 "Message_8" 7 "Message_7" 6 "Message_6" 5 "Message_5" 4 "Message_4" 3 "Message_3" 2 "Message_2" 1 "Message_1" 0 "NoMessage" ;
VAL_ 514 VehVActlEng_D_Qf 3 "OK" 2 "Not_Within_Specifications" 1 "No_Data_Exists" 0 "Faulty" ;
VAL_ 514 GearRvrse_D_Actl 7 "Fault" 6 "NotUsed_3" 5 "NotUsed_2" 4 "NotUsed_1" 3 "Active_confirmed" 2 "Active_not_confirmed" 1 "Inactive_confirmed" 0 "Inactive_not_confirmed" ;
VAL_ 1003 PersRecallSrc_D_Actl 7 "NotUsed_3" 6 "NotUsed_2" 5 "NotUsed_1" 4 "MemorySwitch" 3 "RemoteStart" 2 "KeyFob" 1 "CenterStack" 0 "Null" ;
VAL_ 1003 Pers4Key_D_Stat 3 "NotUsed" 2 "KeyUnassociated" 1 "KeyAssociated" 0 "Null" ;
VAL_ 1003 Pers3Key_D_Stat 3 "NotUsed" 2 "KeyUnassociated" 1 "KeyAssociated" 0 "Null" ;
VAL_ 1003 Pers2Key_D_Stat 3 "NotUsed" 2 "KeyUnassociated" 1 "KeyAssociated" 0 "Null" ;
VAL_ 1003 Pers1Key_D_Stat 3 "NotUsed" 2 "KeyUnassociated" 1 "KeyAssociated" 0 "Null" ;
VAL_ 1003 EmPrflNo_D_Stat 7 "Unused_3" 6 "Unused_2" 5 "Unused_1" 4 "PERS_4" 3 "PERS_3" 2 "PERS_2" 1 "PERS_1" 0 "Null" ;
VAL_ 1003 EmPrflKeyAssoc_D_Stat 7 "WrongDevice" 6 "KeyAssociateFailed" 5 "KeyAssociateSuccess" 4 "KeyAlreadyInUse" 3 "KeyDisassociated" 2 "KeyAssociationExited" 1 "KeyAssociationEntered" 0 "Null" ;
VAL_ 1003 VehKeyActv_D_Stat 15 "NotUsed7" 14 "NotUsed6" 13 "NotUsed5" 12 "NotUsed4" 11 "NotUsed3" 10 "NotUsed2" 9 "NotUsed1" 8 "Key8Active" 7 "Key7Active" 6 "Key6Active" 5 "Key5Active" 4 "Key4Active" 3 "Key3Active" 2 "Key2Active" 1 "Key1Active" 0 "NoKeyActive" ;
VAL_ 1003 PersNoPos_D_Actl 7 "Unused_3" 6 "Unused_2" 5 "Unused_1" 4 "Vehicle" 3 "PERS_4" 2 "PERS_3" 1 "PERS_2" 0 "PERS_1" ;
VAL_ 1003 PersSetupRestr_D_Actl 3 "Non_Moveable_Person" 2 "Moveable_Person" 1 "Vehicle" 0 "Factory" ;
VAL_ 1003 PersSetupAccessCtrl 1 "Limited" 0 "Full" ;
VAL_ 1003 PersConflict_D_Actl 1 "Conflict" 0 "No_Conflict" ;
VAL_ 1003 AssocConfirm_D_Actl 0 "None" 7 "Associate" 6 "Keycode_Rejected" 5 "Keycode_Accepted" 4 "In_Progress" 3 "Erase" 2 "Duplicate" 1 "Disassociate" ;
VAL_ 1003 PersNo_D_Actl 7 "Unused_3" 6 "Unused_2" 5 "Unused_1" 4 "Vehicle" 3 "PERS_4" 2 "PERS_3" 1 "PERS_2" 0 "PERS_1" ;
VAL_ 963 WrlssAcsyChrgInhbt_B_Rq 1 "Yes" 0 "No" ;
VAL_ 963 PudLampPsngr_D_Rq 3 "Ramp_Down" 2 "Ramp_Up" 1 "On" 0 "Off" ;
VAL_ 963 PudLampDrv_D_Rq 3 "Ramp_Down" 2 "Ramp_Up" 1 "On" 0 "Off" ;
VAL_ 963 Illuminated_Entry_Stat 3 "Invalid" 2 "Unknown" 1 "On" 0 "Off" ;
VAL_ 963 Dr_Courtesy_Light_Stat 3 "Invalid" 2 "Unknown" 1 "On" 0 "Off" ;
VAL_ 963 DrTgateLck_D_Stat 3 "NotUsed" 2 "Unlock" 1 "Lock" 0 "Null" ;
VAL_ 963 Courtesy_Delay_Status 3 "Invalid" 2 "Unknown" 1 "On" 0 "Off" ;
VAL_ 963 ImpactEvntFdbck_D_Stat 3 "NotUsed" 2 "EventComplete" 1 "EventInProgress" 0 "Normal" ;
VAL_ 963 HeadLampLoOut_B_Stat 1 "Out" 0 "Null" ;
VAL_ 963 HeadLghtHiFdbck_D_Stat 3 "NotUsed" 2 "Cancel" 1 "Hold" 0 "Allow_Change" ;
VAL_ 963 PrkLightChime_B_Rq 1 "On" 0 "Off" ;
VAL_ 963 TrnNotInPrkChime_B_Rq 1 "On" 0 "Off" ;
VAL_ 963 KeyInIgnWarn_B_Cmd 1 "On" 0 "Off" ;
VAL_ 963 HomeSafeLtChime_B_Rq 1 "On" 0 "Off" ;
VAL_ 963 StopLghtOn_B_Stat 1 "On" 0 "Off" ;
VAL_ 963 RvrseLghtOn_B_Stat 1 "On" 0 "Off" ;
VAL_ 963 PrkLght_D_Stat 3 "Park_Both" 2 "Park_Right" 1 "Park_Left" 0 "Off" ;
VAL_ 963 HeadLghtSwtch_D_Stat 3 "Autolamp" 2 "Headlamp" 1 "Parklamp" 0 "Off" ;
VAL_ 963 HeadLampLoFrOn_B_Stat 1 "Low" 0 "Not_Low" ;
VAL_ 963 HeadLampLoFlOn_B_Stat 1 "Low" 0 "Not_Low" ;
VAL_ 963 HeadLampLoActv_B_Stat 1 "On" 0 "Off" ;
VAL_ 963 Headlamp_On_Wrning_Cmd 1 "On" 0 "Off" ;
VAL_ 963 HeadLghtHiOn_B_Stat 1 "On" 0 "Off" ;
VAL_ 963 Park_Brake_Chime_Rqst 1 "On" 0 "Off" ;
VAL_ 963 BrkWarnInd_B_Rq 1 "On" 0 "Off" ;
VAL_ 963 Brk_Fluid_Lvl_Low 3 "Invalid" 2 "Unknown" 1 "Low" 0 "OK" ;
VAL_ 963 ReducedGuard_D_Stat 3 "NotUsed" 2 "Alarm_On" 1 "Alarm_Off_Previously_On" 0 "Alarm_Off" ;
VAL_ 963 Perimeter_Alarm_Status 3 "Activated" 2 "Armed" 1 "Prearmed" 0 "Disarmed" ;
VAL_ 963 Courtesy_BSave_Stat 3 "Invalid" 2 "Unknown" 1 "No_Effect" 0 "Off" ;
VAL_ 963 DayRnngLampOn_B_Stat 1 "On" 0 "Off" ;
VAL_ 963 WndwGlbl_D_Cmd 7 "NotUsed3" 6 "NotUsed2" 5 "NotUsed1" 4 "GLEARN" 3 "GCLOSE" 2 "GOPEN" 1 "GSTOP" 0 "Null" ;
VAL_ 963 PudLamp_D_Rq 3 "RAMP_DOWN" 2 "RAMP_UP" 1 "ON" 0 "OFF" ;
VAL_ 963 PerimeterAlarmChimeRq 1 "On" 0 "Off" ;
VAL_ 972 LsmcBrkDecelEnbl_D_Rq 3 "NotUsed2" 2 "NotUsed1" 1 "On" 0 "Off" ;
VAL_ 972 LaHandsOff_B_Actl 1 "Hands_Off" 0 "Hands_On" ;
VAL_ 972 LaActDeny_B_Actl 1 "LA_Denied" 0 "LA_Not_Denied" ;
VAL_ 972 LaActAvail_D_Actl 3 "LKA_LCA_LDW_Avail" 2 "LCA_LKA_Avail_LDW_Suppress" 1 "LCA_LKA_Suppress_LDW_Avail" 0 "LCA_LKA_LDW_Suppress" ;
VAL_ 133 SteWhlRelCalib_An_Sns 32767 "Fault" 32766 "NoDataExists" ;
VAL_ 133 SteWhlRelInit2_An_Sns 65535 "Fault" 65534 "Unknown" ;
VAL_ 133 StePw_B_Rq 1 "Yes" 0 "No" ;
VAL_ 133 SteWhlOSRelInit2An_Est 65535 "Fault" 65534 "Unknown" ;
VAL_ 391 HudBlk3_B_Rq 1 "Yes" 0 "No" ;
VAL_ 391 HudBlk2_B_Rq 1 "Yes" 0 "No" ;
VAL_ 391 HudBlk1_B_Rq 1 "Yes" 0 "No" ;
VAL_ 391 HudFlashRate_D_Actl 3 "Unused" 2 "Flash_4Hz_50Prct_DutyCycle" 1 "On" 0 "Off" ;
VAL_ 391 CmbbBrkPrchg_D_Rq 3 "Undefined" 2 "Level_2_PreCharge_Request" 1 "Level_1_PreCharge_Request" 0 "No_PreCharge_Request" ;
VAL_ 391 CmbbBrkDecel_B_Rq 1 "Yes" 0 "No" ;
VAL_ 391 CmbbBaSens_D_Rq 3 "Level_3" 2 "Level_2" 1 "Level_1" 0 "Normal" ;
VAL_ 535 WhlRr_W_Meas 32767 "Fault" 32766 "Unknown" ;
VAL_ 535 WhlRl_W_Meas 32767 "Fault" 32766 "Unknown" ;
VAL_ 535 WhlFr_W_Meas 32767 "Fault" 32766 "Unknown" ;
VAL_ 535 WhlFl_W_Meas 32767 "Fault" 32766 "Unknown" ;
VAL_ 531 VehicleStationary 1 "Yes" 0 "No" ;
VAL_ 531 VehStop_D_Stat 3 "Faulty" 2 "NoDataExists" 1 "Yes" 0 "No" ;
VAL_ 531 AccStopActv_B_ActlBrk 1 "Yes" 0 "No" ;
VAL_ 531 AccDis_B_ActlEpb 1 "Yes" 0 "No" ;
VAL_ 531 PrkBrkYwLamp_D_Rq 3 "Fast_Flash" 2 "Slow_Flash" 1 "On" 0 "Off" ;
VAL_ 531 PrkBrkRedLamp_D_Rq 3 "Fast_Flash" 2 "Slow_Flash" 1 "On" 0 "Off" ;
VAL_ 531 PrkBrkMsgTxt_D_Rq 15 "Message15" 14 "Message14" 13 "Message13" 12 "Message12" 11 "Message11" 10 "Message10" 9 "Message9" 8 "Message8" 7 "Message7" 6 "Message6" 5 "Message5" 4 "Message4" 3 "Message3" 2 "Message2" 1 "Message1" 0 "No_Message" ;
VAL_ 531 TracCtlPtActv_B_Actl 1 "Active" 0 "Inactive" ;
VAL_ 531 AbsActv_B_Actl 1 "Yes" 0 "No" ;
VAL_ 531 StabCtlBrkActv_B_Actl 1 "Yes" 0 "No" ;
VAL_ 531 CmbbBrkPrchg_B_Actl 1 "Yes" 0 "No" ;
VAL_ 531 CmbbBrkDecel_B_Actl 1 "Yes" 0 "No" ;
VAL_ 531 CmbbBaSensInc_B_Actl 1 "Yes" 0 "No" ;
VAL_ 531 AccBrkWarm_B_Actl 1 "Yes" 0 "No" ;
VAL_ 531 AccBrkTotTqMn_B_Actl 1 "Yes" 0 "No" ;
VAL_ 531 AccBrkPrchgActv_B_Actl 1 "Yes" 0 "No" ;
VAL_ 531 AccBrkDis_B_Actl 1 "Yes" 0 "No" ;
VAL_ 531 AccBrkDeny_B_Actl 1 "Yes" 0 "No" ;
VAL_ 531 AccBrkActv_B_Actl 1 "Yes" 0 "No" ;
VAL_ 531 PrplDrgCtlActv_B_Actl 1 "Active" 0 "Inactive" ;
VAL_ 531 CmbbBrkDis_B_Actl 1 "Yes" 0 "No" ;
VAL_ 531 CmbbDeny_B_ActlBrk 1 "Yes" 0 "No" ;
VAL_ 531 CcDis_B_Cmd 1 "Yes" 0 "No" ;
VAL_ 531 VehLongOvrGnd_A_Est 1023 "Fault" 1022 "Unknown" ;
VAL_ 531 PrkBrkStatus 7 "GeneralFault_MaintenceMode" 6 "ECD_by_Brake_ECU_Active" 5 "EPB_Limphome_Active" 4 "Rear_Caliper_Open" 3 "RWU_By_EPB_Active" 2 "Rear_Caliper_Transition" 1 "Rear_Caliper_Closed" 0 "Not_Supported" ;
VAL_ 125 VehRolComp_W_Actl 4094 "NoDataExists" 4095 "Fault" ;
VAL_ 125 VehVertComp_A_Actl 1022 "NoDataExists" 1023 "Fault" ;
VAL_ 125 BrkTot_Tq_RqArb 8191 "Fault" 8190 "Unknown" ;
VAL_ 125 BrkTot_Tq_Actl 8191 "Fault" 8190 "Unknown" ;
VAL_ 125 HsaStat_D_Actl 7 "Undefined" 6 "Failed" 5 "SlowRelease" 4 "FastRelease" 3 "ActiveBrakePedalReleased" 2 "ActiveBrakePedalPressed" 1 "FindingGradient" 0 "Inactive" ;
VAL_ 119 VehOverGnd_V_Est 65535 "Invalid" 65534 "Unknown" ;
VAL_ 119 VehLongComp_A_Actl 1023 "Fault" 1022 "NoDataExists" ;
VAL_ 119 VehLatComp_A_Actl 1023 "Fault" 1022 "NoDataExists" ;
VAL_ 119 VehYawComp_W_Actl 4095 "Fault" 4094 "NoDataExists" ;
VAL_ 118 BrkCtrFnd_B_Stat 1 "Yes" 0 "No" ;
VAL_ 118 EmgcyBrkLamp_D_Rq 3 "NotUsed" 2 "Active_at_standstill" 1 "Active_at_speed" 0 "Inactive" ;
VAL_ 118 StopLamp_B_RqBrk 1 "Active" 0 "Inactive" ;
VAL_ 118 SteWhlCompAnEst_D_Qf 3 "OK" 2 "Not_Within_Specifications" 1 "No_Data_Exists" 0 "Faulty" ;
VAL_ 118 VehDynamicsSOS 1 "Yes" 0 "No" ;
VAL_ 75 VedsPasKneeBag_D_Ltchd 7 "Fault" 6 "NotSupported" 5 "Unused_3" 4 "Unused_2" 3 "Unused_1" 2 "NotDeployed" 1 "Deployed" 0 "NoEvent" ;
VAL_ 75 VedsRw1mBckl_D_Ltchd 5 "Unused_3" 4 "Unused_2" 3 "Unused_1" 2 "NotBelted" 1 "Belted" 0 "NoEvent" 7 "Fault" 6 "NotSupported" ;
VAL_ 75 VedsRw1mBelt_D_Ltchd 7 "Fault" 6 "NotSupported" 5 "Unused_3" 4 "Unused_2" 3 "Unused_1" 2 "NotDeployed" 1 "Deployed" 0 "NoEvent" ;
VAL_ 75 VedsRw2pRib_D_Ltchd 7 "Fault" 6 "NotSupported" 5 "Unused_3" 4 "Unused_2" 3 "Unused_1" 2 "NotDeployed" 1 "Deployed" 0 "NoEvent" ;
VAL_ 75 VedsRw2dRib_D_Ltchd 7 "Fault" 6 "NotSupported" 5 "Unused_3" 4 "Unused_2" 3 "Unused_1" 2 "NotDeployed" 1 "Deployed" 0 "NoEvent" ;
VAL_ 75 VedsRw3pBckl_D_Ltchd 5 "Unused_3" 4 "Unused_2" 3 "Unused_1" 2 "NotBelted" 1 "Belted" 0 "NoEvent" 7 "Fault" 6 "NotSupported" ;
VAL_ 75 VedsRw3mBckl_D_Ltchd 5 "Unused_3" 4 "Unused_2" 3 "Unused_1" 2 "NotBelted" 1 "Belted" 0 "NoEvent" 7 "Fault" 6 "NotSupported" ;
VAL_ 75 VedsRw3dBckl_D_Ltchd 5 "Unused_3" 4 "Unused_2" 3 "Unused_1" 2 "NotBelted" 1 "Belted" 0 "NoEvent" 7 "Fault" 6 "NotSupported" ;
VAL_ 75 VedsRw2pBckl_D_Ltchd 5 "Unused_3" 4 "Unused_2" 3 "Unused_1" 2 "NotBelted" 1 "Belted" 0 "NoEvent" 7 "Fault" 6 "NotSupported" ;
VAL_ 75 VedsRw2mBckl_D_Ltchd 5 "Unused_3" 4 "Unused_2" 3 "Unused_1" 2 "NotBelted" 1 "Belted" 0 "NoEvent" 7 "Fault" 6 "NotSupported" ;
VAL_ 75 VedsRw2dBckl_D_Ltchd 5 "Unused_3" 4 "Unused_2" 3 "Unused_1" 2 "NotBelted" 1 "Belted" 0 "NoEvent" 7 "Fault" 6 "NotSupported" ;
VAL_ 75 VedsRw1PasChld_D_Ltchd 7 "Fault" 6 "NotSupported" 5 "Unused_3" 4 "Unused_2" 3 "Unused_1" 2 "ChildNotDetected" 1 "ChildDetected" 0 "NoEvent" ;
VAL_ 75 VedsRw1PasBckl_D_Ltchd 5 "Unused_3" 4 "Unused_2" 3 "Unused_1" 2 "NotBelted" 1 "Belted" 0 "NoEvent" 7 "Fault" 6 "NotSupported" ;
VAL_ 75 VedsRw1DrvBckl_D_Ltchd 5 "Unused_3" 4 "Unused_2" 3 "Unused_1" 2 "NotBelted" 1 "Belted" 0 "NoEvent" 7 "Fault" 6 "NotSupported" ;
